VERSION ""

NS_ :

BS_:

BU_: RLPSU DPSU APSU PSB SHVU_RR vHS_B2 FCS EMCU SLB RCM CGW_CCU vDummy_HS_B ATS RLHV PFSU SGU ALBCU DSAU SWRC SHVU_FR RCS RRPSU BLTN_CAM SCM DLBCU OHCL RWPC RRHV WPC HOD ASAU

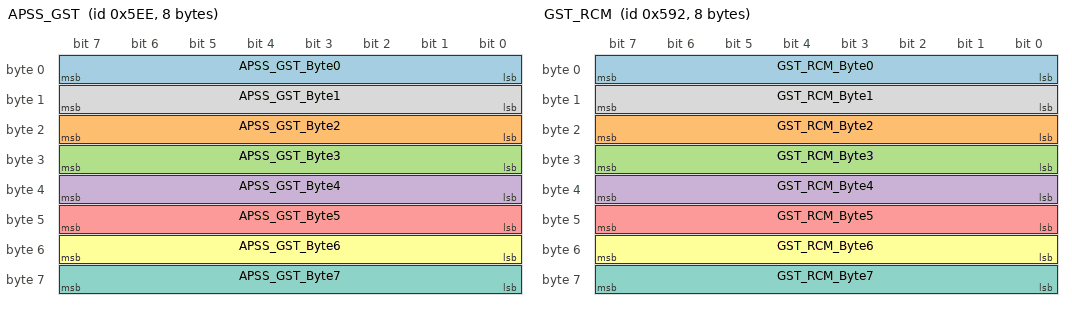
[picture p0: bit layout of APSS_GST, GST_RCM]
BO_ 1518 APSS_GST: 8 APSU
 SG_ APSS_GST_Byte0 : 0|8@1+ (1,0) [0|0] ""  CGW_CCU
 SG_ APSS_GST_Byte2 : 16|8@1+ (1,0) [0|0] ""  CGW_CCU
 SG_ APSS_GST_Byte3 : 24|8@1+ (1,0) [0|0] ""  CGW_CCU
 SG_ APSS_GST_Byte4 : 32|8@1+ (1,0) [0|0] ""  CGW_CCU
 SG_ APSS_GST_Byte5 : 40|8@1+ (1,0) [0|0] ""  CGW_CCU
 SG_ APSS_GST_Byte6 : 48|8@1+ (1,0) [0|0] ""  CGW_CCU
 SG_ APSS_GST_Byte7 : 56|8@1+ (1,0) [0|0] ""  CGW_CCU
 SG_ APSS_GST_Byte1 : 8|8@1+ (1,0) [0|0] ""  CGW_CCU

BO_ 1016 HU_GNSS_14_1000ms: 8 CGW_CCU
 SG_ GNSS_MM_type : 0|4@1+ (1,0) [0|0] ""  BLTN_CAM

BO_ 1426 GST_RCM: 8 CGW_CCU
 SG_ GST_RCM_Byte0 : 0|8@1+ (1,0) [0|0] ""  RCM
 SG_ GST_RCM_Byte2 : 16|8@1+ (1,0) [0|0] ""  RCM
 SG_ GST_RCM_Byte3 : 24|8@1+ (1,0) [0|0] ""  RCM
 SG_ GST_RCM_Byte4 : 32|8@1+ (1,0) [0|0] ""  RCM
 SG_ GST_RCM_Byte5 : 40|8@1+ (1,0) [0|0] ""  RCM
 SG_ GST_RCM_Byte6 : 48|8@1+ (1,0) [0|0] ""  RCM
 SG_ GST_RCM_Byte7 : 56|8@1+ (1,0) [0|0] ""  RCM
 SG_ GST_RCM_Byte1 : 8|8@1+ (1,0) [0|0] ""  RCM

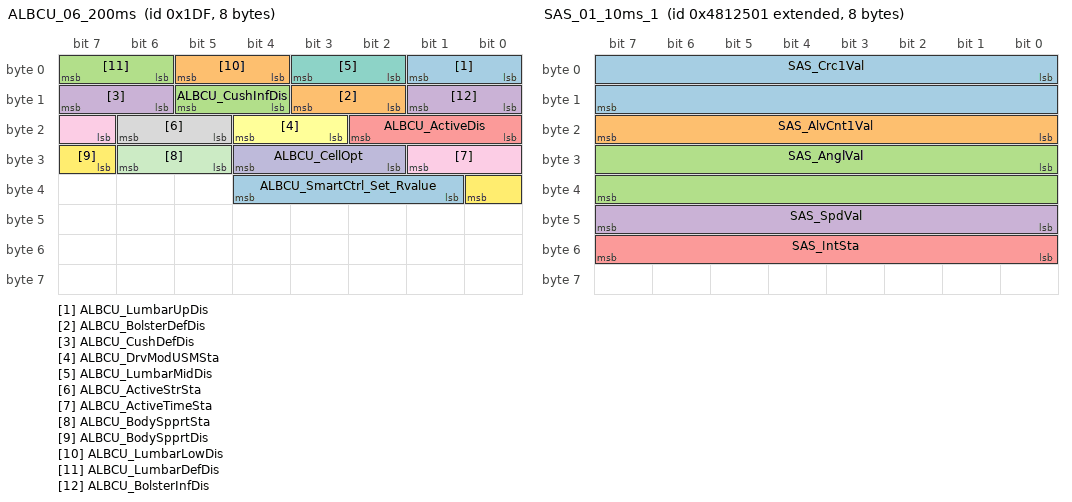
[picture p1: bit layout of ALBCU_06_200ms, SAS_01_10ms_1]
BO_ 479 ALBCU_06_200ms: 8 ALBCU
 SG_ ALBCU_LumbarUpDis : 0|2@1+ (1,0) [0|0] ""  Vector__XXX
 SG_ ALBCU_BolsterDefDis : 10|2@1+ (1,0) [0|0] ""  Vector__XXX
 SG_ ALBCU_CushInfDis : 12|2@1+ (1,0) [0|0] ""  Vector__XXX
 SG_ ALBCU_CushDefDis : 14|2@1+ (1,0) [0|0] ""  Vector__XXX
 SG_ ALBCU_ActiveDis : 16|3@1+ (1,0) [0|0] ""  CGW_CCU
 SG_ ALBCU_DrvModUSMSta : 19|2@1+ (1,0) [0|0] ""  CGW_CCU
 SG_ ALBCU_LumbarMidDis : 2|2@1+ (1,0) [0|0] ""  Vector__XXX
 SG_ ALBCU_ActiveStrSta : 21|2@1+ (1,0) [0|0] ""  CGW_CCU
 SG_ ALBCU_ActiveTimeSta : 23|3@1+ (1,0) [0|0] ""  CGW_CCU
 SG_ ALBCU_CellOpt : 26|3@1+ (1,0) [0|0] ""  CGW_CCU
 SG_ ALBCU_BodySpprtSta : 29|2@1+ (1,0) [0|0] ""  CGW_CCU
 SG_ ALBCU_BodySpprtDis : 31|2@1+ (1,0) [0|0] ""  Vector__XXX
 SG_ ALBCU_SmartCtrl_Set_Rvalue : 33|4@1+ (1,0) [0|0] ""  Vector__XXX
 SG_ ALBCU_LumbarLowDis : 4|2@1+ (1,0) [0|0] ""  Vector__XXX
 SG_ ALBCU_LumbarDefDis : 6|2@1+ (1,0) [0|0] ""  Vector__XXX
 SG_ ALBCU_BolsterInfDis : 8|2@1+ (1,0) [0|0] ""  Vector__XXX

BO_ 1019 HU_MOOD_E_01: 8 CGW_CCU
 SG_ HU_MoodTherapyDrSeat : 0|2@1+ (1,0) [0|0] ""  DSAU
 SG_ HU_VitalityFragrance : 10|2@1+ (1,0) [0|0] ""  Vector__XXX
 SG_ HU_VitalityCurtain : 12|2@1+ (1,0) [0|0] ""  Vector__XXX
 SG_ HU_DelightMoodLamp : 14|2@1+ (1,0) [0|0] ""  Vector__XXX
 SG_ HU_DelightFragrance : 16|2@1+ (1,0) [0|0] ""  Vector__XXX
 SG_ HU_DelightCurtain : 18|2@1+ (1,0) [0|0] ""  Vector__XXX
 SG_ HU_MoodTherapyPsSeat : 2|2@1+ (1,0) [0|0] ""  ASAU
 SG_ HU_CareMoodLamp : 20|2@1+ (1,0) [0|0] ""  Vector__XXX
 SG_ HU_CareFragrance : 22|2@1+ (1,0) [0|0] ""  Vector__XXX
 SG_ HU_CareMassage : 24|2@1+ (1,0) [0|0] ""  DSAU,ASAU
 SG_ HU_CareCurtain : 26|2@1+ (1,0) [0|0] ""  Vector__XXX
 SG_ HU_ComfortMoodLamp : 28|2@1+ (1,0) [0|0] ""  Vector__XXX
 SG_ HU_ComfortFragrance : 30|2@1+ (1,0) [0|0] ""  Vector__XXX
 SG_ HU_ComfortMassage : 32|2@1+ (1,0) [0|0] ""  DSAU,ASAU
 SG_ HU_ComfortCurtain : 34|2@1+ (1,0) [0|0] ""  Vector__XXX
 SG_ HU_MoodTherapyMode : 36|3@1+ (1,0) [0|0] ""  DSAU,ASAU
 SG_ HU_MoodTherapyRlSeat : 4|2@1+ (1,0) [0|0] ""  Vector__XXX
 SG_ HU_MoodTherapyRrSeat : 6|2@1+ (1,0) [0|0] ""  Vector__XXX
 SG_ HU_VitalityMoodLamp : 8|2@1+ (1,0) [0|0] ""  Vector__XXX

BO_ 2223056129 SAS_01_10ms_1: 8 CGW_CCU
 SG_ SAS_Crc1Val : 0|16@1+ (1,0) [0|0] ""  PSB
 SG_ SAS_AlvCnt1Val : 16|8@1+ (1,0) [0|0] ""  PSB
 SG_ SAS_AnglVal : 24|16@1- (0.1,0) [0|0] "Deg"  PSB,BLTN_CAM
 SG_ SAS_SpdVal : 40|8@1+ (4,0) [0|0] "Deg/s"  Vector__XXX
 SG_ SAS_IntSta : 48|8@1+ (1,0) [0|0] ""  PSB

BO_ 2235651330 APSB_01_10ms_2: 8 CGW_CCU

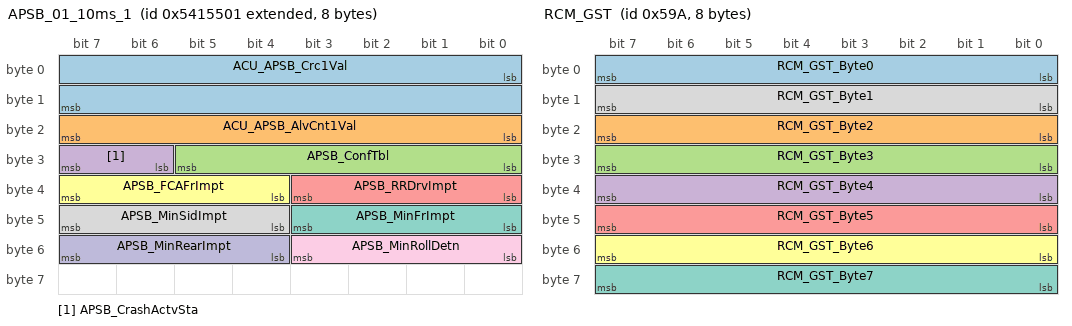
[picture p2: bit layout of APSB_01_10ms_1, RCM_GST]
BO_ 2235651329 APSB_01_10ms_1: 8 CGW_CCU
 SG_ ACU_APSB_Crc1Val : 0|16@1+ (1,0) [0|0] ""  PSB
 SG_ ACU_APSB_AlvCnt1Val : 16|8@1+ (1,0) [0|0] ""  PSB
 SG_ APSB_ConfTbl : 24|6@1+ (1,0) [0|0] ""  PSB
 SG_ APSB_CrashActvSta : 30|2@1+ (1,0) [0|0] ""  PSB
 SG_ APSB_RRDrvImpt : 32|4@1+ (1,0) [0|0] ""  PSB
 SG_ APSB_FCAFrImpt : 36|4@1+ (1,0) [0|0] ""  PSB
 SG_ APSB_MinFrImpt : 40|4@1+ (1,0) [0|0] ""  PSB
 SG_ APSB_MinSidImpt : 44|4@1+ (1,0) [0|0] ""  PSB
 SG_ APSB_MinRollDetn : 48|4@1+ (1,0) [0|0] ""  PSB
 SG_ APSB_MinRearImpt : 52|4@1+ (1,0) [0|0] ""  PSB

BO_ 2223056130 SAS_01_10ms_2: 8 CGW_CCU

BO_ 1434 RCM_GST: 8 RCM
 SG_ RCM_GST_Byte0 : 0|8@1+ (1,0) [0|0] ""  CGW_CCU
 SG_ RCM_GST_Byte2 : 16|8@1+ (1,0) [0|0] ""  CGW_CCU
 SG_ RCM_GST_Byte3 : 24|8@1+ (1,0) [0|0] ""  CGW_CCU
 SG_ RCM_GST_Byte4 : 32|8@1+ (1,0) [0|0] ""  CGW_CCU
 SG_ RCM_GST_Byte5 : 40|8@1+ (1,0) [0|0] ""  CGW_CCU
 SG_ RCM_GST_Byte6 : 48|8@1+ (1,0) [0|0] ""  CGW_CCU
 SG_ RCM_GST_Byte7 : 56|8@1+ (1,0) [0|0] ""  CGW_CCU
 SG_ RCM_GST_Byte1 : 8|8@1+ (1,0) [0|0] ""  CGW_CCU

BO_ 1015 HU_GNSS_13_1000ms: 8 CGW_CCU
 SG_ HU_MM_Altitude : 0|32@1- (0.01,0) [0|0] "m"  BLTN_CAM
 SG_ HU_MM_Heading : 32|32@1+ (1,0) [0|0] "¢ª"  BLTN_CAM

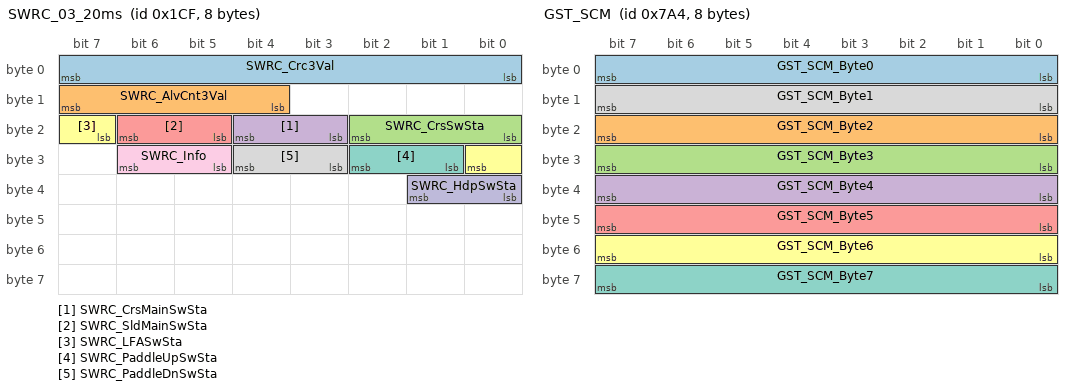
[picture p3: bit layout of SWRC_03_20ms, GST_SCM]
BO_ 463 SWRC_03_20ms: 8 SWRC
 SG_ SWRC_Crc3Val : 0|8@1+ (1,0) [0|0] ""  CGW_CCU
 SG_ SWRC_AlvCnt3Val : 12|4@1+ (1,0) [0|0] ""  CGW_CCU
 SG_ SWRC_CrsSwSta : 16|3@1+ (1,0) [0|0] ""  CGW_CCU
 SG_ SWRC_CrsMainSwSta : 19|2@1+ (1,0) [0|0] ""  CGW_CCU
 SG_ SWRC_SldMainSwSta : 21|2@1+ (1,0) [0|0] ""  CGW_CCU
 SG_ SWRC_LFASwSta : 23|2@1+ (1,0) [0|0] ""  CGW_CCU
 SG_ SWRC_PaddleUpSwSta : 25|2@1+ (1,0) [0|0] ""  CGW_CCU
 SG_ SWRC_PaddleDnSwSta : 27|2@1+ (1,0) [0|0] ""  CGW_CCU
 SG_ SWRC_Info : 29|2@1+ (1,0) [0|0] ""  CGW_CCU
 SG_ SWRC_HdpSwSta : 32|2@1+ (1,0) [0|0] ""  CGW_CCU

BO_ 1956 GST_SCM: 8 CGW_CCU
 SG_ GST_SCM_Byte0 : 0|8@1+ (1,0) [0|0] ""  SCM
 SG_ GST_SCM_Byte2 : 16|8@1+ (1,0) [0|0] ""  SCM
 SG_ GST_SCM_Byte3 : 24|8@1+ (1,0) [0|0] ""  SCM
 SG_ GST_SCM_Byte4 : 32|8@1+ (1,0) [0|0] ""  SCM
 SG_ GST_SCM_Byte5 : 40|8@1+ (1,0) [0|0] ""  SCM
 SG_ GST_SCM_Byte6 : 48|8@1+ (1,0) [0|0] ""  SCM
 SG_ GST_SCM_Byte7 : 56|8@1+ (1,0) [0|0] ""  SCM
 SG_ GST_SCM_Byte1 : 8|8@1+ (1,0) [0|0] ""  SCM

BO_ 1003 RLPSM_01_200ms: 8 RRPSU
 SG_ PSM_BzrOnRLReq : 0|2@1+ (1,0) [0|0] ""  ATS,DPSU,DPSU
 SG_ RLPSM_RearModeState : 10|3@1+ (1,0) [0|0] ""  ATS,OHCL,CGW_CCU,CGW_CCU
 SG_ RLPSM_RrLfSldStrtSta : 13|2@1+ (1,0) [0|0] ""  Vector__XXX
 SG_ RLPSM_OptTyp : 16|2@1+ (1,0) [0|0] ""  Vector__XXX
 SG_ RLPSM_RLStEsyAcsUSMSta : 18|2@1+ (1,0) [0|0] ""  ATS,CGW_CCU,CGW_CCU
 SG_ RLPSM_FnshSta : 2|2@1+ (1,0) [0|0] ""  Vector__XXX
 SG_ RLPSM_AllSeatPosPlyBck_Sta : 20|3@1+ (1,0) [0|0] ""  CGW_CCU
 SG_ RLPSM_RLSlidePosition : 24|8@1+ (1,0) [0|0] ""  RRPSU
 SG_ RLPSM_SeatPos_Sta : 32|3@1+ (1,0) [0|0] ""  RLPSU,RRPSU
 SG_ RLPSM_SeatPosSldLmt_Sta : 35|2@1+ (1,0) [0|0] ""  Vector__XXX
 SG_ RLPSM_Enable_Sta : 37|3@1+ (1,0) [0|0] ""  Vector__XXX
 SG_ RLPSM_MvSta : 4|2@1+ (1,0) [0|0] ""  Vector__XXX
 SG_ RLPSM_Mem1_Sta : 40|2@1+ (1,0) [0|0] ""  Vector__XXX
 SG_ RLPSM_Mem2_Sta : 42|2@1+ (1,0) [0|0] ""  Vector__XXX
 SG_ RLPSM_Mem3_Sta : 44|2@1+ (1,0) [0|0] ""  Vector__XXX
 SG_ RLPSM_LimSetSta : 48|2@1+ (1,0) [0|0] ""  Vector__XXX
 SG_ PSM_RrLftSldPosVal : 6|2@1+ (1,0) [0|0] ""  Vector__XXX
 SG_ PSM_SldStrtSta : 8|2@1+ (1,0) [0|0] ""  Vector__XXX

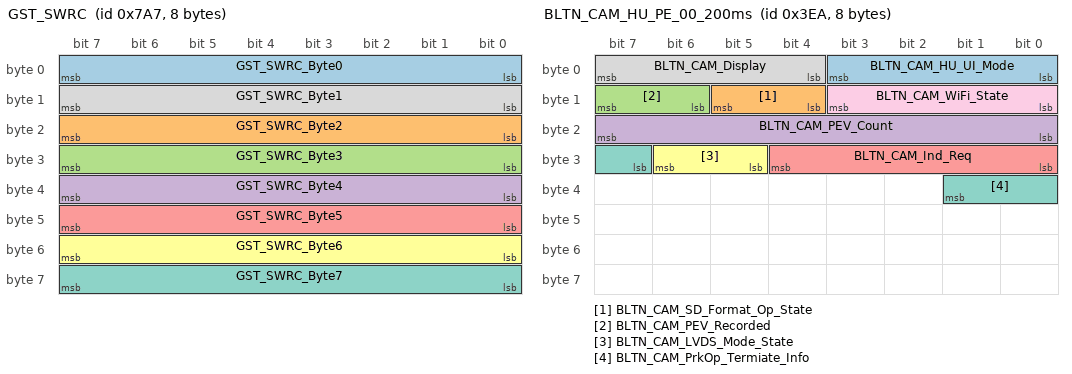
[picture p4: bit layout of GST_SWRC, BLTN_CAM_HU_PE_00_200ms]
BO_ 1959 GST_SWRC: 8 CGW_CCU
 SG_ GST_SWRC_Byte0 : 0|8@1+ (1,0) [0|0] ""  SWRC
 SG_ GST_SWRC_Byte2 : 16|8@1+ (1,0) [0|0] ""  SWRC
 SG_ GST_SWRC_Byte3 : 24|8@1+ (1,0) [0|0] ""  SWRC
 SG_ GST_SWRC_Byte4 : 32|8@1+ (1,0) [0|0] ""  SWRC
 SG_ GST_SWRC_Byte5 : 40|8@1+ (1,0) [0|0] ""  SWRC
 SG_ GST_SWRC_Byte6 : 48|8@1+ (1,0) [0|0] ""  SWRC
 SG_ GST_SWRC_Byte7 : 56|8@1+ (1,0) [0|0] ""  SWRC
 SG_ GST_SWRC_Byte1 : 8|8@1+ (1,0) [0|0] ""  SWRC

BO_ 1002 BLTN_CAM_HU_PE_00_200ms: 8 BLTN_CAM
 SG_ BLTN_CAM_HU_UI_Mode : 0|4@1+ (1,0) [0|0] ""  CGW_CCU
 SG_ BLTN_CAM_SD_Format_Op_State : 12|2@1+ (1,0) [0|0] ""  CGW_CCU
 SG_ BLTN_CAM_PEV_Recorded : 14|2@1+ (1,0) [0|0] ""  CGW_CCU
 SG_ BLTN_CAM_PEV_Count : 16|8@1+ (1,0) [0|0] ""  CGW_CCU
 SG_ BLTN_CAM_Ind_Req : 24|5@1+ (1,0) [0|0] ""  CGW_CCU
 SG_ BLTN_CAM_LVDS_Mode_State : 29|2@1+ (1,0) [0|0] ""  CGW_CCU
 SG_ BLTN_CAM_PrkOp_Termiate_Info : 31|3@1+ (1,0) [0|0] ""  CGW_CCU
 SG_ BLTN_CAM_Display : 4|4@1+ (1,0) [0|0] ""  CGW_CCU
 SG_ BLTN_CAM_WiFi_State : 8|4@1+ (1,0) [0|0] ""  CGW_CCU

BO_ 1005 RLPSU_01_200ms: 8 RRPSU
 SG_ RLPSU_FldDis : 0|2@1+ (1,0) [0|0] ""  CGW_CCU
 SG_ RLPSU_TiltDownDis : 10|2@1+ (1,0) [0|0] ""  CGW_CCU
 SG_ RLPSU_RclFwdDis : 12|2@1+ (1,0) [0|0] ""  CGW_CCU
 SG_ RLPSU_RclBwdDis : 14|2@1+ (1,0) [0|0] ""  CGW_CCU
 SG_ RLPSU_RlxModeDis : 16|2@1+ (1,0) [0|0] ""  Vector__XXX
 SG_ RLPSU_Folding_SW : 18|2@1+ (1,0) [0|0] ""  Vector__XXX
 SG_ RLPSU_UnFldDis : 2|2@1+ (1,0) [0|0] ""  Vector__XXX
 SG_ RLPSU_Unfolding_SW : 20|2@1+ (1,0) [0|0] ""  Vector__XXX
 SG_ RLPSU_WalkIn_SW : 22|2@1+ (1,0) [0|0] ""  Vector__XXX
 SG_ RLPSU_UnwalkIn_SW : 24|2@1+ (1,0) [0|0] ""  Vector__XXX
 SG_ RLPSU_Folding_Postion : 26|4@1+ (1,0) [0|0] ""  CGW_CCU
 SG_ RLPSU_Folding_State_PopUp : 30|3@1+ (1,0) [0|0] ""  CGW_CCU
 SG_ RLPSU_Relax_State_Popup : 33|3@1+ (1,0) [0|0] ""  CGW_CCU
 SG_ RLPSU_SlideFwdDis : 36|2@1+ (1,0) [0|0] ""  CGW_CCU
 SG_ RLPSU_SlideBwdDis : 38|2@1+ (1,0) [0|0] ""  CGW_CCU
 SG_ RLPSU_WalkInDis : 4|2@1+ (1,0) [0|0] ""  Vector__XXX
 SG_ RLPSU_WalkInState : 40|2@1+ (1,0) [0|0] ""  Vector__XXX
 SG_ RLPSU_UnWalkInDis : 6|2@1+ (1,0) [0|0] ""  Vector__XXX
 SG_ RLPSU_TiltUpDis : 8|2@1+ (1,0) [0|0] ""  CGW_CCU

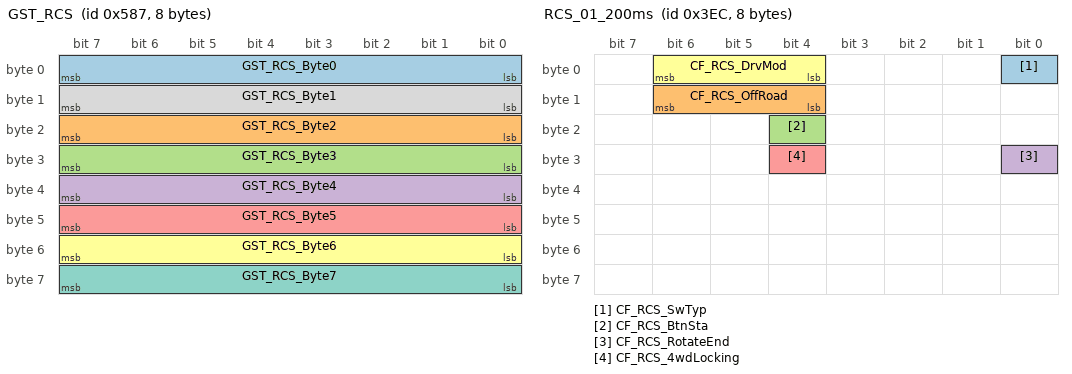
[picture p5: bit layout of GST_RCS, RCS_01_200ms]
BO_ 1415 GST_RCS: 8 CGW_CCU
 SG_ GST_RCS_Byte0 : 0|8@1+ (1,0) [0|0] ""  RCS
 SG_ GST_RCS_Byte2 : 16|8@1+ (1,0) [0|0] ""  RCS
 SG_ GST_RCS_Byte3 : 24|8@1+ (1,0) [0|0] ""  RCS
 SG_ GST_RCS_Byte4 : 32|8@1+ (1,0) [0|0] ""  RCS
 SG_ GST_RCS_Byte5 : 40|8@1+ (1,0) [0|0] ""  RCS
 SG_ GST_RCS_Byte6 : 48|8@1+ (1,0) [0|0] ""  RCS
 SG_ GST_RCS_Byte7 : 56|8@1+ (1,0) [0|0] ""  RCS
 SG_ GST_RCS_Byte1 : 8|8@1+ (1,0) [0|0] ""  RCS

BO_ 1004 RCS_01_200ms: 8 RCS
 SG_ CF_RCS_SwTyp : 0|1@1+ (1,0) [0|0] "Watt"  CGW_CCU
 SG_ CF_RCS_OffRoad : 12|3@1+ (1,0) [0|0] "Watt"  CGW_CCU
 SG_ CF_RCS_BtnSta : 20|1@1+ (1,0) [0|0] "Watt"  CGW_CCU
 SG_ CF_RCS_RotateEnd : 24|1@1+ (1,0) [0|0] "Watt"  CGW_CCU
 SG_ CF_RCS_4wdLocking : 28|1@1+ (1,0) [0|0] "Watt"  CGW_CCU
 SG_ CF_RCS_DrvMod : 4|3@1+ (1,0) [0|0] "Watt"  CGW_CCU

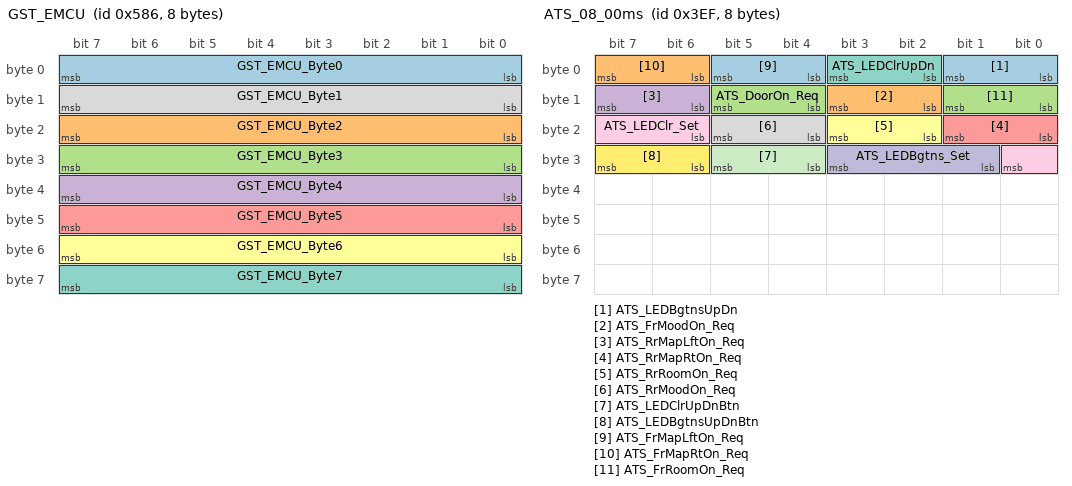
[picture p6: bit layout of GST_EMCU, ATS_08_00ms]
BO_ 1414 GST_EMCU: 8 CGW_CCU
 SG_ GST_EMCU_Byte0 : 0|8@1+ (1,0) [0|0] ""  EMCU
 SG_ GST_EMCU_Byte2 : 16|8@1+ (1,0) [0|0] ""  EMCU
 SG_ GST_EMCU_Byte3 : 24|8@1+ (1,0) [0|0] ""  EMCU
 SG_ GST_EMCU_Byte4 : 32|8@1+ (1,0) [0|0] ""  EMCU
 SG_ GST_EMCU_Byte5 : 40|8@1+ (1,0) [0|0] ""  EMCU
 SG_ GST_EMCU_Byte6 : 48|8@1+ (1,0) [0|0] ""  EMCU
 SG_ GST_EMCU_Byte7 : 56|8@1+ (1,0) [0|0] ""  EMCU
 SG_ GST_EMCU_Byte1 : 8|8@1+ (1,0) [0|0] ""  EMCU

BO_ 1007 ATS_08_00ms: 8 ATS
 SG_ ATS_LEDBgtnsUpDn : 0|2@1+ (1,0) [0|0] ""  OHCL
 SG_ ATS_FrMoodOn_Req : 10|2@1+ (1,0) [0|0] ""  OHCL
 SG_ ATS_DoorOn_Req : 12|2@1+ (1,0) [0|0] ""  OHCL
 SG_ ATS_RrMapLftOn_Req : 14|2@1+ (1,0) [0|0] ""  OHCL
 SG_ ATS_RrMapRtOn_Req : 16|2@1+ (1,0) [0|0] ""  OHCL
 SG_ ATS_RrRoomOn_Req : 18|2@1+ (1,0) [0|0] ""  OHCL
 SG_ ATS_LEDClrUpDn : 2|2@1+ (1,0) [0|0] ""  OHCL
 SG_ ATS_RrMoodOn_Req : 20|2@1+ (1,0) [0|0] ""  OHCL
 SG_ ATS_LEDClr_Set : 22|3@1+ (1,0) [0|0] ""  OHCL
 SG_ ATS_LEDBgtns_Set : 25|3@1+ (1,0) [0|0] ""  OHCL
 SG_ ATS_LEDClrUpDnBtn : 28|2@1+ (1,0) [0|0] ""  Vector__XXX
 SG_ ATS_LEDBgtnsUpDnBtn : 30|2@1+ (1,0) [0|0] ""  Vector__XXX
 SG_ ATS_FrMapLftOn_Req : 4|2@1+ (1,0) [0|0] ""  OHCL
 SG_ ATS_FrMapRtOn_Req : 6|2@1+ (1,0) [0|0] ""  OHCL
 SG_ ATS_FrRoomOn_Req : 8|2@1+ (1,0) [0|0] ""  OHCL

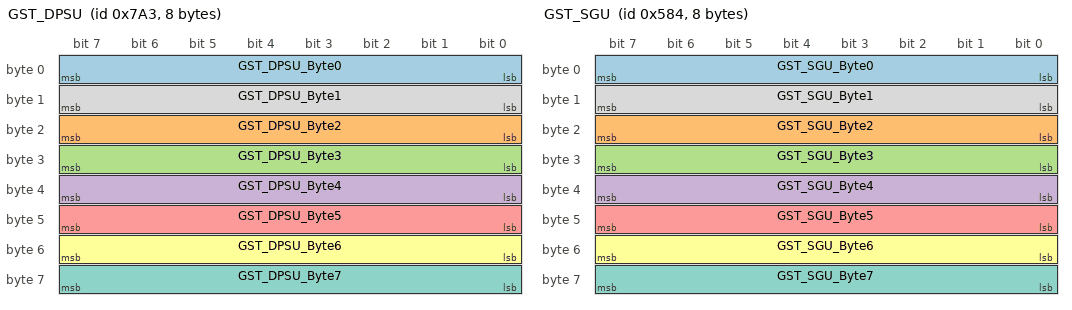
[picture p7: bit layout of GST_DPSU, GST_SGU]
BO_ 1955 GST_DPSU: 8 CGW_CCU
 SG_ GST_DPSU_Byte0 : 0|8@1+ (1,0) [0|0] ""  DPSU
 SG_ GST_DPSU_Byte2 : 16|8@1+ (1,0) [0|0] ""  DPSU
 SG_ GST_DPSU_Byte3 : 24|8@1+ (1,0) [0|0] ""  DPSU
 SG_ GST_DPSU_Byte4 : 32|8@1+ (1,0) [0|0] ""  DPSU
 SG_ GST_DPSU_Byte5 : 40|8@1+ (1,0) [0|0] ""  DPSU
 SG_ GST_DPSU_Byte6 : 48|8@1+ (1,0) [0|0] ""  DPSU
 SG_ GST_DPSU_Byte7 : 56|8@1+ (1,0) [0|0] ""  DPSU
 SG_ GST_DPSU_Byte1 : 8|8@1+ (1,0) [0|0] ""  DPSU

BO_ 1006 RRPSU_01_200ms: 8 RRPSU
 SG_ RRPSU_FldDis : 0|2@1+ (1,0) [0|0] ""  CGW_CCU
 SG_ RRPSU_TiltDnDis : 10|2@1+ (1,0) [0|0] ""  CGW_CCU
 SG_ RRPSU_RecFwdDis : 12|2@1+ (1,0) [0|0] ""  CGW_CCU
 SG_ RRPSU_RecBwdDis : 14|2@1+ (1,0) [0|0] ""  CGW_CCU
 SG_ RRPSU_RlxModeDis : 16|2@1+ (1,0) [0|0] ""  Vector__XXX
 SG_ RRPSU_Folding_SW : 18|2@1+ (1,0) [0|0] ""  Vector__XXX
 SG_ RRPSU_UnFldDis : 2|2@1+ (1,0) [0|0] ""  Vector__XXX
 SG_ RRPSU_Unfolding_SW : 20|2@1+ (1,0) [0|0] ""  Vector__XXX
 SG_ RRPSU_WalkIn_SW : 22|2@1+ (1,0) [0|0] ""  Vector__XXX
 SG_ RRPSU_UnwalkIn_SW : 24|2@1+ (1,0) [0|0] ""  Vector__XXX
 SG_ RRPSU_Folding_Postion : 26|4@1+ (1,0) [0|0] ""  CGW_CCU
 SG_ RRPSU_Folding_State_Popup : 30|3@1+ (1,0) [0|0] ""  CGW_CCU
 SG_ RRPSU_Relax_State_Popup : 33|3@1+ (1,0) [0|0] ""  CGW_CCU
 SG_ RRPSU_SlideFwdDis : 36|2@1+ (1,0) [0|0] ""  CGW_CCU
 SG_ RRPSU_SlideBwdDis : 38|2@1+ (1,0) [0|0] ""  CGW_CCU
 SG_ RRPSU_WalkinDis : 4|2@1+ (1,0) [0|0] ""  Vector__XXX
 SG_ RRPSU_WalkInState : 40|2@1+ (1,0) [0|0] ""  Vector__XXX
 SG_ RRPSU_UnwalkinDis : 6|2@1+ (1,0) [0|0] ""  Vector__XXX
 SG_ RRPSU_TiltUpDis : 8|2@1+ (1,0) [0|0] ""  CGW_CCU

BO_ 1412 GST_SGU: 8 CGW_CCU
 SG_ GST_SGU_Byte0 : 0|8@1+ (1,0) [0|0] ""  SGU
 SG_ GST_SGU_Byte2 : 16|8@1+ (1,0) [0|0] ""  SGU
 SG_ GST_SGU_Byte3 : 24|8@1+ (1,0) [0|0] ""  SGU
 SG_ GST_SGU_Byte4 : 32|8@1+ (1,0) [0|0] ""  SGU
 SG_ GST_SGU_Byte5 : 40|8@1+ (1,0) [0|0] ""  SGU
 SG_ GST_SGU_Byte6 : 48|8@1+ (1,0) [0|0] ""  SGU
 SG_ GST_SGU_Byte7 : 56|8@1+ (1,0) [0|0] ""  SGU
 SG_ GST_SGU_Byte1 : 8|8@1+ (1,0) [0|0] ""  SGU

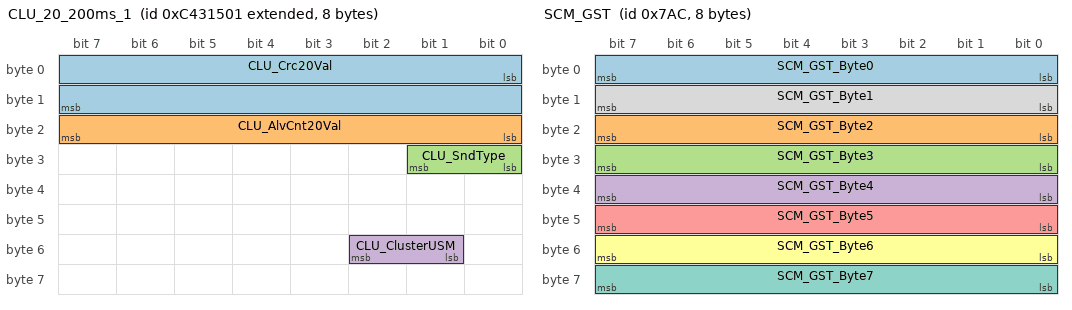
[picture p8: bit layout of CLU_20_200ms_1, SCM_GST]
BO_ 2353206529 CLU_20_200ms_1: 8 CGW_CCU
 SG_ CLU_Crc20Val : 0|16@1+ (1,0) [0|0] ""  Vector__XXX
 SG_ CLU_AlvCnt20Val : 16|8@1+ (1,0) [0|0] ""  Vector__XXX
 SG_ CLU_SndType : 24|2@1- (1,0) [0|0] ""  Vector__XXX
 SG_ CLU_ClusterUSM : 49|2@1+ (1,0) [0|0] ""  WPC

BO_ 1964 SCM_GST: 8 SCM
 SG_ SCM_GST_Byte0 : 0|8@1+ (1,0) [0|0] ""  CGW_CCU
 SG_ SCM_GST_Byte2 : 16|8@1+ (1,0) [0|0] ""  CGW_CCU
 SG_ SCM_GST_Byte3 : 24|8@1+ (1,0) [0|0] ""  CGW_CCU
 SG_ SCM_GST_Byte4 : 32|8@1+ (1,0) [0|0] ""  CGW_CCU
 SG_ SCM_GST_Byte5 : 40|8@1+ (1,0) [0|0] ""  CGW_CCU
 SG_ SCM_GST_Byte6 : 48|8@1+ (1,0) [0|0] ""  CGW_CCU
 SG_ SCM_GST_Byte7 : 56|8@1+ (1,0) [0|0] ""  CGW_CCU
 SG_ SCM_GST_Byte1 : 8|8@1+ (1,0) [0|0] ""  CGW_CCU

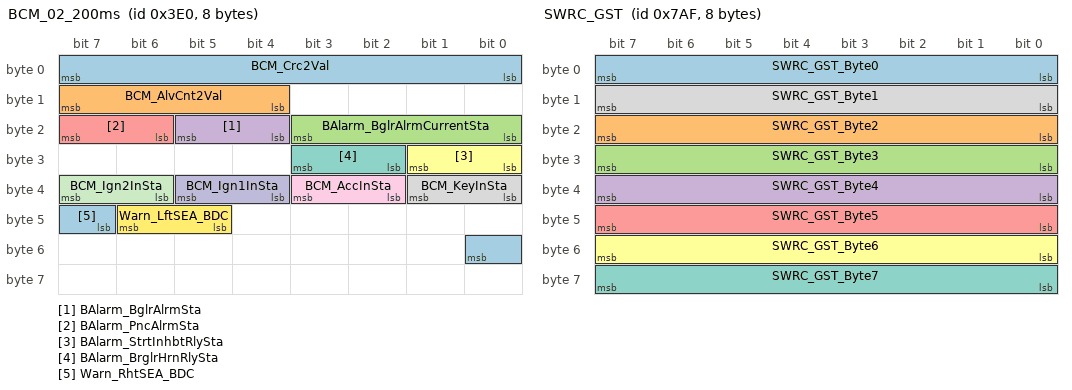
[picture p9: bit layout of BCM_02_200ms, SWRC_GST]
BO_ 992 BCM_02_200ms: 8 CGW_CCU
 SG_ BCM_Crc2Val : 0|8@1+ (1,0) [0|0] ""  Vector__XXX
 SG_ BCM_AlvCnt2Val : 12|4@1+ (1,0) [0|0] ""  Vector__XXX
 SG_ BAlarm_BglrAlrmCurrentSta : 16|4@1+ (1,0) [0|0] ""  BLTN_CAM
 SG_ BAlarm_BglrAlrmSta : 20|2@1+ (1,0) [0|0] ""  Vector__XXX
 SG_ BAlarm_PncAlrmSta : 22|2@1+ (1,0) [0|0] ""  Vector__XXX
 SG_ BAlarm_StrtInhbtRlySta : 24|2@1+ (1,0) [0|0] ""  Vector__XXX
 SG_ BAlarm_BrglrHrnRlySta : 26|2@1+ (1,0) [0|0] ""  Vector__XXX
 SG_ BCM_KeyInSta : 32|2@1+ (1,0) [0|0] ""  SWRC,APSU,SHVU_FR,SHVU_RR,DPSU,DLBCU,SGU,ALBCU
 SG_ BCM_AccInSta : 34|2@1+ (1,0) [0|0] ""  SWRC,APSU,SHVU_FR,SHVU_RR,DPSU,DLBCU,RRPSU,RLPSU,ATS,DSAU,ASAU,SGU,ALBCU
 SG_ BCM_Ign1InSta : 36|2@1+ (1,0) [0|0] ""  SCM,SWRC,APSU,RLHV,RRHV,SHVU_FR,SHVU_RR,DPSU,DLBCU,PFSU,RRPSU,RLPSU,HOD,ATS,DSAU,ASAU,SGU,ALBCU
 SG_ BCM_Ign2InSta : 38|2@1+ (1,0) [0|0] ""  SCM,SWRC,APSU,RLHV,RRHV,SHVU_FR,SHVU_RR,DPSU,DLBCU,PFSU,RRPSU,RLPSU,ATS,DSAU,ASAU,SGU,ALBCU
 SG_ Warn_LftSEA_BDC : 45|2@1+ (1,0) [0|0] ""  Vector__XXX
 SG_ Warn_RhtSEA_BDC : 47|2@1+ (1,0) [0|0] ""  Vector__XXX

BO_ 1967 SWRC_GST: 8 SWRC
 SG_ SWRC_GST_Byte0 : 0|8@1+ (1,0) [0|0] ""  CGW_CCU
 SG_ SWRC_GST_Byte2 : 16|8@1+ (1,0) [0|0] ""  CGW_CCU
 SG_ SWRC_GST_Byte3 : 24|8@1+ (1,0) [0|0] ""  CGW_CCU
 SG_ SWRC_GST_Byte4 : 32|8@1+ (1,0) [0|0] ""  CGW_CCU
 SG_ SWRC_GST_Byte5 : 40|8@1+ (1,0) [0|0] ""  CGW_CCU
 SG_ SWRC_GST_Byte6 : 48|8@1+ (1,0) [0|0] ""  CGW_CCU
 SG_ SWRC_GST_Byte7 : 56|8@1+ (1,0) [0|0] ""  CGW_CCU
 SG_ SWRC_GST_Byte1 : 8|8@1+ (1,0) [0|0] ""  CGW_CCU

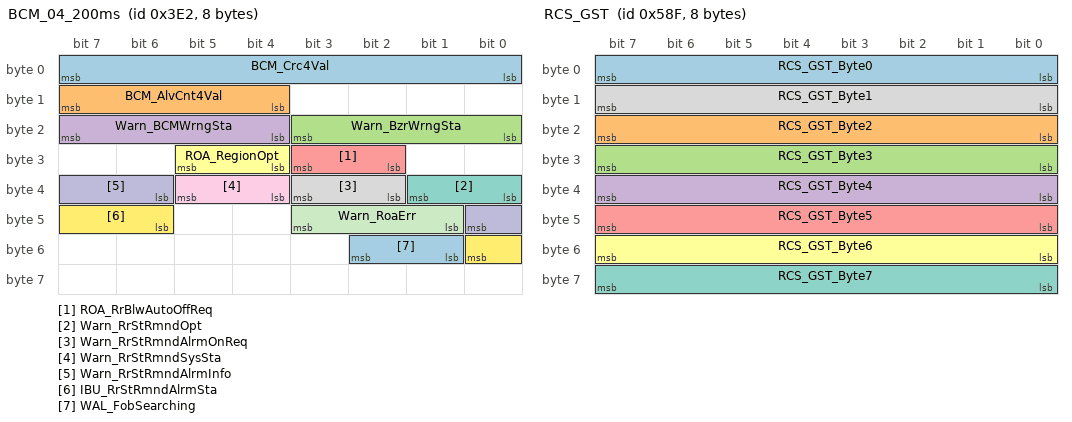
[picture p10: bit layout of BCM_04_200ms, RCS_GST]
BO_ 994 BCM_04_200ms: 8 CGW_CCU
 SG_ BCM_Crc4Val : 0|8@1+ (1,0) [0|0] ""  Vector__XXX
 SG_ BCM_AlvCnt4Val : 12|4@1+ (1,0) [0|0] ""  Vector__XXX
 SG_ Warn_BzrWrngSta : 16|4@1+ (1,0) [0|0] ""  Vector__XXX
 SG_ Warn_BCMWrngSta : 20|4@1+ (1,0) [0|0] ""  Vector__XXX
 SG_ ROA_RrBlwAutoOffReq : 26|2@1+ (1,0) [0|0] ""  Vector__XXX
 SG_ ROA_RegionOpt : 28|2@1+ (1,0) [0|0] ""  Vector__XXX
 SG_ Warn_RrStRmndOpt : 32|2@1+ (1,0) [0|0] ""  Vector__XXX
 SG_ Warn_RrStRmndAlrmOnReq : 34|2@1+ (1,0) [0|0] ""  Vector__XXX
 SG_ Warn_RrStRmndSysSta : 36|2@1+ (1,0) [0|0] ""  Vector__XXX
 SG_ Warn_RrStRmndAlrmInfo : 38|3@1+ (1,0) [0|0] ""  SWRC
 SG_ Warn_RoaErr : 41|3@1+ (1,0) [0|0] ""  Vector__XXX
 SG_ IBU_RrStRmndAlrmSta : 46|3@1+ (1,0) [0|0] ""  Vector__XXX
 SG_ WAL_FobSearching : 49|2@1+ (1,0) [0|0] ""  Vector__XXX

BO_ 2353206530 CLU_20_200ms_2: 8 CGW_CCU

BO_ 1423 RCS_GST: 8 RCS
 SG_ RCS_GST_Byte0 : 0|8@1+ (1,0) [0|0] ""  CGW_CCU
 SG_ RCS_GST_Byte2 : 16|8@1+ (1,0) [0|0] ""  CGW_CCU
 SG_ RCS_GST_Byte3 : 24|8@1+ (1,0) [0|0] ""  CGW_CCU
 SG_ RCS_GST_Byte4 : 32|8@1+ (1,0) [0|0] ""  CGW_CCU
 SG_ RCS_GST_Byte5 : 40|8@1+ (1,0) [0|0] ""  CGW_CCU
 SG_ RCS_GST_Byte6 : 48|8@1+ (1,0) [0|0] ""  CGW_CCU
 SG_ RCS_GST_Byte7 : 56|8@1+ (1,0) [0|0] ""  CGW_CCU
 SG_ RCS_GST_Byte1 : 8|8@1+ (1,0) [0|0] ""  CGW_CCU

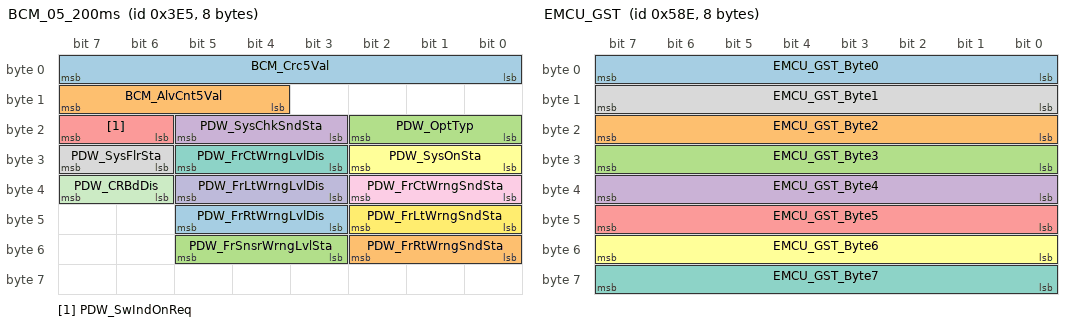
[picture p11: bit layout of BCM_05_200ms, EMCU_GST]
BO_ 997 BCM_05_200ms: 8 CGW_CCU
 SG_ BCM_Crc5Val : 0|8@1+ (1,0) [0|0] ""  Vector__XXX
 SG_ BCM_AlvCnt5Val : 12|4@1+ (1,0) [0|0] ""  Vector__XXX
 SG_ PDW_OptTyp : 16|3@1+ (1,0) [0|0] ""  Vector__XXX
 SG_ PDW_SysChkSndSta : 19|3@1+ (1,0) [0|0] ""  Vector__XXX
 SG_ PDW_SwIndOnReq : 22|2@1+ (1,0) [0|0] ""  FCS
 SG_ PDW_SysOnSta : 24|3@1+ (1,0) [0|0] ""  Vector__XXX
 SG_ PDW_FrCtWrngLvlDis : 27|3@1+ (1,0) [0|0] ""  Vector__XXX
 SG_ PDW_SysFlrSta : 30|2@1+ (1,0) [0|0] ""  Vector__XXX
 SG_ PDW_FrCtWrngSndSta : 32|3@1+ (1,0) [0|0] ""  Vector__XXX
 SG_ PDW_FrLtWrngLvlDis : 35|3@1+ (1,0) [0|0] ""  Vector__XXX
 SG_ PDW_CRBdDis : 38|2@1+ (1,0) [0|0] ""  Vector__XXX
 SG_ PDW_FrLtWrngSndSta : 40|3@1+ (1,0) [0|0] ""  Vector__XXX
 SG_ PDW_FrRtWrngLvlDis : 43|3@1+ (1,0) [0|0] ""  Vector__XXX
 SG_ PDW_FrRtWrngSndSta : 48|3@1+ (1,0) [0|0] ""  Vector__XXX
 SG_ PDW_FrSnsrWrngLvlSta : 51|3@1+ (1,0) [0|0] ""  Vector__XXX

BO_ 1422 EMCU_GST: 8 EMCU
 SG_ EMCU_GST_Byte0 : 0|8@1+ (1,0) [0|0] ""  CGW_CCU
 SG_ EMCU_GST_Byte2 : 16|8@1+ (1,0) [0|0] ""  CGW_CCU
 SG_ EMCU_GST_Byte3 : 24|8@1+ (1,0) [0|0] ""  CGW_CCU
 SG_ EMCU_GST_Byte4 : 32|8@1+ (1,0) [0|0] ""  CGW_CCU
 SG_ EMCU_GST_Byte5 : 40|8@1+ (1,0) [0|0] ""  CGW_CCU
 SG_ EMCU_GST_Byte6 : 48|8@1+ (1,0) [0|0] ""  CGW_CCU
 SG_ EMCU_GST_Byte7 : 56|8@1+ (1,0) [0|0] ""  CGW_CCU
 SG_ EMCU_GST_Byte1 : 8|8@1+ (1,0) [0|0] ""  CGW_CCU

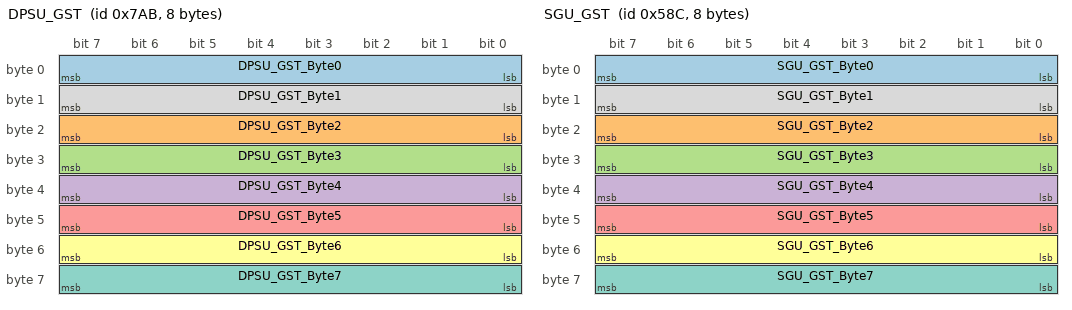
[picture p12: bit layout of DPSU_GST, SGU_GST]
BO_ 1963 DPSU_GST: 8 DPSU
 SG_ DPSU_GST_Byte0 : 0|8@1+ (1,0) [0|0] ""  CGW_CCU
 SG_ DPSU_GST_Byte2 : 16|8@1+ (1,0) [0|0] ""  CGW_CCU
 SG_ DPSU_GST_Byte3 : 24|8@1+ (1,0) [0|0] ""  CGW_CCU
 SG_ DPSU_GST_Byte4 : 32|8@1+ (1,0) [0|0] ""  CGW_CCU
 SG_ DPSU_GST_Byte5 : 40|8@1+ (1,0) [0|0] ""  CGW_CCU
 SG_ DPSU_GST_Byte6 : 48|8@1+ (1,0) [0|0] ""  CGW_CCU
 SG_ DPSU_GST_Byte7 : 56|8@1+ (1,0) [0|0] ""  CGW_CCU
 SG_ DPSU_GST_Byte1 : 8|8@1+ (1,0) [0|0] ""  CGW_CCU

BO_ 1420 SGU_GST: 8 SGU
 SG_ SGU_GST_Byte0 : 0|8@1+ (1,0) [0|0] ""  CGW_CCU
 SG_ SGU_GST_Byte2 : 16|8@1+ (1,0) [0|0] ""  CGW_CCU
 SG_ SGU_GST_Byte3 : 24|8@1+ (1,0) [0|0] ""  CGW_CCU
 SG_ SGU_GST_Byte4 : 32|8@1+ (1,0) [0|0] ""  CGW_CCU
 SG_ SGU_GST_Byte5 : 40|8@1+ (1,0) [0|0] ""  CGW_CCU
 SG_ SGU_GST_Byte6 : 48|8@1+ (1,0) [0|0] ""  CGW_CCU
 SG_ SGU_GST_Byte7 : 56|8@1+ (1,0) [0|0] ""  CGW_CCU
 SG_ SGU_GST_Byte1 : 8|8@1+ (1,0) [0|0] ""  CGW_CCU

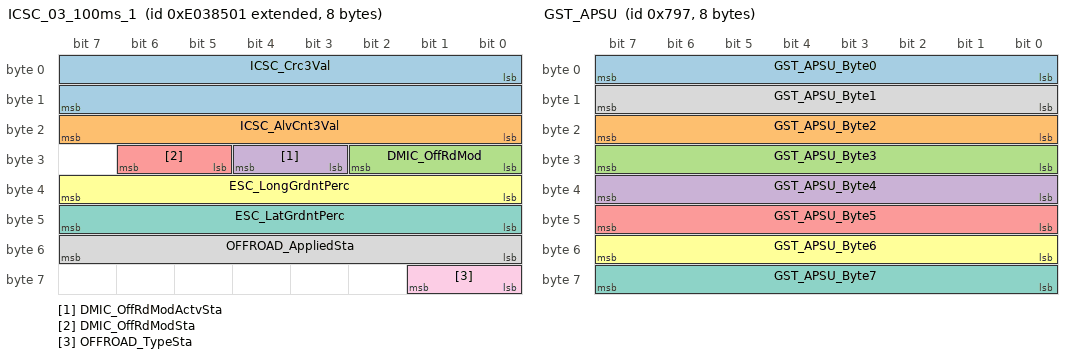
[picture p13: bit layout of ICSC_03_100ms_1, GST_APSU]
BO_ 2382595329 ICSC_03_100ms_1: 8 CGW_CCU
 SG_ ICSC_Crc3Val : 0|16@1+ (1,0) [0|0] ""  Vector__XXX
 SG_ ICSC_AlvCnt3Val : 16|8@1+ (1,0) [0|0] ""  Vector__XXX
 SG_ DMIC_OffRdMod : 24|3@1+ (1,0) [0|0] ""  Vector__XXX
 SG_ DMIC_OffRdModActvSta : 27|2@1+ (1,0) [0|0] ""  RCS
 SG_ DMIC_OffRdModSta : 29|2@1+ (1,0) [0|0] ""  Vector__XXX
 SG_ ESC_LongGrdntPerc : 32|8@1- (1,0) [0|0] "%"  EMCU
 SG_ ESC_LatGrdntPerc : 40|8@1- (1,0) [0|0] "%"  EMCU
 SG_ OFFROAD_AppliedSta : 48|8@1+ (1,0) [0|0] ""  Vector__XXX
 SG_ OFFROAD_TypeSta : 56|2@1+ (1,0) [0|0] ""  Vector__XXX

BO_ 2332213252 VCU_06_200ms_4: 8 CGW_CCU

BO_ 1943 GST_APSU: 8 CGW_CCU
 SG_ GST_APSU_Byte0 : 0|8@1+ (1,0) [0|0] ""  APSU
 SG_ GST_APSU_Byte2 : 16|8@1+ (1,0) [0|0] ""  APSU
 SG_ GST_APSU_Byte3 : 24|8@1+ (1,0) [0|0] ""  APSU
 SG_ GST_APSU_Byte4 : 32|8@1+ (1,0) [0|0] ""  APSU
 SG_ GST_APSU_Byte5 : 40|8@1+ (1,0) [0|0] ""  APSU
 SG_ GST_APSU_Byte6 : 48|8@1+ (1,0) [0|0] ""  APSU
 SG_ GST_APSU_Byte7 : 56|8@1+ (1,0) [0|0] ""  APSU
 SG_ GST_APSU_Byte1 : 8|8@1+ (1,0) [0|0] ""  APSU

BO_ 2328014852 DATC_17_200ms_4: 8 CGW_CCU

BO_TX_BU_ 1003 : RRPSU,RLPSU;
BO_TX_BU_ 1005 : RRPSU,RLPSU;
CM_ BO_ 479 "[PE] Periodic and On Event";
CM_ SG_ 479 ALBCU_LumbarUpDis "ALBCU_LumbarUppperDisplay";
CM_ SG_ 479 ALBCU_BolsterDefDis "ALBCU_BolsterDeflationDisplay";
CM_ SG_ 479 ALBCU_CushInfDis "ALBCU_CushionInflationDisplay";
CM_ SG_ 479 ALBCU_CushDefDis "ALBCU_CushionDeflationDisplay";
CM_ SG_ 479 ALBCU_ActiveDis "ALBCU_ActiveModeDisplay";
CM_ SG_ 479 ALBCU_DrvModUSMSta "ALBCU_DriveModeStatus";
CM_ SG_ 479 ALBCU_LumbarMidDis "ALBCU_LumbarMidDisplay";
CM_ SG_ 479 ALBCU_ActiveStrSta "ALBCU_ActiveStrengthStatus";
CM_ SG_ 479 ALBCU_ActiveTimeSta "ALBCU_ActiveTimeStatus";
CM_ SG_ 479 ALBCU_CellOpt "ALBCU_CellOption Status";
CM_ SG_ 479 ALBCU_BodySpprtSta "Seat Body Support Function USM R Value";
CM_ SG_ 479 ALBCU_BodySpprtDis "Seat body Support Function Display Request";
CM_ SG_ 479 ALBCU_SmartCtrl_Set_Rvalue "Smart Posture Adjust Function USM R Value";
CM_ SG_ 479 ALBCU_LumbarLowDis "ALBCU_LumbarLowerDisplay";
CM_ SG_ 479 ALBCU_LumbarDefDis "ALBCU_LumbarDeflationDisplay";
CM_ SG_ 479 ALBCU_BolsterInfDis "ALBCU_BolsterInflationDisplay";
CM_ BO_ 2235651329 "[P] Periodic";
CM_ SG_ 2235651329 ACU_APSB_Crc1Val "ACU_APSB_CyclicRedundancyCheck1Value";
CM_ SG_ 2235651329 ACU_APSB_AlvCnt1Val "ACU_APSB_AliveCounter1Value";
CM_ SG_ 2235651329 APSB_ConfTbl "APSB_ConfigurationTable";
CM_ SG_ 2235651329 APSB_CrashActvSta "APSB_CrashActiveStatus";
CM_ SG_ 2235651329 APSB_RRDrvImpt "APSB RoughRoadDrvingImpact";
CM_ SG_ 2235651329 APSB_FCAFrImpt "APSB FCAFrontImpact";
CM_ SG_ 2235651329 APSB_MinFrImpt "APSB MinorFrontImpact";
CM_ SG_ 2235651329 APSB_MinSidImpt "APSB MinorSideImpact";
CM_ SG_ 2235651329 APSB_MinRollDetn "APSB MinorRollDetection";
CM_ SG_ 2235651329 APSB_MinRearImpt "APSB MinorRearImpact";
CM_ BO_ 2235651330 "[P] Periodic";
CM_ BO_ 1518 "[TP] Transport Protocol";
CM_ BO_ 1007 "[EC] On Event and On Change";
CM_ SG_ 1007 ATS_LEDBgtnsUpDn "Interior Light Brightness Up/Down Request";
CM_ SG_ 1007 ATS_FrMoodOn_Req "Front mood lamp On/Off request";
CM_ SG_ 1007 ATS_DoorOn_Req "Front Door switch On/Off request";
CM_ SG_ 1007 ATS_RrMapLftOn_Req "Rear left map lamp On/Off request";
CM_ SG_ 1007 ATS_RrMapRtOn_Req "Rear right map lamp On/Off request";
CM_ SG_ 1007 ATS_RrRoomOn_Req "Rear room lamp On/Off request";
CM_ SG_ 1007 ATS_LEDClrUpDn "Interior Light Color Up/Down Request";
CM_ SG_ 1007 ATS_RrMoodOn_Req "Rear mood lamp On/Off request";
CM_ SG_ 1007 ATS_LEDClr_Set "Interior Lamp LED Color Request";
CM_ SG_ 1007 ATS_LEDBgtns_Set "Interior Lamp LED Brightness Request";
CM_ SG_ 1007 ATS_LEDClrUpDnBtn "Interior Light Color Up/Down Request";
CM_ SG_ 1007 ATS_LEDBgtnsUpDnBtn "Interior Light Brightness Up/Down Request";
CM_ SG_ 1007 ATS_FrMapLftOn_Req "Front left map lamp On/Off request";
CM_ SG_ 1007 ATS_FrMapRtOn_Req "Front right map lamp On/Off request";
CM_ SG_ 1007 ATS_FrRoomOn_Req "Front room lamp On/Off request";
CM_ BO_ 992 "[PE] Periodic and On Event";
CM_ SG_ 992 BCM_Crc2Val "BCM_CyclicRedundancyCheck2Value";
CM_ SG_ 992 BCM_AlvCnt2Val "BCM_AliveCounter2Value";
CM_ SG_ 992 BAlarm_BglrAlrmCurrentSta "BAlarm_BuglarAlarmCurrentStatus ##2G##BCM - BCMmsg17 - C_BAlarmState";
CM_ SG_ 992 BAlarm_BglrAlrmSta "BAlarm_BuglarAlarmStatus ##2G##BCM - BCMmsg17 - C_BAState";
CM_ SG_ 992 BAlarm_PncAlrmSta "BAlarm_PanicAlarmStatus ##2G##BCM - BCMmsg17 - C_PanicState";
CM_ SG_ 992 BAlarm_StrtInhbtRlySta "BAlarm_StartInhibitRelayStatus ##2G##BCM - BCMmsg19 - C_StartINHRly";
CM_ SG_ 992 BAlarm_BrglrHrnRlySta "BAlarm_BurglarHornRelayStatus ##2G##BCM - BCMmsg19 - C_BurglarHornRly";
CM_ SG_ 992 BCM_KeyInSta "BCM_KeyInStatus ##2G##BCM - BCMmsg17 - C_KeyInSW";
CM_ SG_ 992 BCM_AccInSta "BCM_AccInputStatus ##2G##BCM - BCMmsg17 - C_Acc";
CM_ SG_ 992 BCM_Ign1InSta "BCM_Ignition1InputStatus ##2G##BCM - BCMmsg17 - C_Ign1";
CM_ SG_ 992 BCM_Ign2InSta "BCM_Ignition1InputStatus ##2G##BCM - BCMmsg17 - C_Ign2";
CM_ SG_ 992 Warn_RhtSEA_BDC "Command for SEA RH Warning Text on cluster";
CM_ BO_ 994 "[PE] Periodic and On Event";
CM_ SG_ 994 BCM_Crc4Val "BCM_CyclicRedundancyCheck4Value";
CM_ SG_ 994 BCM_AlvCnt4Val "BCM_AliveCounter4Value";
CM_ SG_ 994 Warn_BzrWrngSta "Warn_BuzzerWarningStatus ##2G##BCM - BCMmsg18 - C_WngBuz";
CM_ SG_ 994 Warn_BCMWrngSta "Warn_BCMWarningStatus ##2G##BCM - BCMmsg19 - C_BCMWarning";
CM_ SG_ 994 ROA_RegionOpt "A Euro NCAP Option signal (BDC only)";
CM_ SG_ 994 Warn_RrStRmndOpt "Warn_RearSeatReminderOption ##2G##BCM - BCMmsg22 - C_RrSeatRemindOpt";
CM_ SG_ 994 Warn_RrStRmndAlrmOnReq "Warn_RearSeatReminderAlarmOnRequest ##2G##BCM - BCMmsg22 - C_RrSeatRemindAlarm";
CM_ SG_ 994 Warn_RrStRmndSysSta "Warn_RearSeatReminderSystemStatus ##2G##BCM - BCMmsg22 - C_RrSeatRemindState";
CM_ SG_ 994 Warn_RrStRmndAlrmInfo "Warn_RearSeatReminderAlarmInformaion ##2G##BCM - BCMmsg22 - C_RrSeatRemindInfo";
CM_ SG_ 994 Warn_RoaErr "Warn_RoaError##2G##BCM - BCMmsg22 - C_RoaError";
CM_ SG_ 994 WAL_FobSearching "IBU Walk Away Lock Fob Searching State for Radar ROA";
CM_ BO_ 997 "[PE] Periodic and On Event";
CM_ SG_ 997 BCM_Crc5Val "BCM_CyclicRedundancyCheck5Value";
CM_ SG_ 997 BCM_AlvCnt5Val "BCM_AliveCounter5Value";
CM_ SG_ 997 PDW_OptTyp "PDW_OptionType ##2G##BCM - BCMmsg18 - C_PASOption";
CM_ SG_ 997 PDW_SysChkSndSta "PDW_SystemCheckSoundStatus ##2G##BCM - BCMmsg18 - C_PASCheckSound";
CM_ SG_ 997 PDW_SwIndOnReq "PDW_SwitchIndicatorOnRequest ##2G##BCM - BCMmsg18 - C_PASSwInd";
CM_ SG_ 997 PDW_SysOnSta "PDW_SystemOnStatus ##2G##BCM - BCMmsg18 - C_PASSystemOn";
CM_ SG_ 997 PDW_FrCtWrngLvlDis "PDW_FrontCenterWarningLevelDisplay ##2G##BCM - BCMmsg18 - C_PASDisplayFCTR";
CM_ SG_ 997 PDW_FrCtWrngSndSta "PDW_FrontCenterWarningSoundStatus ##2G##BCM - BCMmsg23 - C_PasSpkrFCNTAlarm";
CM_ SG_ 997 PDW_FrLtWrngLvlDis "PDW_FrontLeftWarningLevelDisplay ##2G##BCM - BCMmsg18 - C_PASDisplayFLH";
CM_ SG_ 997 PDW_FrLtWrngSndSta "PDW_FrontLeftWarningSoundStatus ##2G##BCM - BCMmsg23 - C_PasSpkrFLHAlarm";
CM_ SG_ 997 PDW_FrRtWrngLvlDis "PDW_FrontRightWarningLevelDisplay ##2G##BCM - BCMmsg18 - C_PASDisplayFRH";
CM_ SG_ 997 PDW_FrRtWrngSndSta "PDW_FrontRightWarningSoundStatus ##2G##BCM - BCMmsg23 - C_PasSpkrFRHAlarm";
CM_ SG_ 997 PDW_FrSnsrWrngLvlSta "PDW_FrontSensorWarningLevelStatus ##2G##BCM - BCMmsg18 - C_PASFsound";
CM_ BO_ 1002 "[PE] Periodic and On Event";
CM_ SG_ 1002 BLTN_CAM_HU_UI_Mode "Display control of Built-in Cam UI mode. This Signal for Ethernet Type Built-in Cam.";
CM_ SG_ 1002 BLTN_CAM_SD_Format_Op_State "BLTN_CAM SD card format operation status.";
CM_ SG_ 1002 BLTN_CAM_PEV_Recorded "This Signal is sent just after the park event recorded.";
CM_ SG_ 1002 BLTN_CAM_PEV_Count "This Signal is count of park event record.";
CM_ SG_ 1002 BLTN_CAM_Ind_Req "This Signal is for HU Display Built-in Cam Indicator.";
CM_ SG_ 1002 BLTN_CAM_LVDS_Mode_State "This Signal is for LVDS output status";
CM_ SG_ 1002 BLTN_CAM_PrkOp_Termiate_Info "0x0:Default/0x01: Park operation terminated earlier than user set because of Bat. SoC/0x2 : Park operation terminated earlier than user set because of SD Card Problem /0x3 : Park operation terminated earlier than user set because of Built-in Cam internal Error /0x04~0x6:Reserved/0x07 : Park operation terminate on time which user se";
CM_ SG_ 1002 BLTN_CAM_Display "Display control of Built-in Cam UI mode. This Signal for CAN Type Built-in Cam.(with Standard 5th Wide AVNT)";
CM_ SG_ 1002 BLTN_CAM_WiFi_State "BLTN_CAM WiFi Stattus";
CM_ BO_ 2353206529 "[P] Periodic";
CM_ SG_ 2353206529 CLU_Crc20Val "CLU_CyclicRedundancyCheck20Value";
CM_ SG_ 2353206529 CLU_AlvCnt20Val "CLU_AliveCounter20Value";
CM_ SG_ 2353206529 CLU_SndType "CLU_SoundType";
CM_ BO_ 2353206530 "[P] Periodic";
CM_ BO_ 2328014852 "[P] Periodic";
CM_ BO_ 1963 "[TP] Transport Protocol";
CM_ BO_ 1422 "[TP] Transport Protocol";
CM_ BO_ 1943 "[TP] Transport Protocol";
CM_ BO_ 1955 "[TP] Transport Protocol";
CM_ BO_ 1414 "[TP] Transport Protocol";
CM_ BO_ 1426 "[TP] Transport Protocol";
CM_ BO_ 1415 "[TP] Transport Protocol";
CM_ SG_ 1415 GST_RCS_Byte0 "Diag Request for RCS";
CM_ SG_ 1415 GST_RCS_Byte2 "Diag Request for RCS";
CM_ SG_ 1415 GST_RCS_Byte3 "Diag Request for RCS";
CM_ SG_ 1415 GST_RCS_Byte4 "Diag Request for RCS";
CM_ SG_ 1415 GST_RCS_Byte5 "Diag Request for RCS";
CM_ SG_ 1415 GST_RCS_Byte6 "Diag Request for RCS";
CM_ SG_ 1415 GST_RCS_Byte7 "Diag Request for RCS";
CM_ SG_ 1415 GST_RCS_Byte1 "Diag Request for RCS";
CM_ BO_ 1956 "[TP] Transport Protocol";
CM_ BO_ 1412 "[TP] Transport Protocol";
CM_ BO_ 1959 "[TP] Transport Protocol";
CM_ BO_ 1015 "[P] Periodic";
CM_ SG_ 1015 HU_MM_Altitude "Mapmatching Altitude";
CM_ SG_ 1015 HU_MM_Heading "Map matching heading";
CM_ BO_ 1016 "[P] Periodic";
CM_ SG_ 1016 GNSS_MM_type "Map matching type info.";
CM_ BO_ 1019 "[EC] On Event and On Change";
CM_ SG_ 1019 HU_MoodTherapyDrSeat "Moodtherapy Driver Seat On/Off";
CM_ SG_ 1019 HU_VitalityFragrance "Vitality Fragrance On/Off";
CM_ SG_ 1019 HU_VitalityCurtain "Vitality Curtain On/Off";
CM_ SG_ 1019 HU_DelightMoodLamp "Delight MoodLamp On/Off";
CM_ SG_ 1019 HU_DelightFragrance "Delight Fragrance On/Off";
CM_ SG_ 1019 HU_DelightCurtain "Delight Curtain On/Off";
CM_ SG_ 1019 HU_MoodTherapyPsSeat "Moodtherapy Passenger Seat On/Off";
CM_ SG_ 1019 HU_CareMoodLamp "Care MoodLamp On/Off";
CM_ SG_ 1019 HU_CareFragrance "Care Fragrance On/Off";
CM_ SG_ 1019 HU_CareMassage "Care Massage On/Off";
CM_ SG_ 1019 HU_CareCurtain "Care Curtain On/Off";
CM_ SG_ 1019 HU_ComfortMoodLamp "Comfort MoodLamp On/Off";
CM_ SG_ 1019 HU_ComfortFragrance "Comfort Fragrance On/Off";
CM_ SG_ 1019 HU_ComfortMassage "Comfort Massage On/Off";
CM_ SG_ 1019 HU_ComfortCurtain "Comfort Curtain On/Off";
CM_ SG_ 1019 HU_MoodTherapyMode "Moodtherapy Mode Change Signal";
CM_ SG_ 1019 HU_MoodTherapyRlSeat "Moodtherapy RearLeft Seat On/Off";
CM_ SG_ 1019 HU_MoodTherapyRrSeat "Moodtherapy Rear Right Seat On/Off";
CM_ SG_ 1019 HU_VitalityMoodLamp "Vitality MoodLamp On/Off";
CM_ BO_ 2382595329 "[P] Periodic";
CM_ SG_ 2382595329 ICSC_Crc3Val "ICSC_CyclicRedundancyCheck3Value";
CM_ SG_ 2382595329 ICSC_AlvCnt3Val "ICSC_AliveCounter3Value";
CM_ SG_ 2382595329 DMIC_OffRdMod "DMIC_OffRoadMode";
CM_ SG_ 2382595329 DMIC_OffRdModActvSta "DMIC_OffRoadModeActivationStatus";
CM_ SG_ 2382595329 DMIC_OffRdModSta "DMIC_OffRoadModeStatus";
CM_ SG_ 2382595329 ESC_LongGrdntPerc "ESC_LongitudinalGradientPercent";
CM_ SG_ 2382595329 ESC_LatGrdntPerc "ESC_LateralGradientPercent";
CM_ SG_ 2382595329 OFFROAD_AppliedSta "OFFROAD_AppliedStatus";
CM_ SG_ 2382595329 OFFROAD_TypeSta "OFFROAD_TypeStatus";
CM_ BO_ 1434 "[TP] Transport Protocol";
CM_ BO_ 1004 "[PE] Periodic and On Event";
CM_ SG_ 1004 CF_RCS_SwTyp "RCS type";
CM_ SG_ 1004 CF_RCS_OffRoad "OffRoad mode";
CM_ SG_ 1004 CF_RCS_BtnSta "RCS Button Status";
CM_ SG_ 1004 CF_RCS_RotateEnd "signal to inform end of rotate";
CM_ SG_ 1004 CF_RCS_4wdLocking "4wd locking on/off signal";
CM_ SG_ 1004 CF_RCS_DrvMod "Drive mode select";
CM_ BO_ 1423 "[TP] Transport Protocol";
CM_ SG_ 1423 RCS_GST_Byte0 "Diag Response from RCS";
CM_ SG_ 1423 RCS_GST_Byte2 "Diag Response from RCS";
CM_ SG_ 1423 RCS_GST_Byte3 "Diag Response from RCS";
CM_ SG_ 1423 RCS_GST_Byte4 "Diag Response from RCS";
CM_ SG_ 1423 RCS_GST_Byte5 "Diag Response from RCS";
CM_ SG_ 1423 RCS_GST_Byte6 "Diag Response from RCS";
CM_ SG_ 1423 RCS_GST_Byte7 "Diag Response from RCS";
CM_ SG_ 1423 RCS_GST_Byte1 "Diag Response from RCS";
CM_ BO_ 1003 "[PE] Periodic and On Event";
CM_ SG_ 1003 PSM_BzrOnRLReq "PSM_BuzzerOnRLRequest";
CM_ SG_ 1003 RLPSM_RrLfSldStrtSta "PSM_RearRightSlidingStartStatus";
CM_ SG_ 1003 RLPSM_OptTyp "RLPSM_OptionType (Rear Left PSM)";
CM_ SG_ 1003 RLPSM_RLStEsyAcsUSMSta "RLPSM_USM_MovingValue";
CM_ SG_ 1003 RLPSM_FnshSta "RLPSM_FinishStatus";
CM_ SG_ 1003 RLPSM_AllSeatPosPlyBck_Sta "RLPSM_AllSeatPositionPlayBack_State";
CM_ SG_ 1003 RLPSM_SeatPos_Sta "RLPSM_SeatPosition_State";
CM_ SG_ 1003 RLPSM_SeatPosSldLmt_Sta "RLPSM_SeatPositionSlideLimitState";
CM_ SG_ 1003 RLPSM_Enable_Sta "RLPSM_Enable_State";
CM_ SG_ 1003 RLPSM_MvSta "RLPSM_MoveStatus";
CM_ SG_ 1003 RLPSM_Mem1_Sta "RLPSM_Memory1_State";
CM_ SG_ 1003 RLPSM_Mem2_Sta "RLPSM_Memory2_State";
CM_ SG_ 1003 RLPSM_Mem3_Sta "RLPSM_Memory3_State";
CM_ SG_ 1003 RLPSM_LimSetSta "RLPSM limit setting state";
CM_ SG_ 1003 PSM_RrLftSldPosVal "PSM_RearLeftSlidePositionValue";
CM_ SG_ 1003 PSM_SldStrtSta "PSM_SlidingStartStatus";
CM_ BO_ 1005 "[PE] Periodic and On Event";
CM_ SG_ 1005 RLPSU_FldDis "2nd Left side seat moving state  : Folding";
CM_ SG_ 1005 RLPSU_TiltDownDis "2nd Left side seat moving state  : Tilt down";
CM_ SG_ 1005 RLPSU_RclFwdDis "2nd Left side seat moving state  : Recline Forward";
CM_ SG_ 1005 RLPSU_RclBwdDis "2nd Left side seat moving state  : Recline Backward";
CM_ SG_ 1005 RLPSU_RlxModeDis "2nd Left side seat moving state  : Relax mode";
CM_ SG_ 1005 RLPSU_Folding_SW "Interlocking signal between DPSM and RLPSU";
CM_ SG_ 1005 RLPSU_UnFldDis "2nd Left side seat moving state  : UnFolding";
CM_ SG_ 1005 RLPSU_Unfolding_SW "Interlocking signal between DPSM and RLPSU";
CM_ SG_ 1005 RLPSU_WalkIn_SW "Interlocking signal between DPSM and RLPSU";
CM_ SG_ 1005 RLPSU_UnwalkIn_SW "Interlocking signal between DPSM and RLPSU";
CM_ SG_ 1005 RLPSU_Folding_Postion "RLPSU Position Information";
CM_ SG_ 1005 RLPSU_Folding_State_PopUp "Rear LH seat Folding State information";
CM_ SG_ 1005 RLPSU_Relax_State_Popup "Rear LH seat Relax State information";
CM_ SG_ 1005 RLPSU_SlideFwdDis "2nd Left side seat moving state  : Slide Forward";
CM_ SG_ 1005 RLPSU_SlideBwdDis "2nd Left side seat moving state  : Slide Backward";
CM_ SG_ 1005 RLPSU_WalkInDis "2nd Left side seat moving state : Walk In";
CM_ SG_ 1005 RLPSU_WalkInState "2nd Left side seat Walk-in Ready state";
CM_ SG_ 1005 RLPSU_UnWalkInDis "2nd Left side seat moving state : Un Walk In";
CM_ SG_ 1005 RLPSU_TiltUpDis "2nd Left side seat moving state  : Tilt up";
CM_ BO_ 1006 "[PE] Periodic and On Event";
CM_ SG_ 1006 RRPSU_FldDis "2nd Right side seat moving state  : Folding";
CM_ SG_ 1006 RRPSU_TiltDnDis "2nd Right side seat moving state  : Tilt down";
CM_ SG_ 1006 RRPSU_RecFwdDis "2nd Right side seat moving state  : Recline Forward";
CM_ SG_ 1006 RRPSU_RecBwdDis "2nd Right side seat moving state  : Recline Backward";
CM_ SG_ 1006 RRPSU_RlxModeDis "2nd Right side seat moving state  : Relax mode";
CM_ SG_ 1006 RRPSU_Folding_SW "Interlocking signal between DPSM and RRPSU";
CM_ SG_ 1006 RRPSU_UnFldDis "2nd Right side seat moving state  : UnFolding";
CM_ SG_ 1006 RRPSU_Unfolding_SW "Interlocking signal between DPSM and RRPSU";
CM_ SG_ 1006 RRPSU_WalkIn_SW "Interlocking signal between DPSM and RRPSU";
CM_ SG_ 1006 RRPSU_UnwalkIn_SW "Interlocking signal between DPSM and RRPSU";
CM_ SG_ 1006 RRPSU_Folding_Postion "RRPSU Position Information";
CM_ SG_ 1006 RRPSU_Folding_State_Popup "Rear RH seat Folding State information";
CM_ SG_ 1006 RRPSU_Relax_State_Popup "Rear RH seat Relax State information";
CM_ SG_ 1006 RRPSU_SlideFwdDis "2nd Right side seat moving state  : Slide Forward";
CM_ SG_ 1006 RRPSU_SlideBwdDis "2nd Right side seat moving state  : Slide Backward";
CM_ SG_ 1006 RRPSU_WalkinDis "2nd Right side seat moving state : Walk In";
CM_ SG_ 1006 RRPSU_WalkInState "2nd Right side seat Walk-in Ready state";
CM_ SG_ 1006 RRPSU_UnwalkinDis "2nd Right side seat moving state : Un Walk In";
CM_ SG_ 1006 RRPSU_TiltUpDis "2nd Right side seat moving state  : Tilt up";
CM_ BO_ 2223056129 "[P] Periodic";
CM_ SG_ 2223056129 SAS_Crc1Val "SAS_CyclicRedundancyCheck1Value";
CM_ SG_ 2223056129 SAS_AlvCnt1Val "SAS_AliveCounter1Value";
CM_ SG_ 2223056129 SAS_AnglVal "SAS_AngleValue";
CM_ SG_ 2223056129 SAS_SpdVal "SAS_SpeedValue";
CM_ SG_ 2223056129 SAS_IntSta "SAS_InternalStatus";
CM_ BO_ 2223056130 "[P] Periodic";
CM_ BO_ 1964 "[TP] Transport Protocol";
CM_ BO_ 1420 "[TP] Transport Protocol";
CM_ BO_ 463 "[P] Periodic";
CM_ SG_ 463 SWRC_Crc3Val "SWRC_CyclicRedundancyCheck3Value";
CM_ SG_ 463 SWRC_AlvCnt3Val "SWRC_AliveCounter3Value";
CM_ SG_ 463 SWRC_CrsSwSta "SWRC_CruiseSwitchStatus";
CM_ SG_ 463 SWRC_CrsMainSwSta "SWRC_CruiseMainSwitchStatus";
CM_ SG_ 463 SWRC_SldMainSwSta "SWRC_SpeedLimiterMainSwitchStatus";
CM_ SG_ 463 SWRC_LFASwSta "SWRC_LFASwitchStatus";
CM_ SG_ 463 SWRC_PaddleUpSwSta "SWRC_PaddleUpSwitchStatus";
CM_ SG_ 463 SWRC_PaddleDnSwSta "SWRC_PaddleDownSwitchStatus";
CM_ SG_ 463 SWRC_Info "SWRC_Information_Type";
CM_ SG_ 463 SWRC_HdpSwSta "SWRC_HDPSwitchStatus";
CM_ BO_ 1967 "[TP] Transport Protocol";
CM_ BO_ 2332213252 "[P] Periodic";
BA_DEF_ BO_ "DiagState" ENUM "No","Yes" ;
BA_DEF_ BO_ "DiagResponse" ENUM "No","Yes" ;
BA_DEF_ BO_ "DiagRequest" ENUM "No","Yes" ;
BA_DEF_ BO_ "TpMessage" ENUM "No","Yes" ;
BA_DEF_ BO_ "UsrMsgIDSforwardDeviation" INT 0 100 ;
BA_DEF_ BO_ "UsrMsgIDSbackwardDeviation" INT 50 1000 ;
BA_DEF_ BO_ "GenMsgCycleTime" INT 0 2000 ;
BA_DEF_ BO_ "GenMsgStartDelayTime" INT 0 2000 ;
BA_DEF_ BO_ "GenMsgSendType" ENUM "Cyclic","NoMsgSendType" ;
BA_DEF_ BO_ "GenMsgCycleTimeFast" INT 0 500 ;
BA_DEF_ BO_ "GenMsgDelayTime" INT 0 20 ;
BA_DEF_ BO_ "GenMsgILSupport" ENUM "No","Yes" ;
BA_DEF_ BO_ "GenMsgNrOfRepetition" INT 0 3 ;
BA_DEF_ BO_ "NmMessage" ENUM "No","Yes" ;
BA_DEF_ BO_ "NWM-Botschaft" ENUM "No","Yes" ;
BA_DEF_ BO_ "TpTxIndex" INT 0 255 ;
BA_DEF_ BO_ "VFrameFormat" ENUM "StandardCAN","ExtendedCAN","reserved","reserved","reserved","reserved","reserved","reserved","reserved","reserved","reserved","reserved","reserved","reserved","StandardCAN_FD","ExtendedCAN_FD" ;
BA_DEF_ SG_ "UserSigValidity" ENUM "B+","ACC","IG","IG1","IG2","IG3","IG1 or IG2","IG1 or IG3","Undef" ;
BA_DEF_ SG_ "TimeoutValue" STRING ;
BA_DEF_ SG_ "UsrSigPurpose" ENUM "Undef","FN","DIAG","DIAG(Req)","DIAG(Res)","DIAG(Phy)","DEV","CCP(Req)","CCP(Res)","NM","TP" ;
BA_DEF_ SG_ "GenSigStartValue" INT 0 1215752192 ;
BA_DEF_ SG_ "NetworkRequest" ENUM "Yes","No" ;
BA_DEF_ SG_ "NetworkRequestHoldingTime" INT 0 65535 ;
BA_DEF_ SG_ "Description" STRING ;
BA_DEF_ SG_ "Version" STRING ;
BA_DEF_ SG_ "GenSigEnvVarType" ENUM "Int","Float","Undef" ;
BA_DEF_ SG_ "GenSigSendType" ENUM "Cyclic","OnWrite","OnWriteWithRepetition","OnChange","OnChangeWithRepetition","IfActive","IfActiveWithRepetition","NoSigSendType","OnChangeAndIfActive","OnChangeAndIfActiveWithRepetition" ;
BA_DEF_ SG_ "GwSigLatencyTime" INT 0 65536 ;
BA_DEF_ SG_ "GwSigMissingSourceType" ENUM "Undef","OldValue","DefaultValue","InitialValue" ;
BA_DEF_ SG_ "NWM-WakeupAllowed" ENUM "<n.a.>" ;
BA_DEF_ SG_ "RoutingFactor" INT 1 1215752192 ;
BA_DEF_REL_ BU_SG_REL_ "GenSigTimeoutTime" INT 0 7000 ;
BA_DEF_DEF_ "DiagState" "No" ;
BA_DEF_DEF_ "DiagResponse" "No" ;
BA_DEF_DEF_ "DiagRequest" "No" ;
BA_DEF_DEF_ "TpMessage" "No" ;
BA_DEF_DEF_ "UsrMsgIDSforwardDeviation" 10 ;
BA_DEF_DEF_ "UsrMsgIDSbackwardDeviation" 100 ;
BA_DEF_DEF_ "GenMsgCycleTime" 200 ;
BA_DEF_DEF_ "GenMsgStartDelayTime" 0 ;
BA_DEF_DEF_ "GenMsgSendType" "NoMsgSendType" ;
BA_DEF_DEF_ "GenMsgCycleTimeFast" 40 ;
BA_DEF_DEF_ "GenMsgDelayTime" 20 ;
BA_DEF_DEF_ "GenMsgILSupport" "Yes" ;
BA_DEF_DEF_ "GenMsgNrOfRepetition" 3 ;
BA_DEF_DEF_ "NmMessage" "No" ;
BA_DEF_DEF_ "NWM-Botschaft" "No" ;
BA_DEF_DEF_ "TpTxIndex" 0 ;
BA_DEF_DEF_ "VFrameFormat" "StandardCAN" ;
BA_DEF_DEF_ "UserSigValidity" "IG" ;
BA_DEF_DEF_ "TimeoutValue" "" ;
BA_DEF_DEF_ "UsrSigPurpose" "FN" ;
BA_DEF_DEF_ "GenSigStartValue" 0 ;
BA_DEF_DEF_ "NetworkRequest" "No" ;
BA_DEF_DEF_ "NetworkRequestHoldingTime" 0 ;
BA_DEF_DEF_ "Description" "" ;
BA_DEF_DEF_ "Version" "" ;
BA_DEF_DEF_ "GenSigEnvVarType" "Undef" ;
BA_DEF_DEF_ "GenSigSendType" "NoSigSendType" ;
BA_DEF_DEF_ "GwSigLatencyTime" 40 ;
BA_DEF_DEF_ "GwSigMissingSourceType" "Undef" ;
BA_DEF_DEF_ "NWM-WakeupAllowed" "<n.a.>" ;
BA_DEF_DEF_ "RoutingFactor" 1 ;
BA_DEF_DEF_REL_ "GenSigTimeoutTime" 500 ;
BA_ "GenMsgSendType" BO_ 479 0;
BA_ "Description" SG_ 479 ALBCU_LumbarUpDis "This signal is used to display the seat movement to AVN";
BA_ "GenSigSendType" SG_ 479 ALBCU_LumbarUpDis 4;
BA_ "UserSigValidity" SG_ 479 ALBCU_LumbarUpDis 1;
BA_ "NetworkRequest" SG_ 479 ALBCU_LumbarUpDis 0;
BA_ "NetworkRequestHoldingTime" SG_ 479 ALBCU_LumbarUpDis 5000;
BA_ "RoutingFactor" SG_ 479 ALBCU_LumbarUpDis 0;
BA_ "Version" SG_ 479 ALBCU_LumbarUpDis "20.10.02";
BA_ "Description" SG_ 479 ALBCU_BolsterDefDis "This signal is used to display the seat movement to AVN";
BA_ "GenSigSendType" SG_ 479 ALBCU_BolsterDefDis 4;
BA_ "UserSigValidity" SG_ 479 ALBCU_BolsterDefDis 1;
BA_ "NetworkRequest" SG_ 479 ALBCU_BolsterDefDis 0;
BA_ "NetworkRequestHoldingTime" SG_ 479 ALBCU_BolsterDefDis 5000;
BA_ "RoutingFactor" SG_ 479 ALBCU_BolsterDefDis 0;
BA_ "Version" SG_ 479 ALBCU_BolsterDefDis "20.10.02";
BA_ "Description" SG_ 479 ALBCU_CushInfDis "This signal is used to display the seat movement to AVN";
BA_ "GenSigSendType" SG_ 479 ALBCU_CushInfDis 4;
BA_ "UserSigValidity" SG_ 479 ALBCU_CushInfDis 1;
BA_ "NetworkRequest" SG_ 479 ALBCU_CushInfDis 0;
BA_ "NetworkRequestHoldingTime" SG_ 479 ALBCU_CushInfDis 5000;
BA_ "RoutingFactor" SG_ 479 ALBCU_CushInfDis 0;
BA_ "Version" SG_ 479 ALBCU_CushInfDis "20.10.02";
BA_ "Description" SG_ 479 ALBCU_CushDefDis "This signal is used to display the seat movement to AVN";
BA_ "GenSigSendType" SG_ 479 ALBCU_CushDefDis 4;
BA_ "UserSigValidity" SG_ 479 ALBCU_CushDefDis 1;
BA_ "NetworkRequest" SG_ 479 ALBCU_CushDefDis 0;
BA_ "NetworkRequestHoldingTime" SG_ 479 ALBCU_CushDefDis 5000;
BA_ "RoutingFactor" SG_ 479 ALBCU_CushDefDis 0;
BA_ "Version" SG_ 479 ALBCU_CushDefDis "20.10.02";
BA_ "Description" SG_ 479 ALBCU_ActiveDis "Display Air support mode to AVN";
BA_ "GenSigSendType" SG_ 479 ALBCU_ActiveDis 4;
BA_ "UserSigValidity" SG_ 479 ALBCU_ActiveDis 1;
BA_REL_ "GenSigTimeoutTime" BU_SG_REL_ CGW_CCU SG_ 479 ALBCU_ActiveDis 1500;
BA_ "NetworkRequest" SG_ 479 ALBCU_ActiveDis 0;
BA_ "NetworkRequestHoldingTime" SG_ 479 ALBCU_ActiveDis 5000;
BA_ "RoutingFactor" SG_ 479 ALBCU_ActiveDis 0;
BA_ "Version" SG_ 479 ALBCU_ActiveDis "20.10.02";
BA_ "Description" SG_ 479 ALBCU_DrvModUSMSta "Drivemode interlock signal feedback to AVN";
BA_ "GenSigSendType" SG_ 479 ALBCU_DrvModUSMSta 4;
BA_ "UserSigValidity" SG_ 479 ALBCU_DrvModUSMSta 1;
BA_REL_ "GenSigTimeoutTime" BU_SG_REL_ CGW_CCU SG_ 479 ALBCU_DrvModUSMSta 1500;
BA_ "NetworkRequest" SG_ 479 ALBCU_DrvModUSMSta 0;
BA_ "NetworkRequestHoldingTime" SG_ 479 ALBCU_DrvModUSMSta 5000;
BA_ "RoutingFactor" SG_ 479 ALBCU_DrvModUSMSta 0;
BA_ "Version" SG_ 479 ALBCU_DrvModUSMSta "20.10.02";
BA_ "Description" SG_ 479 ALBCU_LumbarMidDis "This signal is used to display the seat movement to AVN";
BA_ "GenSigSendType" SG_ 479 ALBCU_LumbarMidDis 4;
BA_ "UserSigValidity" SG_ 479 ALBCU_LumbarMidDis 1;
BA_ "NetworkRequest" SG_ 479 ALBCU_LumbarMidDis 0;
BA_ "NetworkRequestHoldingTime" SG_ 479 ALBCU_LumbarMidDis 5000;
BA_ "RoutingFactor" SG_ 479 ALBCU_LumbarMidDis 0;
BA_ "Version" SG_ 479 ALBCU_LumbarMidDis "20.10.02";
BA_ "Description" SG_ 479 ALBCU_ActiveStrSta "Air support mode strength Signal feedback to AVN";
BA_ "GenSigSendType" SG_ 479 ALBCU_ActiveStrSta 4;
BA_ "UserSigValidity" SG_ 479 ALBCU_ActiveStrSta 1;
BA_REL_ "GenSigTimeoutTime" BU_SG_REL_ CGW_CCU SG_ 479 ALBCU_ActiveStrSta 1500;
BA_ "NetworkRequest" SG_ 479 ALBCU_ActiveStrSta 0;
BA_ "NetworkRequestHoldingTime" SG_ 479 ALBCU_ActiveStrSta 5000;
BA_ "RoutingFactor" SG_ 479 ALBCU_ActiveStrSta 0;
BA_ "Version" SG_ 479 ALBCU_ActiveStrSta "20.10.02";
BA_ "Description" SG_ 479 ALBCU_ActiveTimeSta "Air support refresh time Signal feedback to AVN";
BA_ "GenSigSendType" SG_ 479 ALBCU_ActiveTimeSta 4;
BA_ "UserSigValidity" SG_ 479 ALBCU_ActiveTimeSta 1;
BA_REL_ "GenSigTimeoutTime" BU_SG_REL_ CGW_CCU SG_ 479 ALBCU_ActiveTimeSta 1500;
BA_ "NetworkRequest" SG_ 479 ALBCU_ActiveTimeSta 0;
BA_ "NetworkRequestHoldingTime" SG_ 479 ALBCU_ActiveTimeSta 5000;
BA_ "RoutingFactor" SG_ 479 ALBCU_ActiveTimeSta 0;
BA_ "Version" SG_ 479 ALBCU_ActiveTimeSta "20.10.02";
BA_ "Description" SG_ 479 ALBCU_CellOpt "Seat air pressure system spec data signal 

(3Cell:Lumber support / 5Cell:Lumber bolster / 7Cell:Lumber bolster coushion)";
BA_ "GenSigSendType" SG_ 479 ALBCU_CellOpt 4;
BA_ "UserSigValidity" SG_ 479 ALBCU_CellOpt 0;
BA_REL_ "GenSigTimeoutTime" BU_SG_REL_ CGW_CCU SG_ 479 ALBCU_CellOpt 1500;
BA_ "NetworkRequest" SG_ 479 ALBCU_CellOpt 0;
BA_ "NetworkRequestHoldingTime" SG_ 479 ALBCU_CellOpt 5000;
BA_ "RoutingFactor" SG_ 479 ALBCU_CellOpt 0;
BA_ "Version" SG_ 479 ALBCU_CellOpt "20.10.02";
BA_ "Description" SG_ 479 ALBCU_BodySpprtSta "Seat Body Support Function USM R Value";
BA_ "GenSigSendType" SG_ 479 ALBCU_BodySpprtSta 4;
BA_ "UserSigValidity" SG_ 479 ALBCU_BodySpprtSta 1;
BA_REL_ "GenSigTimeoutTime" BU_SG_REL_ CGW_CCU SG_ 479 ALBCU_BodySpprtSta 1500;
BA_ "RoutingFactor" SG_ 479 ALBCU_BodySpprtSta 0;
BA_ "Version" SG_ 479 ALBCU_BodySpprtSta "20.10.02";
BA_ "Description" SG_ 479 ALBCU_BodySpprtDis "Seat Body Support Function Display Request";
BA_ "GenSigSendType" SG_ 479 ALBCU_BodySpprtDis 4;
BA_ "UserSigValidity" SG_ 479 ALBCU_BodySpprtDis 1;
BA_ "RoutingFactor" SG_ 479 ALBCU_BodySpprtDis 0;
BA_ "Version" SG_ 479 ALBCU_BodySpprtDis "20.10.02";
BA_ "GenSigSendType" SG_ 479 ALBCU_SmartCtrl_Set_Rvalue 4;
BA_ "UserSigValidity" SG_ 479 ALBCU_SmartCtrl_Set_Rvalue 1;
BA_ "RoutingFactor" SG_ 479 ALBCU_SmartCtrl_Set_Rvalue 0;
BA_ "Version" SG_ 479 ALBCU_SmartCtrl_Set_Rvalue "21.12.05";
BA_ "Description" SG_ 479 ALBCU_LumbarLowDis "This signal is used to display the seat movement to AVN";
BA_ "GenSigSendType" SG_ 479 ALBCU_LumbarLowDis 4;
BA_ "UserSigValidity" SG_ 479 ALBCU_LumbarLowDis 1;
BA_ "NetworkRequest" SG_ 479 ALBCU_LumbarLowDis 0;
BA_ "NetworkRequestHoldingTime" SG_ 479 ALBCU_LumbarLowDis 5000;
BA_ "RoutingFactor" SG_ 479 ALBCU_LumbarLowDis 0;
BA_ "Version" SG_ 479 ALBCU_LumbarLowDis "20.10.02";
BA_ "Description" SG_ 479 ALBCU_LumbarDefDis "This signal is used to display the seat movement to AVN";
BA_ "GenSigSendType" SG_ 479 ALBCU_LumbarDefDis 4;
BA_ "UserSigValidity" SG_ 479 ALBCU_LumbarDefDis 1;
BA_ "NetworkRequest" SG_ 479 ALBCU_LumbarDefDis 0;
BA_ "NetworkRequestHoldingTime" SG_ 479 ALBCU_LumbarDefDis 5000;
BA_ "RoutingFactor" SG_ 479 ALBCU_LumbarDefDis 0;
BA_ "Version" SG_ 479 ALBCU_LumbarDefDis "20.10.02";
BA_ "Description" SG_ 479 ALBCU_BolsterInfDis "This signal is used to display the seat movement to AVN";
BA_ "GenSigSendType" SG_ 479 ALBCU_BolsterInfDis 4;
BA_ "UserSigValidity" SG_ 479 ALBCU_BolsterInfDis 1;
BA_ "NetworkRequest" SG_ 479 ALBCU_BolsterInfDis 0;
BA_ "NetworkRequestHoldingTime" SG_ 479 ALBCU_BolsterInfDis 5000;
BA_ "RoutingFactor" SG_ 479 ALBCU_BolsterInfDis 0;
BA_ "Version" SG_ 479 ALBCU_BolsterInfDis "20.10.02";
BA_ "GenMsgSendType" BO_ 2235651329 0;
BA_ "GenMsgCycleTime" BO_ 2235651329 10;
BA_ "GenMsgCycleTimeFast" BO_ 2235651329 0;
BA_ "GenMsgNrOfRepetition" BO_ 2235651329 0;
BA_ "GenMsgDelayTime" BO_ 2235651329 0;
BA_ "VFrameFormat" BO_ 2235651329 1;
BA_ "Description" SG_ 2235651329 ACU_APSB_Crc1Val "The data area for CRC calculation is based on the data length (DLC) of the message DB.

The CRC shall be calculated over the entire data block (excluding the CRC bytes) including the user data, alive counter and Data ID

 

- CRC Polynomial (0x1021) , Initial Value : 0xFFFF, XOR value : 0x0000, Data ID : Message ID + 0xF800 

- The initial value is for CRC calculation and the message should be sent with the calculated result value. 

- The mathematical expression to 16 bit CRC polynomial is given here. G(x) = x16 + x12 + x5 + 1";
BA_ "GenSigStartValue" SG_ 2235651329 ACU_APSB_Crc1Val 65535;
BA_ "UserSigValidity" SG_ 2235651329 ACU_APSB_Crc1Val 3;
BA_ "Version" SG_ 2235651329 ACU_APSB_Crc1Val "18.11.08";
BA_ "Description" SG_ 2235651329 ACU_APSB_AlvCnt1Val "For the first transmission request for a data element the counter shall be initialized with 0 and shall be incremented by 1 for every subsequent send request. 

When the counter reaches the maximum value(0xFF), then it shall restart with 0 for the next send request";
BA_ "UserSigValidity" SG_ 2235651329 ACU_APSB_AlvCnt1Val 3;
BA_ "Version" SG_ 2235651329 ACU_APSB_AlvCnt1Val "18.11.08";
BA_ "Description" SG_ 2235651329 APSB_ConfTbl "This signal indicates supported signals that are correspond to detection type.

000000B : Not supported, 

xxxxx1B : Rough Road Impact 

xxxx1xB : FCA Impact

xxx1xxB : Minor Front Impact

xx1xxxB : Minor Side Impact

x1xxxxB : Minor Roll Detection

1xxxxxB : Minor Rear Impact";
BA_ "UserSigValidity" SG_ 2235651329 APSB_ConfTbl 3;
BA_ "Version" SG_ 2235651329 APSB_ConfTbl "18.02.03";
BA_ "Description" SG_ 2235651329 APSB_CrashActvSta "This signal indicates status of APSB activation by ACU.";
BA_ "UserSigValidity" SG_ 2235651329 APSB_CrashActvSta 3;
BA_ "Version" SG_ 2235651329 APSB_CrashActvSta "18.02.03";
BA_ "Description" SG_ 2235651329 APSB_RRDrvImpt "This signal indicates commends of APSB activation in case of rough road impact.";
BA_ "UserSigValidity" SG_ 2235651329 APSB_RRDrvImpt 3;
BA_ "Version" SG_ 2235651329 APSB_RRDrvImpt "18.02.03";
BA_ "Description" SG_ 2235651329 APSB_FCAFrImpt "This signal indicates commends of APSB activation in case of FCA impact.";
BA_ "UserSigValidity" SG_ 2235651329 APSB_FCAFrImpt 3;
BA_ "Version" SG_ 2235651329 APSB_FCAFrImpt "18.02.03";
BA_ "Description" SG_ 2235651329 APSB_MinFrImpt "This signal indicates commends of APSB activation in case of minor frontal  impact.";
BA_ "UserSigValidity" SG_ 2235651329 APSB_MinFrImpt 3;
BA_ "Version" SG_ 2235651329 APSB_MinFrImpt "18.02.03";
BA_ "Description" SG_ 2235651329 APSB_MinSidImpt "This signal indicates commends of APSB activation in case of minor side  impact.";
BA_ "UserSigValidity" SG_ 2235651329 APSB_MinSidImpt 3;
BA_ "Version" SG_ 2235651329 APSB_MinSidImpt "18.02.03";
BA_ "Description" SG_ 2235651329 APSB_MinRollDetn "This signal indicates commends of APSB activation in case of minor rollover detection.";
BA_ "UserSigValidity" SG_ 2235651329 APSB_MinRollDetn 3;
BA_ "Version" SG_ 2235651329 APSB_MinRollDetn "18.02.03";
BA_ "Description" SG_ 2235651329 APSB_MinRearImpt "This signal indicates commends of APSB activation in case of minor rear impact.";
BA_ "UserSigValidity" SG_ 2235651329 APSB_MinRearImpt 3;
BA_ "Version" SG_ 2235651329 APSB_MinRearImpt "18.02.03";
BA_ "GenMsgSendType" BO_ 2235651330 0;
BA_ "GenMsgCycleTime" BO_ 2235651330 10;
BA_ "GenMsgCycleTimeFast" BO_ 2235651330 0;
BA_ "GenMsgNrOfRepetition" BO_ 2235651330 0;
BA_ "GenMsgDelayTime" BO_ 2235651330 0;
BA_ "VFrameFormat" BO_ 2235651330 1;
BA_ "GenMsgCycleTime" BO_ 1518 0;
BA_ "GenMsgCycleTimeFast" BO_ 1518 0;
BA_ "GenMsgNrOfRepetition" BO_ 1518 0;
BA_ "DiagResponse" BO_ 1518 1;
BA_ "GenMsgILSupport" BO_ 1518 0;
BA_ "TpMessage" BO_ 1518 1;
BA_ "TpTxIndex" BO_ 1518 108;
BA_ "Description" SG_ 1518 APSS_GST_Byte0 "TP Index : 108";
BA_ "UsrSigPurpose" SG_ 1518 APSS_GST_Byte0 4;
BA_ "UserSigValidity" SG_ 1518 APSS_GST_Byte0 0;
BA_REL_ "GenSigTimeoutTime" BU_SG_REL_ CGW_CCU SG_ 1518 APSS_GST_Byte0 0;
BA_ "NetworkRequest" SG_ 1518 APSS_GST_Byte0 0;
BA_ "NetworkRequestHoldingTime" SG_ 1518 APSS_GST_Byte0 5000;
BA_ "Version" SG_ 1518 APSS_GST_Byte0 "21.02.04";
BA_ "Description" SG_ 1518 APSS_GST_Byte2 "TP Index : 108";
BA_ "UsrSigPurpose" SG_ 1518 APSS_GST_Byte2 4;
BA_ "UserSigValidity" SG_ 1518 APSS_GST_Byte2 0;
BA_REL_ "GenSigTimeoutTime" BU_SG_REL_ CGW_CCU SG_ 1518 APSS_GST_Byte2 0;
BA_ "NetworkRequest" SG_ 1518 APSS_GST_Byte2 0;
BA_ "NetworkRequestHoldingTime" SG_ 1518 APSS_GST_Byte2 5000;
BA_ "Version" SG_ 1518 APSS_GST_Byte2 "21.02.04";
BA_ "Description" SG_ 1518 APSS_GST_Byte3 "TP Index : 108";
BA_ "UsrSigPurpose" SG_ 1518 APSS_GST_Byte3 4;
BA_ "UserSigValidity" SG_ 1518 APSS_GST_Byte3 0;
BA_REL_ "GenSigTimeoutTime" BU_SG_REL_ CGW_CCU SG_ 1518 APSS_GST_Byte3 0;
BA_ "NetworkRequest" SG_ 1518 APSS_GST_Byte3 0;
BA_ "NetworkRequestHoldingTime" SG_ 1518 APSS_GST_Byte3 5000;
BA_ "Version" SG_ 1518 APSS_GST_Byte3 "21.02.04";
BA_ "Description" SG_ 1518 APSS_GST_Byte4 "TP Index : 108";
BA_ "UsrSigPurpose" SG_ 1518 APSS_GST_Byte4 4;
BA_ "UserSigValidity" SG_ 1518 APSS_GST_Byte4 0;
BA_REL_ "GenSigTimeoutTime" BU_SG_REL_ CGW_CCU SG_ 1518 APSS_GST_Byte4 0;
BA_ "NetworkRequest" SG_ 1518 APSS_GST_Byte4 0;
BA_ "NetworkRequestHoldingTime" SG_ 1518 APSS_GST_Byte4 5000;
BA_ "Version" SG_ 1518 APSS_GST_Byte4 "21.02.04";
BA_ "Description" SG_ 1518 APSS_GST_Byte5 "TP Index : 108";
BA_ "UsrSigPurpose" SG_ 1518 APSS_GST_Byte5 4;
BA_ "UserSigValidity" SG_ 1518 APSS_GST_Byte5 0;
BA_REL_ "GenSigTimeoutTime" BU_SG_REL_ CGW_CCU SG_ 1518 APSS_GST_Byte5 0;
BA_ "NetworkRequest" SG_ 1518 APSS_GST_Byte5 0;
BA_ "NetworkRequestHoldingTime" SG_ 1518 APSS_GST_Byte5 5000;
BA_ "Version" SG_ 1518 APSS_GST_Byte5 "21.02.04";
BA_ "Description" SG_ 1518 APSS_GST_Byte6 "TP Index : 108";
BA_ "UsrSigPurpose" SG_ 1518 APSS_GST_Byte6 4;
BA_ "UserSigValidity" SG_ 1518 APSS_GST_Byte6 0;
BA_REL_ "GenSigTimeoutTime" BU_SG_REL_ CGW_CCU SG_ 1518 APSS_GST_Byte6 0;
BA_ "NetworkRequest" SG_ 1518 APSS_GST_Byte6 0;
BA_ "NetworkRequestHoldingTime" SG_ 1518 APSS_GST_Byte6 5000;
BA_ "Version" SG_ 1518 APSS_GST_Byte6 "21.02.04";
BA_ "Description" SG_ 1518 APSS_GST_Byte7 "TP Index : 108";
BA_ "UsrSigPurpose" SG_ 1518 APSS_GST_Byte7 4;
BA_ "UserSigValidity" SG_ 1518 APSS_GST_Byte7 0;
BA_REL_ "GenSigTimeoutTime" BU_SG_REL_ CGW_CCU SG_ 1518 APSS_GST_Byte7 0;
BA_ "NetworkRequest" SG_ 1518 APSS_GST_Byte7 0;
BA_ "NetworkRequestHoldingTime" SG_ 1518 APSS_GST_Byte7 5000;
BA_ "Version" SG_ 1518 APSS_GST_Byte7 "21.02.04";
BA_ "Description" SG_ 1518 APSS_GST_Byte1 "TP Index : 108";
BA_ "UsrSigPurpose" SG_ 1518 APSS_GST_Byte1 4;
BA_ "UserSigValidity" SG_ 1518 APSS_GST_Byte1 0;
BA_REL_ "GenSigTimeoutTime" BU_SG_REL_ CGW_CCU SG_ 1518 APSS_GST_Byte1 0;
BA_ "NetworkRequest" SG_ 1518 APSS_GST_Byte1 0;
BA_ "NetworkRequestHoldingTime" SG_ 1518 APSS_GST_Byte1 5000;
BA_ "Version" SG_ 1518 APSS_GST_Byte1 "21.02.04";
BA_ "GenMsgCycleTime" BO_ 1007 0;
BA_ "Description" SG_ 1007 ATS_LEDBgtnsUpDn "This signal is  interior lamp brightness up/down control signal";
BA_ "GenSigSendType" SG_ 1007 ATS_LEDBgtnsUpDn 4;
BA_ "UserSigValidity" SG_ 1007 ATS_LEDBgtnsUpDn 3;
BA_REL_ "GenSigTimeoutTime" BU_SG_REL_ OHCL SG_ 1007 ATS_LEDBgtnsUpDn 0;
BA_ "Version" SG_ 1007 ATS_LEDBgtnsUpDn "20.04.05";
BA_ "Description" SG_ 1007 ATS_FrMoodOn_Req "Front mood lamp On/Off request";
BA_ "GenSigSendType" SG_ 1007 ATS_FrMoodOn_Req 4;
BA_ "UserSigValidity" SG_ 1007 ATS_FrMoodOn_Req 3;
BA_REL_ "GenSigTimeoutTime" BU_SG_REL_ OHCL SG_ 1007 ATS_FrMoodOn_Req 0;
BA_ "NetworkRequest" SG_ 1007 ATS_FrMoodOn_Req 0;
BA_ "NetworkRequestHoldingTime" SG_ 1007 ATS_FrMoodOn_Req 5000;
BA_ "Version" SG_ 1007 ATS_FrMoodOn_Req "20.06.09";
BA_ "Description" SG_ 1007 ATS_DoorOn_Req "Front Door switch On/Off request";
BA_ "GenSigSendType" SG_ 1007 ATS_DoorOn_Req 4;
BA_ "UserSigValidity" SG_ 1007 ATS_DoorOn_Req 3;
BA_REL_ "GenSigTimeoutTime" BU_SG_REL_ OHCL SG_ 1007 ATS_DoorOn_Req 0;
BA_ "NetworkRequest" SG_ 1007 ATS_DoorOn_Req 0;
BA_ "NetworkRequestHoldingTime" SG_ 1007 ATS_DoorOn_Req 5000;
BA_ "Version" SG_ 1007 ATS_DoorOn_Req "20.06.09";
BA_ "Description" SG_ 1007 ATS_RrMapLftOn_Req "Rear left map lamp On/Off request";
BA_ "GenSigSendType" SG_ 1007 ATS_RrMapLftOn_Req 4;
BA_ "UserSigValidity" SG_ 1007 ATS_RrMapLftOn_Req 3;
BA_REL_ "GenSigTimeoutTime" BU_SG_REL_ OHCL SG_ 1007 ATS_RrMapLftOn_Req 0;
BA_ "NetworkRequest" SG_ 1007 ATS_RrMapLftOn_Req 0;
BA_ "NetworkRequestHoldingTime" SG_ 1007 ATS_RrMapLftOn_Req 5000;
BA_ "Version" SG_ 1007 ATS_RrMapLftOn_Req "20.06.09";
BA_ "Description" SG_ 1007 ATS_RrMapRtOn_Req "Rear right map lamp On/Off request";
BA_ "GenSigSendType" SG_ 1007 ATS_RrMapRtOn_Req 4;
BA_ "UserSigValidity" SG_ 1007 ATS_RrMapRtOn_Req 3;
BA_REL_ "GenSigTimeoutTime" BU_SG_REL_ OHCL SG_ 1007 ATS_RrMapRtOn_Req 0;
BA_ "NetworkRequest" SG_ 1007 ATS_RrMapRtOn_Req 0;
BA_ "NetworkRequestHoldingTime" SG_ 1007 ATS_RrMapRtOn_Req 5000;
BA_ "Version" SG_ 1007 ATS_RrMapRtOn_Req "20.06.09";
BA_ "Description" SG_ 1007 ATS_RrRoomOn_Req "Rear room lamp On/Off request";
BA_ "GenSigSendType" SG_ 1007 ATS_RrRoomOn_Req 4;
BA_ "UserSigValidity" SG_ 1007 ATS_RrRoomOn_Req 3;
BA_REL_ "GenSigTimeoutTime" BU_SG_REL_ OHCL SG_ 1007 ATS_RrRoomOn_Req 0;
BA_ "NetworkRequest" SG_ 1007 ATS_RrRoomOn_Req 0;
BA_ "NetworkRequestHoldingTime" SG_ 1007 ATS_RrRoomOn_Req 5000;
BA_ "Version" SG_ 1007 ATS_RrRoomOn_Req "20.06.09";
BA_ "Description" SG_ 1007 ATS_LEDClrUpDn "This signal is  interior lamp color up/down control signal";
BA_ "GenSigSendType" SG_ 1007 ATS_LEDClrUpDn 4;
BA_ "UserSigValidity" SG_ 1007 ATS_LEDClrUpDn 3;
BA_REL_ "GenSigTimeoutTime" BU_SG_REL_ OHCL SG_ 1007 ATS_LEDClrUpDn 0;
BA_ "Version" SG_ 1007 ATS_LEDClrUpDn "20.04.05";
BA_ "Description" SG_ 1007 ATS_RrMoodOn_Req "Rear mood lamp On/Off request";
BA_ "GenSigSendType" SG_ 1007 ATS_RrMoodOn_Req 4;
BA_ "UserSigValidity" SG_ 1007 ATS_RrMoodOn_Req 3;
BA_REL_ "GenSigTimeoutTime" BU_SG_REL_ OHCL SG_ 1007 ATS_RrMoodOn_Req 0;
BA_ "NetworkRequest" SG_ 1007 ATS_RrMoodOn_Req 0;
BA_ "NetworkRequestHoldingTime" SG_ 1007 ATS_RrMoodOn_Req 5000;
BA_ "Version" SG_ 1007 ATS_RrMoodOn_Req "20.06.09";
BA_ "Description" SG_ 1007 ATS_LEDClr_Set "Interior Lamp LED Color Request";
BA_ "GenSigSendType" SG_ 1007 ATS_LEDClr_Set 4;
BA_ "UserSigValidity" SG_ 1007 ATS_LEDClr_Set 3;
BA_REL_ "GenSigTimeoutTime" BU_SG_REL_ OHCL SG_ 1007 ATS_LEDClr_Set 0;
BA_ "NetworkRequest" SG_ 1007 ATS_LEDClr_Set 0;
BA_ "NetworkRequestHoldingTime" SG_ 1007 ATS_LEDClr_Set 5000;
BA_ "Version" SG_ 1007 ATS_LEDClr_Set "20.06.09";
BA_ "Description" SG_ 1007 ATS_LEDBgtns_Set "Interior Lamp LED Brightness Request";
BA_ "GenSigSendType" SG_ 1007 ATS_LEDBgtns_Set 4;
BA_ "UserSigValidity" SG_ 1007 ATS_LEDBgtns_Set 3;
BA_REL_ "GenSigTimeoutTime" BU_SG_REL_ OHCL SG_ 1007 ATS_LEDBgtns_Set 0;
BA_ "NetworkRequest" SG_ 1007 ATS_LEDBgtns_Set 0;
BA_ "NetworkRequestHoldingTime" SG_ 1007 ATS_LEDBgtns_Set 5000;
BA_ "Version" SG_ 1007 ATS_LEDBgtns_Set "20.06.09";
BA_ "Description" SG_ 1007 ATS_LEDClrUpDnBtn "This signal is  interior lamp color up/down button control signal";
BA_ "GenSigSendType" SG_ 1007 ATS_LEDClrUpDnBtn 4;
BA_ "UserSigValidity" SG_ 1007 ATS_LEDClrUpDnBtn 3;
BA_ "Version" SG_ 1007 ATS_LEDClrUpDnBtn "20.06.07";
BA_ "Description" SG_ 1007 ATS_LEDBgtnsUpDnBtn "This signal is  interior lamp brightness up/down button control signal";
BA_ "GenSigSendType" SG_ 1007 ATS_LEDBgtnsUpDnBtn 4;
BA_ "UserSigValidity" SG_ 1007 ATS_LEDBgtnsUpDnBtn 3;
BA_ "Version" SG_ 1007 ATS_LEDBgtnsUpDnBtn "20.06.07";
BA_ "Description" SG_ 1007 ATS_FrMapLftOn_Req "Front left map lamp On/Off request";
BA_ "GenSigSendType" SG_ 1007 ATS_FrMapLftOn_Req 4;
BA_ "UserSigValidity" SG_ 1007 ATS_FrMapLftOn_Req 3;
BA_REL_ "GenSigTimeoutTime" BU_SG_REL_ OHCL SG_ 1007 ATS_FrMapLftOn_Req 0;
BA_ "NetworkRequest" SG_ 1007 ATS_FrMapLftOn_Req 0;
BA_ "NetworkRequestHoldingTime" SG_ 1007 ATS_FrMapLftOn_Req 5000;
BA_ "Version" SG_ 1007 ATS_FrMapLftOn_Req "20.06.09";
BA_ "Description" SG_ 1007 ATS_FrMapRtOn_Req "Front right map lamp On/Off request";
BA_ "GenSigSendType" SG_ 1007 ATS_FrMapRtOn_Req 4;
BA_ "UserSigValidity" SG_ 1007 ATS_FrMapRtOn_Req 3;
BA_REL_ "GenSigTimeoutTime" BU_SG_REL_ OHCL SG_ 1007 ATS_FrMapRtOn_Req 0;
BA_ "NetworkRequest" SG_ 1007 ATS_FrMapRtOn_Req 0;
BA_ "NetworkRequestHoldingTime" SG_ 1007 ATS_FrMapRtOn_Req 5000;
BA_ "Version" SG_ 1007 ATS_FrMapRtOn_Req "20.06.09";
BA_ "Description" SG_ 1007 ATS_FrRoomOn_Req "Front room lamp On/Off request";
BA_ "GenSigSendType" SG_ 1007 ATS_FrRoomOn_Req 4;
BA_ "UserSigValidity" SG_ 1007 ATS_FrRoomOn_Req 3;
BA_REL_ "GenSigTimeoutTime" BU_SG_REL_ OHCL SG_ 1007 ATS_FrRoomOn_Req 0;
BA_ "NetworkRequest" SG_ 1007 ATS_FrRoomOn_Req 0;
BA_ "NetworkRequestHoldingTime" SG_ 1007 ATS_FrRoomOn_Req 5000;
BA_ "Version" SG_ 1007 ATS_FrRoomOn_Req "20.06.09";
BA_ "GenMsgSendType" BO_ 992 0;
BA_ "Description" SG_ 992 BCM_Crc2Val "The data area for CRC calculation is based on the data length (DLC) of the message DB.

The CRC shall be calculated over the entire data block (excluding the CRC bytes) including the user data, alive counter and Data ID 

 

- CRC Polynomial (0x1D) , Initial Value : 0x00, XOR value : 0xFF, Data ID Mode : Both, Data ID : Message ID + 0xF800 

- The initial value is for CRC calculation and the message should be sent with the calculated result value. 

The mathematical expression to 8 bit CRC polynomial is given here. G(x) = x8 + x4 + x3 + x2 + 1";
BA_ "GenSigSendType" SG_ 992 BCM_Crc2Val 4;
BA_ "GenSigStartValue" SG_ 992 BCM_Crc2Val 255;
BA_ "UserSigValidity" SG_ 992 BCM_Crc2Val 0;
BA_ "Version" SG_ 992 BCM_Crc2Val "18.11.08";
BA_ "Description" SG_ 992 BCM_AlvCnt2Val "For the first transmission request for a data element the counter shall be initialized with 0 and shall be incremented by 1

for every subsequent send request. When the counter reaches the maximum value(0xE), then it shall restart with 0 for the next send request";
BA_ "GenSigSendType" SG_ 992 BCM_AlvCnt2Val 4;
BA_ "UserSigValidity" SG_ 992 BCM_AlvCnt2Val 0;
BA_ "Version" SG_ 992 BCM_AlvCnt2Val "18.11.08";
BA_ "GenSigSendType" SG_ 992 BAlarm_BglrAlrmCurrentSta 4;
BA_ "UserSigValidity" SG_ 992 BAlarm_BglrAlrmCurrentSta 0;
BA_REL_ "GenSigTimeoutTime" BU_SG_REL_ BLTN_CAM SG_ 992 BAlarm_BglrAlrmCurrentSta 1500;
BA_ "NetworkRequest" SG_ 992 BAlarm_BglrAlrmCurrentSta 0;
BA_ "NetworkRequestHoldingTime" SG_ 992 BAlarm_BglrAlrmCurrentSta 5000;
BA_ "Version" SG_ 992 BAlarm_BglrAlrmCurrentSta "17.12.00";
BA_ "GenSigSendType" SG_ 992 BAlarm_BglrAlrmSta 4;
BA_ "UserSigValidity" SG_ 992 BAlarm_BglrAlrmSta 0;
BA_ "NetworkRequest" SG_ 992 BAlarm_BglrAlrmSta 0;
BA_ "NetworkRequestHoldingTime" SG_ 992 BAlarm_BglrAlrmSta 5000;
BA_ "Version" SG_ 992 BAlarm_BglrAlrmSta "17.12.00";
BA_ "Description" SG_ 992 BAlarm_PncAlrmSta "-For TeleCranking Panic Function

-This signal send to IBOX";
BA_ "GenSigSendType" SG_ 992 BAlarm_PncAlrmSta 4;
BA_ "UserSigValidity" SG_ 992 BAlarm_PncAlrmSta 0;
BA_ "NetworkRequest" SG_ 992 BAlarm_PncAlrmSta 0;
BA_ "NetworkRequestHoldingTime" SG_ 992 BAlarm_PncAlrmSta 5000;
BA_ "Version" SG_ 992 BAlarm_PncAlrmSta "17.12.00";
BA_ "GenSigSendType" SG_ 992 BAlarm_StrtInhbtRlySta 4;
BA_ "UserSigValidity" SG_ 992 BAlarm_StrtInhbtRlySta 0;
BA_ "NetworkRequest" SG_ 992 BAlarm_StrtInhbtRlySta 0;
BA_ "NetworkRequestHoldingTime" SG_ 992 BAlarm_StrtInhbtRlySta 5000;
BA_ "Version" SG_ 992 BAlarm_StrtInhbtRlySta "17.12.00";
BA_ "GenSigSendType" SG_ 992 BAlarm_BrglrHrnRlySta 4;
BA_ "UserSigValidity" SG_ 992 BAlarm_BrglrHrnRlySta 0;
BA_ "NetworkRequest" SG_ 992 BAlarm_BrglrHrnRlySta 0;
BA_ "NetworkRequestHoldingTime" SG_ 992 BAlarm_BrglrHrnRlySta 5000;
BA_ "Version" SG_ 992 BAlarm_BrglrHrnRlySta "17.12.00";
BA_ "Description" SG_ 992 BCM_KeyInSta "Mechanical Key In SW State (If SMK option is On, C_KeyInSw always have  Off

 value)";
BA_ "GenSigSendType" SG_ 992 BCM_KeyInSta 4;
BA_ "UserSigValidity" SG_ 992 BCM_KeyInSta 0;
BA_REL_ "GenSigTimeoutTime" BU_SG_REL_ SWRC SG_ 992 BCM_KeyInSta 1500;
BA_REL_ "GenSigTimeoutTime" BU_SG_REL_ APSU SG_ 992 BCM_KeyInSta 1500;
BA_REL_ "GenSigTimeoutTime" BU_SG_REL_ SHVU_FR SG_ 992 BCM_KeyInSta 1500;
BA_REL_ "GenSigTimeoutTime" BU_SG_REL_ SHVU_RR SG_ 992 BCM_KeyInSta 1500;
BA_REL_ "GenSigTimeoutTime" BU_SG_REL_ DPSU SG_ 992 BCM_KeyInSta 1500;
BA_REL_ "GenSigTimeoutTime" BU_SG_REL_ DLBCU SG_ 992 BCM_KeyInSta 1500;
BA_REL_ "GenSigTimeoutTime" BU_SG_REL_ SGU SG_ 992 BCM_KeyInSta 1500;
BA_REL_ "GenSigTimeoutTime" BU_SG_REL_ ALBCU SG_ 992 BCM_KeyInSta 1500;
BA_ "NetworkRequest" SG_ 992 BCM_KeyInSta 0;
BA_ "NetworkRequestHoldingTime" SG_ 992 BCM_KeyInSta 5000;
BA_ "Version" SG_ 992 BCM_KeyInSta "17.12.00";
BA_ "GenSigSendType" SG_ 992 BCM_AccInSta 4;
BA_ "UserSigValidity" SG_ 992 BCM_AccInSta 0;
BA_REL_ "GenSigTimeoutTime" BU_SG_REL_ SWRC SG_ 992 BCM_AccInSta 1500;
BA_REL_ "GenSigTimeoutTime" BU_SG_REL_ APSU SG_ 992 BCM_AccInSta 1500;
BA_REL_ "GenSigTimeoutTime" BU_SG_REL_ SHVU_FR SG_ 992 BCM_AccInSta 1500;
BA_REL_ "GenSigTimeoutTime" BU_SG_REL_ SHVU_RR SG_ 992 BCM_AccInSta 1500;
BA_REL_ "GenSigTimeoutTime" BU_SG_REL_ DPSU SG_ 992 BCM_AccInSta 1500;
BA_REL_ "GenSigTimeoutTime" BU_SG_REL_ DLBCU SG_ 992 BCM_AccInSta 1500;
BA_REL_ "GenSigTimeoutTime" BU_SG_REL_ RRPSU SG_ 992 BCM_AccInSta 1500;
BA_REL_ "GenSigTimeoutTime" BU_SG_REL_ RLPSU SG_ 992 BCM_AccInSta 1500;
BA_REL_ "GenSigTimeoutTime" BU_SG_REL_ ATS SG_ 992 BCM_AccInSta 1500;
BA_REL_ "GenSigTimeoutTime" BU_SG_REL_ DSAU SG_ 992 BCM_AccInSta 1500;
BA_REL_ "GenSigTimeoutTime" BU_SG_REL_ ASAU SG_ 992 BCM_AccInSta 1500;
BA_REL_ "GenSigTimeoutTime" BU_SG_REL_ SGU SG_ 992 BCM_AccInSta 1500;
BA_REL_ "GenSigTimeoutTime" BU_SG_REL_ ALBCU SG_ 992 BCM_AccInSta 1500;
BA_ "NetworkRequest" SG_ 992 BCM_AccInSta 0;
BA_ "NetworkRequestHoldingTime" SG_ 992 BCM_AccInSta 5000;
BA_ "Version" SG_ 992 BCM_AccInSta "17.12.00";
BA_ "GenSigSendType" SG_ 992 BCM_Ign1InSta 4;
BA_ "UserSigValidity" SG_ 992 BCM_Ign1InSta 0;
BA_REL_ "GenSigTimeoutTime" BU_SG_REL_ SCM SG_ 992 BCM_Ign1InSta 1500;
BA_REL_ "GenSigTimeoutTime" BU_SG_REL_ SWRC SG_ 992 BCM_Ign1InSta 1500;
BA_REL_ "GenSigTimeoutTime" BU_SG_REL_ APSU SG_ 992 BCM_Ign1InSta 1500;
BA_REL_ "GenSigTimeoutTime" BU_SG_REL_ RLHV SG_ 992 BCM_Ign1InSta 1500;
BA_REL_ "GenSigTimeoutTime" BU_SG_REL_ RRHV SG_ 992 BCM_Ign1InSta 1500;
BA_REL_ "GenSigTimeoutTime" BU_SG_REL_ SHVU_FR SG_ 992 BCM_Ign1InSta 1500;
BA_REL_ "GenSigTimeoutTime" BU_SG_REL_ SHVU_RR SG_ 992 BCM_Ign1InSta 1500;
BA_REL_ "GenSigTimeoutTime" BU_SG_REL_ DPSU SG_ 992 BCM_Ign1InSta 1500;
BA_REL_ "GenSigTimeoutTime" BU_SG_REL_ DLBCU SG_ 992 BCM_Ign1InSta 1500;
BA_REL_ "GenSigTimeoutTime" BU_SG_REL_ PFSU SG_ 992 BCM_Ign1InSta 1500;
BA_REL_ "GenSigTimeoutTime" BU_SG_REL_ RRPSU SG_ 992 BCM_Ign1InSta 1500;
BA_REL_ "GenSigTimeoutTime" BU_SG_REL_ RLPSU SG_ 992 BCM_Ign1InSta 1500;
BA_REL_ "GenSigTimeoutTime" BU_SG_REL_ HOD SG_ 992 BCM_Ign1InSta 1500;
BA_REL_ "GenSigTimeoutTime" BU_SG_REL_ ATS SG_ 992 BCM_Ign1InSta 1500;
BA_REL_ "GenSigTimeoutTime" BU_SG_REL_ DSAU SG_ 992 BCM_Ign1InSta 1500;
BA_REL_ "GenSigTimeoutTime" BU_SG_REL_ ASAU SG_ 992 BCM_Ign1InSta 1500;
BA_REL_ "GenSigTimeoutTime" BU_SG_REL_ SGU SG_ 992 BCM_Ign1InSta 1500;
BA_REL_ "GenSigTimeoutTime" BU_SG_REL_ ALBCU SG_ 992 BCM_Ign1InSta 1500;
BA_ "NetworkRequest" SG_ 992 BCM_Ign1InSta 0;
BA_ "NetworkRequestHoldingTime" SG_ 992 BCM_Ign1InSta 5000;
BA_ "Version" SG_ 992 BCM_Ign1InSta "17.12.00";
BA_ "GenSigSendType" SG_ 992 BCM_Ign2InSta 4;
BA_ "UserSigValidity" SG_ 992 BCM_Ign2InSta 0;
BA_REL_ "GenSigTimeoutTime" BU_SG_REL_ SCM SG_ 992 BCM_Ign2InSta 1500;
BA_REL_ "GenSigTimeoutTime" BU_SG_REL_ SWRC SG_ 992 BCM_Ign2InSta 1500;
BA_REL_ "GenSigTimeoutTime" BU_SG_REL_ APSU SG_ 992 BCM_Ign2InSta 1500;
BA_REL_ "GenSigTimeoutTime" BU_SG_REL_ RLHV SG_ 992 BCM_Ign2InSta 1500;
BA_REL_ "GenSigTimeoutTime" BU_SG_REL_ RRHV SG_ 992 BCM_Ign2InSta 1500;
BA_REL_ "GenSigTimeoutTime" BU_SG_REL_ SHVU_FR SG_ 992 BCM_Ign2InSta 1500;
BA_REL_ "GenSigTimeoutTime" BU_SG_REL_ SHVU_RR SG_ 992 BCM_Ign2InSta 1500;
BA_REL_ "GenSigTimeoutTime" BU_SG_REL_ DPSU SG_ 992 BCM_Ign2InSta 1500;
BA_REL_ "GenSigTimeoutTime" BU_SG_REL_ DLBCU SG_ 992 BCM_Ign2InSta 1500;
BA_REL_ "GenSigTimeoutTime" BU_SG_REL_ PFSU SG_ 992 BCM_Ign2InSta 1500;
BA_REL_ "GenSigTimeoutTime" BU_SG_REL_ RRPSU SG_ 992 BCM_Ign2InSta 1500;
BA_REL_ "GenSigTimeoutTime" BU_SG_REL_ RLPSU SG_ 992 BCM_Ign2InSta 1500;
BA_REL_ "GenSigTimeoutTime" BU_SG_REL_ ATS SG_ 992 BCM_Ign2InSta 1500;
BA_REL_ "GenSigTimeoutTime" BU_SG_REL_ DSAU SG_ 992 BCM_Ign2InSta 1500;
BA_REL_ "GenSigTimeoutTime" BU_SG_REL_ ASAU SG_ 992 BCM_Ign2InSta 1500;
BA_REL_ "GenSigTimeoutTime" BU_SG_REL_ SGU SG_ 992 BCM_Ign2InSta 1500;
BA_REL_ "GenSigTimeoutTime" BU_SG_REL_ ALBCU SG_ 992 BCM_Ign2InSta 1500;
BA_ "NetworkRequest" SG_ 992 BCM_Ign2InSta 0;
BA_ "NetworkRequestHoldingTime" SG_ 992 BCM_Ign2InSta 5000;
BA_ "Version" SG_ 992 BCM_Ign2InSta "17.12.00";
BA_ "Description" SG_ 992 Warn_LftSEA_BDC "Command for SEA LH Warning Text on cluster";
BA_ "GenSigSendType" SG_ 992 Warn_LftSEA_BDC 4;
BA_ "UserSigValidity" SG_ 992 Warn_LftSEA_BDC 0;
BA_ "NetworkRequest" SG_ 992 Warn_LftSEA_BDC 0;
BA_ "NetworkRequestHoldingTime" SG_ 992 Warn_LftSEA_BDC 5000;
BA_ "Version" SG_ 992 Warn_LftSEA_BDC "20.08.02";
BA_ "GenSigSendType" SG_ 992 Warn_RhtSEA_BDC 4;
BA_ "UserSigValidity" SG_ 992 Warn_RhtSEA_BDC 0;
BA_ "NetworkRequest" SG_ 992 Warn_RhtSEA_BDC 0;
BA_ "NetworkRequestHoldingTime" SG_ 992 Warn_RhtSEA_BDC 5000;
BA_ "Version" SG_ 992 Warn_RhtSEA_BDC "20.08.02";
BA_ "GenMsgSendType" BO_ 994 0;
BA_ "Description" SG_ 994 BCM_Crc4Val "The data area for CRC calculation is based on the data length (DLC) of the message DB.

The CRC shall be calculated over the entire data block (excluding the CRC bytes) including the user data, alive counter and Data ID 

 

- CRC Polynomial (0x1D) , Initial Value : 0x00, XOR value : 0xFF, Data ID Mode : Both, Data ID : Message ID + 0xF800 

- The initial value is for CRC calculation and the message should be sent with the calculated result value. 

The mathematical expression to 8 bit CRC polynomial is given here. G(x) = x8 + x4 + x3 + x2 + 1";
BA_ "GenSigSendType" SG_ 994 BCM_Crc4Val 4;
BA_ "GenSigStartValue" SG_ 994 BCM_Crc4Val 255;
BA_ "UserSigValidity" SG_ 994 BCM_Crc4Val 0;
BA_ "Version" SG_ 994 BCM_Crc4Val "18.11.08";
BA_ "Description" SG_ 994 BCM_AlvCnt4Val "For the first transmission request for a data element the counter shall be initialized with 0 and shall be incremented by 1

for every subsequent send request. When the counter reaches the maximum value(0xE), then it shall restart with 0 for the next send request";
BA_ "GenSigSendType" SG_ 994 BCM_AlvCnt4Val 4;
BA_ "UserSigValidity" SG_ 994 BCM_AlvCnt4Val 0;
BA_ "Version" SG_ 994 BCM_AlvCnt4Val "18.11.08";
BA_ "Description" SG_ 994 Warn_BzrWrngSta "-(Old)C_WngBuzzer";
BA_ "GenSigSendType" SG_ 994 Warn_BzrWrngSta 4;
BA_ "UserSigValidity" SG_ 994 Warn_BzrWrngSta 0;
BA_ "NetworkRequest" SG_ 994 Warn_BzrWrngSta 0;
BA_ "NetworkRequestHoldingTime" SG_ 994 Warn_BzrWrngSta 5000;
BA_ "Version" SG_ 994 Warn_BzrWrngSta "17.12.00";
BA_ "Description" SG_ 994 Warn_BCMWrngSta "Warning command og BCM";
BA_ "GenSigSendType" SG_ 994 Warn_BCMWrngSta 4;
BA_ "UserSigValidity" SG_ 994 Warn_BCMWrngSta 0;
BA_ "NetworkRequest" SG_ 994 Warn_BCMWrngSta 0;
BA_ "NetworkRequestHoldingTime" SG_ 994 Warn_BCMWrngSta 5000;
BA_ "Version" SG_ 994 Warn_BCMWrngSta "17.12.00";
BA_ "Description" SG_ 994 ROA_RrBlwAutoOffReq "This signal is used for a request to Rear Blow Off (Auto Cut)";
BA_ "GenSigSendType" SG_ 994 ROA_RrBlwAutoOffReq 4;
BA_ "UserSigValidity" SG_ 994 ROA_RrBlwAutoOffReq 0;
BA_ "NetworkRequest" SG_ 994 ROA_RrBlwAutoOffReq 0;
BA_ "NetworkRequestHoldingTime" SG_ 994 ROA_RrBlwAutoOffReq 5000;
BA_ "Version" SG_ 994 ROA_RrBlwAutoOffReq "21.04.00";
BA_ "Description" SG_ 994 ROA_RegionOpt "A Euro NCAP Option signal (BDC only)";
BA_ "GenSigSendType" SG_ 994 ROA_RegionOpt 4;
BA_ "UserSigValidity" SG_ 994 ROA_RegionOpt 0;
BA_ "NetworkRequest" SG_ 994 ROA_RegionOpt 0;
BA_ "NetworkRequestHoldingTime" SG_ 994 ROA_RegionOpt 5000;
BA_ "Version" SG_ 994 ROA_RegionOpt "21.11.07";
BA_ "Description" SG_ 994 Warn_RrStRmndOpt "Rear Seat Reminder System Appled Option

(BDC Only Use 0x0 and 0x2 in Signal Value Table)";
BA_ "GenSigSendType" SG_ 994 Warn_RrStRmndOpt 4;
BA_ "UserSigValidity" SG_ 994 Warn_RrStRmndOpt 0;
BA_ "NetworkRequest" SG_ 994 Warn_RrStRmndOpt 0;
BA_ "NetworkRequestHoldingTime" SG_ 994 Warn_RrStRmndOpt 5000;
BA_ "Version" SG_ 994 Warn_RrStRmndOpt "21.04.00";
BA_ "Description" SG_ 994 Warn_RrStRmndAlrmOnReq "Rear Seat Reminder Alarm State";
BA_ "GenSigSendType" SG_ 994 Warn_RrStRmndAlrmOnReq 4;
BA_ "UserSigValidity" SG_ 994 Warn_RrStRmndAlrmOnReq 0;
BA_ "NetworkRequest" SG_ 994 Warn_RrStRmndAlrmOnReq 0;
BA_ "NetworkRequestHoldingTime" SG_ 994 Warn_RrStRmndAlrmOnReq 5000;
BA_ "Version" SG_ 994 Warn_RrStRmndAlrmOnReq "17.12.00";
BA_ "Description" SG_ 994 Warn_RrStRmndSysSta "Rear Seat Reminder Alarm System Enable(On)/Disable(Off) state";
BA_ "GenSigSendType" SG_ 994 Warn_RrStRmndSysSta 4;
BA_ "UserSigValidity" SG_ 994 Warn_RrStRmndSysSta 0;
BA_ "NetworkRequest" SG_ 994 Warn_RrStRmndSysSta 0;
BA_ "NetworkRequestHoldingTime" SG_ 994 Warn_RrStRmndSysSta 5000;
BA_ "Version" SG_ 994 Warn_RrStRmndSysSta "17.12.00";
BA_ "Description" SG_ 994 Warn_RrStRmndAlrmInfo "Rear Seat Reminder Warning request signal";
BA_ "GenSigSendType" SG_ 994 Warn_RrStRmndAlrmInfo 4;
BA_ "UserSigValidity" SG_ 994 Warn_RrStRmndAlrmInfo 0;
BA_REL_ "GenSigTimeoutTime" BU_SG_REL_ SWRC SG_ 994 Warn_RrStRmndAlrmInfo 1500;
BA_ "NetworkRequest" SG_ 994 Warn_RrStRmndAlrmInfo 0;
BA_ "NetworkRequestHoldingTime" SG_ 994 Warn_RrStRmndAlrmInfo 5000;
BA_ "Version" SG_ 994 Warn_RrStRmndAlrmInfo "18.11.02";
BA_ "Description" SG_ 994 Warn_RoaErr "ROA SENSOR Error(Malfunction)  signal";
BA_ "GenSigSendType" SG_ 994 Warn_RoaErr 4;
BA_ "UserSigValidity" SG_ 994 Warn_RoaErr 0;
BA_ "NetworkRequest" SG_ 994 Warn_RoaErr 0;
BA_ "NetworkRequestHoldingTime" SG_ 994 Warn_RoaErr 5000;
BA_ "Version" SG_ 994 Warn_RoaErr "18.07.01";
BA_ "Description" SG_ 994 IBU_RrStRmndAlrmSta "The IBU send burglar alarm state to ROA for priority

 - Burglar alarm has a high priority

    ROA detects after burglar alarm";
BA_ "GenSigSendType" SG_ 994 IBU_RrStRmndAlrmSta 4;
BA_ "UserSigValidity" SG_ 994 IBU_RrStRmndAlrmSta 0;
BA_ "NetworkRequest" SG_ 994 IBU_RrStRmndAlrmSta 0;
BA_ "NetworkRequestHoldingTime" SG_ 994 IBU_RrStRmndAlrmSta 5000;
BA_ "Version" SG_ 994 IBU_RrStRmndAlrmSta "19.04.06";
BA_ "Description" SG_ 994 WAL_FobSearching "IBU Walk Away Lock Fob Searching State for Radar ROA

(LIN_IBU_WAL_FobSearching for UIP ROA)";
BA_ "GenSigSendType" SG_ 994 WAL_FobSearching 4;
BA_ "UserSigValidity" SG_ 994 WAL_FobSearching 0;
BA_ "NetworkRequest" SG_ 994 WAL_FobSearching 0;
BA_ "NetworkRequestHoldingTime" SG_ 994 WAL_FobSearching 5000;
BA_ "Version" SG_ 994 WAL_FobSearching "19.06.00";
BA_ "GenMsgSendType" BO_ 997 0;
BA_ "Description" SG_ 997 BCM_Crc5Val "The data area for CRC calculation is based on the data length (DLC) of the message DB.

The CRC shall be calculated over the entire data block (excluding the CRC bytes) including the user data, alive counter and Data ID 

 

- CRC Polynomial (0x1D) , Initial Value : 0x00, XOR value : 0xFF, Data ID Mode : Both, Data ID : Message ID + 0xF800 

- The initial value is for CRC calculation and the message should be sent with the calculated result value. 

The mathematical expression to 8 bit CRC polynomial is given here. G(x) = x8 + x4 + x3 + x2 + 1";
BA_ "GenSigSendType" SG_ 997 BCM_Crc5Val 4;
BA_ "GenSigStartValue" SG_ 997 BCM_Crc5Val 255;
BA_ "UserSigValidity" SG_ 997 BCM_Crc5Val 0;
BA_ "Version" SG_ 997 BCM_Crc5Val "18.11.08";
BA_ "Description" SG_ 997 BCM_AlvCnt5Val "For the first transmission request for a data element the counter shall be initialized with 0 and shall be incremented by 1

for every subsequent send request. When the counter reaches the maximum value(0xE), then it shall restart with 0 for the next send request";
BA_ "GenSigSendType" SG_ 997 BCM_AlvCnt5Val 4;
BA_ "UserSigValidity" SG_ 997 BCM_AlvCnt5Val 0;
BA_ "Version" SG_ 997 BCM_AlvCnt5Val "18.11.08";
BA_ "Description" SG_ 997 PDW_OptTyp "this signal means PDW Option (Non, PDW-R, PDW-FR)

0x3: Reserved for the same Value Table as the ADAS_PRK Signal";
BA_ "GenSigSendType" SG_ 997 PDW_OptTyp 4;
BA_ "UserSigValidity" SG_ 997 PDW_OptTyp 3;
BA_ "NetworkRequest" SG_ 997 PDW_OptTyp 0;
BA_ "NetworkRequestHoldingTime" SG_ 997 PDW_OptTyp 5000;
BA_ "Version" SG_ 997 PDW_OptTyp "20.11.02";
BA_ "Description" SG_ 997 PDW_SysChkSndSta "-PDW System state check sound";
BA_ "GenSigSendType" SG_ 997 PDW_SysChkSndSta 4;
BA_ "UserSigValidity" SG_ 997 PDW_SysChkSndSta 0;
BA_ "NetworkRequest" SG_ 997 PDW_SysChkSndSta 0;
BA_ "NetworkRequestHoldingTime" SG_ 997 PDW_SysChkSndSta 5000;
BA_ "Version" SG_ 997 PDW_SysChkSndSta "17.12.00";
BA_ "Description" SG_ 997 PDW_SwIndOnReq "-PDW Switch Indicator On/Off Request

This signal is used for PDW-R and PDW-F/R";
BA_ "GenSigSendType" SG_ 997 PDW_SwIndOnReq 4;
BA_ "UserSigValidity" SG_ 997 PDW_SwIndOnReq 0;
BA_REL_ "GenSigTimeoutTime" BU_SG_REL_ FCS SG_ 997 PDW_SwIndOnReq 1500;
BA_ "NetworkRequest" SG_ 997 PDW_SwIndOnReq 0;
BA_ "NetworkRequestHoldingTime" SG_ 997 PDW_SwIndOnReq 5000;
BA_ "Version" SG_ 997 PDW_SwIndOnReq "18.03.05";
BA_ "Description" SG_ 997 PDW_SysOnSta "-PDW System operating status";
BA_ "GenSigSendType" SG_ 997 PDW_SysOnSta 4;
BA_ "UserSigValidity" SG_ 997 PDW_SysOnSta 0;
BA_ "NetworkRequest" SG_ 997 PDW_SysOnSta 0;
BA_ "NetworkRequestHoldingTime" SG_ 997 PDW_SysOnSta 5000;
BA_ "Version" SG_ 997 PDW_SysOnSta "17.12.00";
BA_ "Description" SG_ 997 PDW_FrCtWrngLvlDis "-Front center display";
BA_ "GenSigSendType" SG_ 997 PDW_FrCtWrngLvlDis 4;
BA_ "UserSigValidity" SG_ 997 PDW_FrCtWrngLvlDis 0;
BA_ "NetworkRequest" SG_ 997 PDW_FrCtWrngLvlDis 0;
BA_ "NetworkRequestHoldingTime" SG_ 997 PDW_FrCtWrngLvlDis 5000;
BA_ "Version" SG_ 997 PDW_FrCtWrngLvlDis "21.03.09";
BA_ "Description" SG_ 997 PDW_SysFlrSta "Ultrasonic sensor status - Blockage/Failure pop-up request";
BA_ "GenSigSendType" SG_ 997 PDW_SysFlrSta 4;
BA_ "UserSigValidity" SG_ 997 PDW_SysFlrSta 3;
BA_ "Version" SG_ 997 PDW_SysFlrSta "20.11.02";
BA_ "Description" SG_ 997 PDW_FrCtWrngSndSta "-Pas Warning Sound for AMP Speaker output";
BA_ "GenSigSendType" SG_ 997 PDW_FrCtWrngSndSta 4;
BA_ "UserSigValidity" SG_ 997 PDW_FrCtWrngSndSta 0;
BA_ "NetworkRequest" SG_ 997 PDW_FrCtWrngSndSta 0;
BA_ "NetworkRequestHoldingTime" SG_ 997 PDW_FrCtWrngSndSta 5000;
BA_ "Version" SG_ 997 PDW_FrCtWrngSndSta "20.04.02";
BA_ "Description" SG_ 997 PDW_FrLtWrngLvlDis "-Front Left display";
BA_ "GenSigSendType" SG_ 997 PDW_FrLtWrngLvlDis 4;
BA_ "UserSigValidity" SG_ 997 PDW_FrLtWrngLvlDis 0;
BA_ "NetworkRequest" SG_ 997 PDW_FrLtWrngLvlDis 0;
BA_ "NetworkRequestHoldingTime" SG_ 997 PDW_FrLtWrngLvlDis 5000;
BA_ "Version" SG_ 997 PDW_FrLtWrngLvlDis "21.03.09";
BA_ "Description" SG_ 997 PDW_CRBdDis "- Car Body Display";
BA_ "GenSigSendType" SG_ 997 PDW_CRBdDis 4;
BA_ "UserSigValidity" SG_ 997 PDW_CRBdDis 0;
BA_ "NetworkRequest" SG_ 997 PDW_CRBdDis 0;
BA_ "NetworkRequestHoldingTime" SG_ 997 PDW_CRBdDis 5000;
BA_ "Version" SG_ 997 PDW_CRBdDis "21.03.09";
BA_ "Description" SG_ 997 PDW_FrLtWrngSndSta "-Pas Warning Sound for AMP Speaker output";
BA_ "GenSigSendType" SG_ 997 PDW_FrLtWrngSndSta 4;
BA_ "UserSigValidity" SG_ 997 PDW_FrLtWrngSndSta 0;
BA_ "NetworkRequest" SG_ 997 PDW_FrLtWrngSndSta 0;
BA_ "NetworkRequestHoldingTime" SG_ 997 PDW_FrLtWrngSndSta 5000;
BA_ "Version" SG_ 997 PDW_FrLtWrngSndSta "20.04.02";
BA_ "Description" SG_ 997 PDW_FrRtWrngLvlDis "-Front Right display";
BA_ "GenSigSendType" SG_ 997 PDW_FrRtWrngLvlDis 4;
BA_ "UserSigValidity" SG_ 997 PDW_FrRtWrngLvlDis 0;
BA_ "NetworkRequest" SG_ 997 PDW_FrRtWrngLvlDis 0;
BA_ "NetworkRequestHoldingTime" SG_ 997 PDW_FrRtWrngLvlDis 5000;
BA_ "Version" SG_ 997 PDW_FrRtWrngLvlDis "21.03.09";
BA_ "Description" SG_ 997 PDW_FrRtWrngSndSta "-Pas Warning Sound for AMP Speaker output";
BA_ "GenSigSendType" SG_ 997 PDW_FrRtWrngSndSta 4;
BA_ "UserSigValidity" SG_ 997 PDW_FrRtWrngSndSta 0;
BA_ "NetworkRequest" SG_ 997 PDW_FrRtWrngSndSta 0;
BA_ "NetworkRequestHoldingTime" SG_ 997 PDW_FrRtWrngSndSta 5000;
BA_ "Version" SG_ 997 PDW_FrRtWrngSndSta "17.12.00";
BA_ "Description" SG_ 997 PDW_FrSnsrWrngLvlSta "-Front Sensor warning";
BA_ "GenSigSendType" SG_ 997 PDW_FrSnsrWrngLvlSta 4;
BA_ "UserSigValidity" SG_ 997 PDW_FrSnsrWrngLvlSta 0;
BA_ "NetworkRequest" SG_ 997 PDW_FrSnsrWrngLvlSta 0;
BA_ "NetworkRequestHoldingTime" SG_ 997 PDW_FrSnsrWrngLvlSta 5000;
BA_ "Version" SG_ 997 PDW_FrSnsrWrngLvlSta "17.12.00";
BA_ "GenMsgSendType" BO_ 1002 0;
BA_ "Description" SG_ 1002 BLTN_CAM_HU_UI_Mode "Display control of Built-in Cam UI mode. This Signal for Ethernet Type Built-in Cam.";
BA_ "GenSigSendType" SG_ 1002 BLTN_CAM_HU_UI_Mode 4;
BA_ "UserSigValidity" SG_ 1002 BLTN_CAM_HU_UI_Mode 1;
BA_REL_ "GenSigTimeoutTime" BU_SG_REL_ CGW_CCU SG_ 1002 BLTN_CAM_HU_UI_Mode 1500;
BA_ "Version" SG_ 1002 BLTN_CAM_HU_UI_Mode "21.07.04";
BA_ "Description" SG_ 1002 BLTN_CAM_SD_Format_Op_State "BLTN_CAM SD card format operation status.";
BA_ "GenSigSendType" SG_ 1002 BLTN_CAM_SD_Format_Op_State 4;
BA_ "UserSigValidity" SG_ 1002 BLTN_CAM_SD_Format_Op_State 1;
BA_REL_ "GenSigTimeoutTime" BU_SG_REL_ CGW_CCU SG_ 1002 BLTN_CAM_SD_Format_Op_State 1500;
BA_ "Version" SG_ 1002 BLTN_CAM_SD_Format_Op_State "21.07.04";
BA_ "Description" SG_ 1002 BLTN_CAM_PEV_Recorded "This Signal is sent just after the park event recorded.";
BA_ "GenSigSendType" SG_ 1002 BLTN_CAM_PEV_Recorded 4;
BA_ "UserSigValidity" SG_ 1002 BLTN_CAM_PEV_Recorded 1;
BA_REL_ "GenSigTimeoutTime" BU_SG_REL_ CGW_CCU SG_ 1002 BLTN_CAM_PEV_Recorded 1500;
BA_ "NetworkRequest" SG_ 1002 BLTN_CAM_PEV_Recorded 0;
BA_ "NetworkRequestHoldingTime" SG_ 1002 BLTN_CAM_PEV_Recorded 1000;
BA_ "Version" SG_ 1002 BLTN_CAM_PEV_Recorded "21.12.00";
BA_ "Description" SG_ 1002 BLTN_CAM_PEV_Count "This Signal is count of park event record.";
BA_ "GenSigSendType" SG_ 1002 BLTN_CAM_PEV_Count 4;
BA_ "UserSigValidity" SG_ 1002 BLTN_CAM_PEV_Count 1;
BA_REL_ "GenSigTimeoutTime" BU_SG_REL_ CGW_CCU SG_ 1002 BLTN_CAM_PEV_Count 1500;
BA_ "NetworkRequest" SG_ 1002 BLTN_CAM_PEV_Count 0;
BA_ "NetworkRequestHoldingTime" SG_ 1002 BLTN_CAM_PEV_Count 1000;
BA_ "Version" SG_ 1002 BLTN_CAM_PEV_Count "21.12.00";
BA_ "Description" SG_ 1002 BLTN_CAM_Ind_Req "This Signal is for HU Display Built-in Cam Indicator.";
BA_ "GenSigSendType" SG_ 1002 BLTN_CAM_Ind_Req 4;
BA_ "UserSigValidity" SG_ 1002 BLTN_CAM_Ind_Req 1;
BA_REL_ "GenSigTimeoutTime" BU_SG_REL_ CGW_CCU SG_ 1002 BLTN_CAM_Ind_Req 1500;
BA_ "Version" SG_ 1002 BLTN_CAM_Ind_Req "21.07.04";
BA_ "Description" SG_ 1002 BLTN_CAM_LVDS_Mode_State "This Signal is for LVDS output status";
BA_ "GenSigSendType" SG_ 1002 BLTN_CAM_LVDS_Mode_State 4;
BA_ "UserSigValidity" SG_ 1002 BLTN_CAM_LVDS_Mode_State 1;
BA_REL_ "GenSigTimeoutTime" BU_SG_REL_ CGW_CCU SG_ 1002 BLTN_CAM_LVDS_Mode_State 1500;
BA_ "Version" SG_ 1002 BLTN_CAM_LVDS_Mode_State "21.07.04";
BA_ "Description" SG_ 1002 BLTN_CAM_PrkOp_Termiate_Info "The signal for CCS service related with Built-in Cam Park operation termination.";
BA_ "GenSigSendType" SG_ 1002 BLTN_CAM_PrkOp_Termiate_Info 4;
BA_ "UserSigValidity" SG_ 1002 BLTN_CAM_PrkOp_Termiate_Info 0;
BA_REL_ "GenSigTimeoutTime" BU_SG_REL_ CGW_CCU SG_ 1002 BLTN_CAM_PrkOp_Termiate_Info 1500;
BA_ "NetworkRequest" SG_ 1002 BLTN_CAM_PrkOp_Termiate_Info 0;
BA_ "NetworkRequestHoldingTime" SG_ 1002 BLTN_CAM_PrkOp_Termiate_Info 1000;
BA_ "Version" SG_ 1002 BLTN_CAM_PrkOp_Termiate_Info "21.12.00";
BA_ "Description" SG_ 1002 BLTN_CAM_Display "Display control of Built-in Cam UI mode. This Signal for CAN Type Built-in Cam.(with Standard 5th Wide AVNT)";
BA_ "GenSigSendType" SG_ 1002 BLTN_CAM_Display 4;
BA_ "UserSigValidity" SG_ 1002 BLTN_CAM_Display 1;
BA_REL_ "GenSigTimeoutTime" BU_SG_REL_ CGW_CCU SG_ 1002 BLTN_CAM_Display 1500;
BA_ "Version" SG_ 1002 BLTN_CAM_Display "21.07.04";
BA_ "Description" SG_ 1002 BLTN_CAM_WiFi_State "BLTN_CAM WiFi Stattus";
BA_ "GenSigSendType" SG_ 1002 BLTN_CAM_WiFi_State 4;
BA_ "UserSigValidity" SG_ 1002 BLTN_CAM_WiFi_State 1;
BA_REL_ "GenSigTimeoutTime" BU_SG_REL_ CGW_CCU SG_ 1002 BLTN_CAM_WiFi_State 1500;
BA_ "Version" SG_ 1002 BLTN_CAM_WiFi_State "21.07.04";
BA_ "GenMsgSendType" BO_ 2353206529 0;
BA_ "GenMsgCycleTimeFast" BO_ 2353206529 0;
BA_ "GenMsgNrOfRepetition" BO_ 2353206529 0;
BA_ "VFrameFormat" BO_ 2353206529 1;
BA_ "Description" SG_ 2353206529 CLU_Crc20Val "The data area for CRC calculation is based on the data length (DLC) of the message DB.

The CRC shall be calculated over the entire data block (excluding the CRC bytes) including the user data, alive counter and Data ID

 

- CRC Polynomial (0x1021) , Initial Value : 0xFFFF, XOR value : 0x0000, Data ID : Message ID + 0xF800 

- The initial value is for CRC calculation and the message should be sent with the calculated result value. 

- The mathematical expression to 16 bit CRC polynomial is given here. G(x) = x16 + x12 + x5 + 1";
BA_ "GenSigStartValue" SG_ 2353206529 CLU_Crc20Val 65535;
BA_ "UserSigValidity" SG_ 2353206529 CLU_Crc20Val 3;
BA_ "Version" SG_ 2353206529 CLU_Crc20Val "19.01.06";
BA_ "Description" SG_ 2353206529 CLU_AlvCnt20Val "For the first transmission request for a data element the counter shall be initialized with 0 and shall be incremented by 1 for every subsequent send request. 

When the counter reaches the maximum value(0xFF), then it shall restart with 0 for the next send request";
BA_ "UserSigValidity" SG_ 2353206529 CLU_AlvCnt20Val 3;
BA_ "Version" SG_ 2353206529 CLU_AlvCnt20Val "19.01.06";
BA_ "Description" SG_ 2353206529 CLU_SndType "This signal is for sound type of Cluster.

The Cluster applied buzzer is can generate only on channel sound

and the Cluster applied speaker can generate multi channel sound.";
BA_ "UserSigValidity" SG_ 2353206529 CLU_SndType 3;
BA_ "Version" SG_ 2353206529 CLU_SndType "19.01.08";
BA_ "Description" SG_ 2353206529 CLU_ClusterUSM "USM application of Cluster

If USM is applied in Cluster, Signal send 0x1";
BA_ "UserSigValidity" SG_ 2353206529 CLU_ClusterUSM 3;
BA_REL_ "GenSigTimeoutTime" BU_SG_REL_ WPC SG_ 2353206529 CLU_ClusterUSM 1500;
BA_ "Version" SG_ 2353206529 CLU_ClusterUSM "20.06.05";
BA_ "GenMsgSendType" BO_ 2353206530 0;
BA_ "GenMsgCycleTimeFast" BO_ 2353206530 0;
BA_ "GenMsgNrOfRepetition" BO_ 2353206530 0;
BA_ "VFrameFormat" BO_ 2353206530 1;
BA_ "GenMsgSendType" BO_ 2328014852 0;
BA_ "GenMsgCycleTimeFast" BO_ 2328014852 0;
BA_ "GenMsgNrOfRepetition" BO_ 2328014852 0;
BA_ "VFrameFormat" BO_ 2328014852 1;
BA_ "GenMsgCycleTime" BO_ 1963 0;
BA_ "GenMsgCycleTimeFast" BO_ 1963 0;
BA_ "GenMsgNrOfRepetition" BO_ 1963 0;
BA_ "DiagResponse" BO_ 1963 1;
BA_ "GenMsgILSupport" BO_ 1963 0;
BA_ "TpMessage" BO_ 1963 1;
BA_ "TpTxIndex" BO_ 1963 156;
BA_ "Description" SG_ 1963 DPSU_GST_Byte0 "TP Index : 156";
BA_ "UsrSigPurpose" SG_ 1963 DPSU_GST_Byte0 4;
BA_ "UserSigValidity" SG_ 1963 DPSU_GST_Byte0 0;
BA_REL_ "GenSigTimeoutTime" BU_SG_REL_ CGW_CCU SG_ 1963 DPSU_GST_Byte0 0;
BA_ "NetworkRequest" SG_ 1963 DPSU_GST_Byte0 0;
BA_ "NetworkRequestHoldingTime" SG_ 1963 DPSU_GST_Byte0 5000;
BA_ "Version" SG_ 1963 DPSU_GST_Byte0 "21.11.07";
BA_ "Description" SG_ 1963 DPSU_GST_Byte2 "TP Index : 156";
BA_ "UsrSigPurpose" SG_ 1963 DPSU_GST_Byte2 4;
BA_ "UserSigValidity" SG_ 1963 DPSU_GST_Byte2 0;
BA_REL_ "GenSigTimeoutTime" BU_SG_REL_ CGW_CCU SG_ 1963 DPSU_GST_Byte2 0;
BA_ "NetworkRequest" SG_ 1963 DPSU_GST_Byte2 0;
BA_ "NetworkRequestHoldingTime" SG_ 1963 DPSU_GST_Byte2 5000;
BA_ "Version" SG_ 1963 DPSU_GST_Byte2 "21.11.07";
BA_ "Description" SG_ 1963 DPSU_GST_Byte3 "TP Index : 156";
BA_ "UsrSigPurpose" SG_ 1963 DPSU_GST_Byte3 4;
BA_ "UserSigValidity" SG_ 1963 DPSU_GST_Byte3 0;
BA_REL_ "GenSigTimeoutTime" BU_SG_REL_ CGW_CCU SG_ 1963 DPSU_GST_Byte3 0;
BA_ "NetworkRequest" SG_ 1963 DPSU_GST_Byte3 0;
BA_ "NetworkRequestHoldingTime" SG_ 1963 DPSU_GST_Byte3 5000;
BA_ "Version" SG_ 1963 DPSU_GST_Byte3 "21.11.07";
BA_ "Description" SG_ 1963 DPSU_GST_Byte4 "TP Index : 156";
BA_ "UsrSigPurpose" SG_ 1963 DPSU_GST_Byte4 4;
BA_ "UserSigValidity" SG_ 1963 DPSU_GST_Byte4 0;
BA_REL_ "GenSigTimeoutTime" BU_SG_REL_ CGW_CCU SG_ 1963 DPSU_GST_Byte4 0;
BA_ "NetworkRequest" SG_ 1963 DPSU_GST_Byte4 0;
BA_ "NetworkRequestHoldingTime" SG_ 1963 DPSU_GST_Byte4 5000;
BA_ "Version" SG_ 1963 DPSU_GST_Byte4 "21.11.07";
BA_ "Description" SG_ 1963 DPSU_GST_Byte5 "TP Index : 156";
BA_ "UsrSigPurpose" SG_ 1963 DPSU_GST_Byte5 4;
BA_ "UserSigValidity" SG_ 1963 DPSU_GST_Byte5 0;
BA_REL_ "GenSigTimeoutTime" BU_SG_REL_ CGW_CCU SG_ 1963 DPSU_GST_Byte5 0;
BA_ "NetworkRequest" SG_ 1963 DPSU_GST_Byte5 0;
BA_ "NetworkRequestHoldingTime" SG_ 1963 DPSU_GST_Byte5 5000;
BA_ "Version" SG_ 1963 DPSU_GST_Byte5 "21.11.07";
BA_ "Description" SG_ 1963 DPSU_GST_Byte6 "TP Index : 156";
BA_ "UsrSigPurpose" SG_ 1963 DPSU_GST_Byte6 4;
BA_ "UserSigValidity" SG_ 1963 DPSU_GST_Byte6 0;
BA_REL_ "GenSigTimeoutTime" BU_SG_REL_ CGW_CCU SG_ 1963 DPSU_GST_Byte6 0;
BA_ "NetworkRequest" SG_ 1963 DPSU_GST_Byte6 0;
BA_ "NetworkRequestHoldingTime" SG_ 1963 DPSU_GST_Byte6 5000;
BA_ "Version" SG_ 1963 DPSU_GST_Byte6 "21.11.07";
BA_ "Description" SG_ 1963 DPSU_GST_Byte7 "TP Index : 156";
BA_ "UsrSigPurpose" SG_ 1963 DPSU_GST_Byte7 4;
BA_ "UserSigValidity" SG_ 1963 DPSU_GST_Byte7 0;
BA_REL_ "GenSigTimeoutTime" BU_SG_REL_ CGW_CCU SG_ 1963 DPSU_GST_Byte7 0;
BA_ "NetworkRequest" SG_ 1963 DPSU_GST_Byte7 0;
BA_ "NetworkRequestHoldingTime" SG_ 1963 DPSU_GST_Byte7 5000;
BA_ "Version" SG_ 1963 DPSU_GST_Byte7 "21.11.07";
BA_ "Description" SG_ 1963 DPSU_GST_Byte1 "TP Index : 156";
BA_ "UsrSigPurpose" SG_ 1963 DPSU_GST_Byte1 4;
BA_ "UserSigValidity" SG_ 1963 DPSU_GST_Byte1 0;
BA_REL_ "GenSigTimeoutTime" BU_SG_REL_ CGW_CCU SG_ 1963 DPSU_GST_Byte1 0;
BA_ "NetworkRequest" SG_ 1963 DPSU_GST_Byte1 0;
BA_ "NetworkRequestHoldingTime" SG_ 1963 DPSU_GST_Byte1 5000;
BA_ "Version" SG_ 1963 DPSU_GST_Byte1 "21.11.07";
BA_ "GenMsgCycleTime" BO_ 1422 0;
BA_ "GenMsgCycleTimeFast" BO_ 1422 0;
BA_ "GenMsgNrOfRepetition" BO_ 1422 0;
BA_ "DiagResponse" BO_ 1422 1;
BA_ "GenMsgILSupport" BO_ 1422 0;
BA_ "TpMessage" BO_ 1422 1;
BA_ "TpTxIndex" BO_ 1422 95;
BA_ "Description" SG_ 1422 EMCU_GST_Byte0 "TP Index : 95";
BA_ "UsrSigPurpose" SG_ 1422 EMCU_GST_Byte0 4;
BA_ "UserSigValidity" SG_ 1422 EMCU_GST_Byte0 3;
BA_REL_ "GenSigTimeoutTime" BU_SG_REL_ CGW_CCU SG_ 1422 EMCU_GST_Byte0 0;
BA_ "Version" SG_ 1422 EMCU_GST_Byte0 "21.05.04";
BA_ "Description" SG_ 1422 EMCU_GST_Byte2 "TP Index : 95";
BA_ "UsrSigPurpose" SG_ 1422 EMCU_GST_Byte2 4;
BA_ "UserSigValidity" SG_ 1422 EMCU_GST_Byte2 3;
BA_REL_ "GenSigTimeoutTime" BU_SG_REL_ CGW_CCU SG_ 1422 EMCU_GST_Byte2 0;
BA_ "Version" SG_ 1422 EMCU_GST_Byte2 "21.05.04";
BA_ "Description" SG_ 1422 EMCU_GST_Byte3 "TP Index : 95";
BA_ "UsrSigPurpose" SG_ 1422 EMCU_GST_Byte3 4;
BA_ "UserSigValidity" SG_ 1422 EMCU_GST_Byte3 3;
BA_REL_ "GenSigTimeoutTime" BU_SG_REL_ CGW_CCU SG_ 1422 EMCU_GST_Byte3 0;
BA_ "Version" SG_ 1422 EMCU_GST_Byte3 "21.05.04";
BA_ "Description" SG_ 1422 EMCU_GST_Byte4 "TP Index : 95";
BA_ "UsrSigPurpose" SG_ 1422 EMCU_GST_Byte4 4;
BA_ "UserSigValidity" SG_ 1422 EMCU_GST_Byte4 3;
BA_REL_ "GenSigTimeoutTime" BU_SG_REL_ CGW_CCU SG_ 1422 EMCU_GST_Byte4 0;
BA_ "Version" SG_ 1422 EMCU_GST_Byte4 "21.05.04";
BA_ "Description" SG_ 1422 EMCU_GST_Byte5 "TP Index : 95";
BA_ "UsrSigPurpose" SG_ 1422 EMCU_GST_Byte5 4;
BA_ "UserSigValidity" SG_ 1422 EMCU_GST_Byte5 3;
BA_REL_ "GenSigTimeoutTime" BU_SG_REL_ CGW_CCU SG_ 1422 EMCU_GST_Byte5 0;
BA_ "Version" SG_ 1422 EMCU_GST_Byte5 "21.05.04";
BA_ "Description" SG_ 1422 EMCU_GST_Byte6 "TP Index : 95";
BA_ "UsrSigPurpose" SG_ 1422 EMCU_GST_Byte6 4;
BA_ "UserSigValidity" SG_ 1422 EMCU_GST_Byte6 3;
BA_REL_ "GenSigTimeoutTime" BU_SG_REL_ CGW_CCU SG_ 1422 EMCU_GST_Byte6 0;
BA_ "Version" SG_ 1422 EMCU_GST_Byte6 "21.05.04";
BA_ "Description" SG_ 1422 EMCU_GST_Byte7 "TP Index : 95";
BA_ "UsrSigPurpose" SG_ 1422 EMCU_GST_Byte7 4;
BA_ "UserSigValidity" SG_ 1422 EMCU_GST_Byte7 3;
BA_REL_ "GenSigTimeoutTime" BU_SG_REL_ CGW_CCU SG_ 1422 EMCU_GST_Byte7 0;
BA_ "Version" SG_ 1422 EMCU_GST_Byte7 "21.05.04";
BA_ "Description" SG_ 1422 EMCU_GST_Byte1 "TP Index : 95";
BA_ "UsrSigPurpose" SG_ 1422 EMCU_GST_Byte1 4;
BA_ "UserSigValidity" SG_ 1422 EMCU_GST_Byte1 3;
BA_REL_ "GenSigTimeoutTime" BU_SG_REL_ CGW_CCU SG_ 1422 EMCU_GST_Byte1 0;
BA_ "Version" SG_ 1422 EMCU_GST_Byte1 "21.05.04";
BA_ "GenMsgCycleTime" BO_ 1943 0;
BA_ "GenMsgCycleTimeFast" BO_ 1943 0;
BA_ "GenMsgNrOfRepetition" BO_ 1943 0;
BA_ "DiagRequest" BO_ 1943 1;
BA_ "GenMsgILSupport" BO_ 1943 0;
BA_ "TpMessage" BO_ 1943 1;
BA_ "TpTxIndex" BO_ 1943 109;
BA_ "Description" SG_ 1943 GST_APSU_Byte0 "TP Index : 109";
BA_ "UsrSigPurpose" SG_ 1943 GST_APSU_Byte0 3;
BA_ "UserSigValidity" SG_ 1943 GST_APSU_Byte0 0;
BA_REL_ "GenSigTimeoutTime" BU_SG_REL_ APSU SG_ 1943 GST_APSU_Byte0 0;
BA_ "NetworkRequest" SG_ 1943 GST_APSU_Byte0 0;
BA_ "NetworkRequestHoldingTime" SG_ 1943 GST_APSU_Byte0 5000;
BA_ "Version" SG_ 1943 GST_APSU_Byte0 "21.02.04";
BA_ "Description" SG_ 1943 GST_APSU_Byte2 "TP Index : 109";
BA_ "UsrSigPurpose" SG_ 1943 GST_APSU_Byte2 3;
BA_ "UserSigValidity" SG_ 1943 GST_APSU_Byte2 0;
BA_REL_ "GenSigTimeoutTime" BU_SG_REL_ APSU SG_ 1943 GST_APSU_Byte2 0;
BA_ "NetworkRequest" SG_ 1943 GST_APSU_Byte2 0;
BA_ "NetworkRequestHoldingTime" SG_ 1943 GST_APSU_Byte2 5000;
BA_ "Version" SG_ 1943 GST_APSU_Byte2 "21.02.04";
BA_ "Description" SG_ 1943 GST_APSU_Byte3 "TP Index : 109";
BA_ "UsrSigPurpose" SG_ 1943 GST_APSU_Byte3 3;
BA_ "UserSigValidity" SG_ 1943 GST_APSU_Byte3 0;
BA_REL_ "GenSigTimeoutTime" BU_SG_REL_ APSU SG_ 1943 GST_APSU_Byte3 0;
BA_ "NetworkRequest" SG_ 1943 GST_APSU_Byte3 0;
BA_ "NetworkRequestHoldingTime" SG_ 1943 GST_APSU_Byte3 5000;
BA_ "Version" SG_ 1943 GST_APSU_Byte3 "21.02.04";
BA_ "Description" SG_ 1943 GST_APSU_Byte4 "TP Index : 109";
BA_ "UsrSigPurpose" SG_ 1943 GST_APSU_Byte4 3;
BA_ "UserSigValidity" SG_ 1943 GST_APSU_Byte4 0;
BA_REL_ "GenSigTimeoutTime" BU_SG_REL_ APSU SG_ 1943 GST_APSU_Byte4 0;
BA_ "NetworkRequest" SG_ 1943 GST_APSU_Byte4 0;
BA_ "NetworkRequestHoldingTime" SG_ 1943 GST_APSU_Byte4 5000;
BA_ "Version" SG_ 1943 GST_APSU_Byte4 "21.02.04";
BA_ "Description" SG_ 1943 GST_APSU_Byte5 "TP Index : 109";
BA_ "UsrSigPurpose" SG_ 1943 GST_APSU_Byte5 3;
BA_ "UserSigValidity" SG_ 1943 GST_APSU_Byte5 0;
BA_REL_ "GenSigTimeoutTime" BU_SG_REL_ APSU SG_ 1943 GST_APSU_Byte5 0;
BA_ "NetworkRequest" SG_ 1943 GST_APSU_Byte5 0;
BA_ "NetworkRequestHoldingTime" SG_ 1943 GST_APSU_Byte5 5000;
BA_ "Version" SG_ 1943 GST_APSU_Byte5 "21.02.04";
BA_ "Description" SG_ 1943 GST_APSU_Byte6 "TP Index : 109";
BA_ "UsrSigPurpose" SG_ 1943 GST_APSU_Byte6 3;
BA_ "UserSigValidity" SG_ 1943 GST_APSU_Byte6 0;
BA_REL_ "GenSigTimeoutTime" BU_SG_REL_ APSU SG_ 1943 GST_APSU_Byte6 0;
BA_ "NetworkRequest" SG_ 1943 GST_APSU_Byte6 0;
BA_ "NetworkRequestHoldingTime" SG_ 1943 GST_APSU_Byte6 5000;
BA_ "Version" SG_ 1943 GST_APSU_Byte6 "21.02.04";
BA_ "Description" SG_ 1943 GST_APSU_Byte7 "TP Index : 109";
BA_ "UsrSigPurpose" SG_ 1943 GST_APSU_Byte7 3;
BA_ "UserSigValidity" SG_ 1943 GST_APSU_Byte7 0;
BA_REL_ "GenSigTimeoutTime" BU_SG_REL_ APSU SG_ 1943 GST_APSU_Byte7 0;
BA_ "NetworkRequest" SG_ 1943 GST_APSU_Byte7 0;
BA_ "NetworkRequestHoldingTime" SG_ 1943 GST_APSU_Byte7 5000;
BA_ "Version" SG_ 1943 GST_APSU_Byte7 "21.02.04";
BA_ "Description" SG_ 1943 GST_APSU_Byte1 "TP Index : 109";
BA_ "UsrSigPurpose" SG_ 1943 GST_APSU_Byte1 3;
BA_ "UserSigValidity" SG_ 1943 GST_APSU_Byte1 0;
BA_REL_ "GenSigTimeoutTime" BU_SG_REL_ APSU SG_ 1943 GST_APSU_Byte1 0;
BA_ "NetworkRequest" SG_ 1943 GST_APSU_Byte1 0;
BA_ "NetworkRequestHoldingTime" SG_ 1943 GST_APSU_Byte1 5000;
BA_ "Version" SG_ 1943 GST_APSU_Byte1 "21.02.04";
BA_ "GenMsgCycleTime" BO_ 1955 0;
BA_ "GenMsgCycleTimeFast" BO_ 1955 0;
BA_ "GenMsgNrOfRepetition" BO_ 1955 0;
BA_ "DiagRequest" BO_ 1955 1;
BA_ "GenMsgILSupport" BO_ 1955 0;
BA_ "TpMessage" BO_ 1955 1;
BA_ "TpTxIndex" BO_ 1955 156;
BA_ "Description" SG_ 1955 GST_DPSU_Byte0 "TP Index : 156";
BA_ "UsrSigPurpose" SG_ 1955 GST_DPSU_Byte0 3;
BA_ "UserSigValidity" SG_ 1955 GST_DPSU_Byte0 0;
BA_REL_ "GenSigTimeoutTime" BU_SG_REL_ DPSU SG_ 1955 GST_DPSU_Byte0 0;
BA_ "NetworkRequest" SG_ 1955 GST_DPSU_Byte0 0;
BA_ "NetworkRequestHoldingTime" SG_ 1955 GST_DPSU_Byte0 5000;
BA_ "Version" SG_ 1955 GST_DPSU_Byte0 "21.11.07";
BA_ "Description" SG_ 1955 GST_DPSU_Byte2 "TP Index : 156";
BA_ "UsrSigPurpose" SG_ 1955 GST_DPSU_Byte2 3;
BA_ "UserSigValidity" SG_ 1955 GST_DPSU_Byte2 0;
BA_REL_ "GenSigTimeoutTime" BU_SG_REL_ DPSU SG_ 1955 GST_DPSU_Byte2 0;
BA_ "NetworkRequest" SG_ 1955 GST_DPSU_Byte2 0;
BA_ "NetworkRequestHoldingTime" SG_ 1955 GST_DPSU_Byte2 5000;
BA_ "Version" SG_ 1955 GST_DPSU_Byte2 "21.11.07";
BA_ "Description" SG_ 1955 GST_DPSU_Byte3 "TP Index : 156";
BA_ "UsrSigPurpose" SG_ 1955 GST_DPSU_Byte3 3;
BA_ "UserSigValidity" SG_ 1955 GST_DPSU_Byte3 0;
BA_REL_ "GenSigTimeoutTime" BU_SG_REL_ DPSU SG_ 1955 GST_DPSU_Byte3 0;
BA_ "NetworkRequest" SG_ 1955 GST_DPSU_Byte3 0;
BA_ "NetworkRequestHoldingTime" SG_ 1955 GST_DPSU_Byte3 5000;
BA_ "Version" SG_ 1955 GST_DPSU_Byte3 "21.11.07";
BA_ "Description" SG_ 1955 GST_DPSU_Byte4 "TP Index : 156";
BA_ "UsrSigPurpose" SG_ 1955 GST_DPSU_Byte4 3;
BA_ "UserSigValidity" SG_ 1955 GST_DPSU_Byte4 0;
BA_REL_ "GenSigTimeoutTime" BU_SG_REL_ DPSU SG_ 1955 GST_DPSU_Byte4 0;
BA_ "NetworkRequest" SG_ 1955 GST_DPSU_Byte4 0;
BA_ "NetworkRequestHoldingTime" SG_ 1955 GST_DPSU_Byte4 5000;
BA_ "Version" SG_ 1955 GST_DPSU_Byte4 "21.11.07";
BA_ "Description" SG_ 1955 GST_DPSU_Byte5 "TP Index : 156";
BA_ "UsrSigPurpose" SG_ 1955 GST_DPSU_Byte5 3;
BA_ "UserSigValidity" SG_ 1955 GST_DPSU_Byte5 0;
BA_REL_ "GenSigTimeoutTime" BU_SG_REL_ DPSU SG_ 1955 GST_DPSU_Byte5 0;
BA_ "NetworkRequest" SG_ 1955 GST_DPSU_Byte5 0;
BA_ "NetworkRequestHoldingTime" SG_ 1955 GST_DPSU_Byte5 5000;
BA_ "Version" SG_ 1955 GST_DPSU_Byte5 "21.11.07";
BA_ "Description" SG_ 1955 GST_DPSU_Byte6 "TP Index : 156";
BA_ "UsrSigPurpose" SG_ 1955 GST_DPSU_Byte6 3;
BA_ "UserSigValidity" SG_ 1955 GST_DPSU_Byte6 0;
BA_REL_ "GenSigTimeoutTime" BU_SG_REL_ DPSU SG_ 1955 GST_DPSU_Byte6 0;
BA_ "NetworkRequest" SG_ 1955 GST_DPSU_Byte6 0;
BA_ "NetworkRequestHoldingTime" SG_ 1955 GST_DPSU_Byte6 5000;
BA_ "Version" SG_ 1955 GST_DPSU_Byte6 "21.11.07";
BA_ "Description" SG_ 1955 GST_DPSU_Byte7 "TP Index : 156";
BA_ "UsrSigPurpose" SG_ 1955 GST_DPSU_Byte7 3;
BA_ "UserSigValidity" SG_ 1955 GST_DPSU_Byte7 0;
BA_REL_ "GenSigTimeoutTime" BU_SG_REL_ DPSU SG_ 1955 GST_DPSU_Byte7 0;
BA_ "NetworkRequest" SG_ 1955 GST_DPSU_Byte7 0;
BA_ "NetworkRequestHoldingTime" SG_ 1955 GST_DPSU_Byte7 5000;
BA_ "Version" SG_ 1955 GST_DPSU_Byte7 "21.11.07";
BA_ "Description" SG_ 1955 GST_DPSU_Byte1 "TP Index : 156";
BA_ "UsrSigPurpose" SG_ 1955 GST_DPSU_Byte1 3;
BA_ "UserSigValidity" SG_ 1955 GST_DPSU_Byte1 0;
BA_REL_ "GenSigTimeoutTime" BU_SG_REL_ DPSU SG_ 1955 GST_DPSU_Byte1 0;
BA_ "NetworkRequest" SG_ 1955 GST_DPSU_Byte1 0;
BA_ "NetworkRequestHoldingTime" SG_ 1955 GST_DPSU_Byte1 5000;
BA_ "Version" SG_ 1955 GST_DPSU_Byte1 "21.11.07";
BA_ "GenMsgCycleTime" BO_ 1414 0;
BA_ "GenMsgCycleTimeFast" BO_ 1414 0;
BA_ "GenMsgNrOfRepetition" BO_ 1414 0;
BA_ "DiagRequest" BO_ 1414 1;
BA_ "GenMsgILSupport" BO_ 1414 0;
BA_ "TpMessage" BO_ 1414 1;
BA_ "TpTxIndex" BO_ 1414 95;
BA_ "Description" SG_ 1414 GST_EMCU_Byte0 "TP Index : 95";
BA_ "UsrSigPurpose" SG_ 1414 GST_EMCU_Byte0 3;
BA_ "UserSigValidity" SG_ 1414 GST_EMCU_Byte0 0;
BA_REL_ "GenSigTimeoutTime" BU_SG_REL_ EMCU SG_ 1414 GST_EMCU_Byte0 0;
BA_ "NetworkRequest" SG_ 1414 GST_EMCU_Byte0 0;
BA_ "NetworkRequestHoldingTime" SG_ 1414 GST_EMCU_Byte0 5000;
BA_ "Version" SG_ 1414 GST_EMCU_Byte0 "21.04.08";
BA_ "Description" SG_ 1414 GST_EMCU_Byte2 "TP Index : 95";
BA_ "UsrSigPurpose" SG_ 1414 GST_EMCU_Byte2 3;
BA_ "UserSigValidity" SG_ 1414 GST_EMCU_Byte2 0;
BA_REL_ "GenSigTimeoutTime" BU_SG_REL_ EMCU SG_ 1414 GST_EMCU_Byte2 0;
BA_ "NetworkRequest" SG_ 1414 GST_EMCU_Byte2 0;
BA_ "NetworkRequestHoldingTime" SG_ 1414 GST_EMCU_Byte2 5000;
BA_ "Version" SG_ 1414 GST_EMCU_Byte2 "21.04.08";
BA_ "Description" SG_ 1414 GST_EMCU_Byte3 "TP Index : 95";
BA_ "UsrSigPurpose" SG_ 1414 GST_EMCU_Byte3 3;
BA_ "UserSigValidity" SG_ 1414 GST_EMCU_Byte3 0;
BA_REL_ "GenSigTimeoutTime" BU_SG_REL_ EMCU SG_ 1414 GST_EMCU_Byte3 0;
BA_ "NetworkRequest" SG_ 1414 GST_EMCU_Byte3 0;
BA_ "NetworkRequestHoldingTime" SG_ 1414 GST_EMCU_Byte3 5000;
BA_ "Version" SG_ 1414 GST_EMCU_Byte3 "21.04.08";
BA_ "Description" SG_ 1414 GST_EMCU_Byte4 "TP Index : 95";
BA_ "UsrSigPurpose" SG_ 1414 GST_EMCU_Byte4 3;
BA_ "UserSigValidity" SG_ 1414 GST_EMCU_Byte4 0;
BA_REL_ "GenSigTimeoutTime" BU_SG_REL_ EMCU SG_ 1414 GST_EMCU_Byte4 0;
BA_ "NetworkRequest" SG_ 1414 GST_EMCU_Byte4 0;
BA_ "NetworkRequestHoldingTime" SG_ 1414 GST_EMCU_Byte4 5000;
BA_ "Version" SG_ 1414 GST_EMCU_Byte4 "21.04.08";
BA_ "Description" SG_ 1414 GST_EMCU_Byte5 "TP Index : 95";
BA_ "UsrSigPurpose" SG_ 1414 GST_EMCU_Byte5 3;
BA_ "UserSigValidity" SG_ 1414 GST_EMCU_Byte5 0;
BA_REL_ "GenSigTimeoutTime" BU_SG_REL_ EMCU SG_ 1414 GST_EMCU_Byte5 0;
BA_ "NetworkRequest" SG_ 1414 GST_EMCU_Byte5 0;
BA_ "NetworkRequestHoldingTime" SG_ 1414 GST_EMCU_Byte5 5000;
BA_ "Version" SG_ 1414 GST_EMCU_Byte5 "21.04.08";
BA_ "Description" SG_ 1414 GST_EMCU_Byte6 "TP Index : 95";
BA_ "UsrSigPurpose" SG_ 1414 GST_EMCU_Byte6 3;
BA_ "UserSigValidity" SG_ 1414 GST_EMCU_Byte6 0;
BA_REL_ "GenSigTimeoutTime" BU_SG_REL_ EMCU SG_ 1414 GST_EMCU_Byte6 0;
BA_ "NetworkRequest" SG_ 1414 GST_EMCU_Byte6 0;
BA_ "NetworkRequestHoldingTime" SG_ 1414 GST_EMCU_Byte6 5000;
BA_ "Version" SG_ 1414 GST_EMCU_Byte6 "21.04.08";
BA_ "Description" SG_ 1414 GST_EMCU_Byte7 "TP Index : 95";
BA_ "UsrSigPurpose" SG_ 1414 GST_EMCU_Byte7 3;
BA_ "UserSigValidity" SG_ 1414 GST_EMCU_Byte7 0;
BA_REL_ "GenSigTimeoutTime" BU_SG_REL_ EMCU SG_ 1414 GST_EMCU_Byte7 0;
BA_ "NetworkRequest" SG_ 1414 GST_EMCU_Byte7 0;
BA_ "NetworkRequestHoldingTime" SG_ 1414 GST_EMCU_Byte7 5000;
BA_ "Version" SG_ 1414 GST_EMCU_Byte7 "21.04.08";
BA_ "Description" SG_ 1414 GST_EMCU_Byte1 "TP Index : 95";
BA_ "UsrSigPurpose" SG_ 1414 GST_EMCU_Byte1 3;
BA_ "UserSigValidity" SG_ 1414 GST_EMCU_Byte1 0;
BA_REL_ "GenSigTimeoutTime" BU_SG_REL_ EMCU SG_ 1414 GST_EMCU_Byte1 0;
BA_ "NetworkRequest" SG_ 1414 GST_EMCU_Byte1 0;
BA_ "NetworkRequestHoldingTime" SG_ 1414 GST_EMCU_Byte1 5000;
BA_ "Version" SG_ 1414 GST_EMCU_Byte1 "21.04.08";
BA_ "GenMsgCycleTime" BO_ 1426 0;
BA_ "GenMsgCycleTimeFast" BO_ 1426 0;
BA_ "GenMsgNrOfRepetition" BO_ 1426 0;
BA_ "DiagRequest" BO_ 1426 1;
BA_ "GenMsgILSupport" BO_ 1426 0;
BA_ "TpMessage" BO_ 1426 1;
BA_ "TpTxIndex" BO_ 1426 55;
BA_ "Description" SG_ 1426 GST_RCM_Byte0 "TP Index : 55";
BA_ "UsrSigPurpose" SG_ 1426 GST_RCM_Byte0 3;
BA_ "UserSigValidity" SG_ 1426 GST_RCM_Byte0 0;
BA_REL_ "GenSigTimeoutTime" BU_SG_REL_ RCM SG_ 1426 GST_RCM_Byte0 0;
BA_ "NetworkRequest" SG_ 1426 GST_RCM_Byte0 0;
BA_ "NetworkRequestHoldingTime" SG_ 1426 GST_RCM_Byte0 5000;
BA_ "Version" SG_ 1426 GST_RCM_Byte0 "20.11.01";
BA_ "Description" SG_ 1426 GST_RCM_Byte2 "TP Index : 55";
BA_ "UsrSigPurpose" SG_ 1426 GST_RCM_Byte2 3;
BA_ "UserSigValidity" SG_ 1426 GST_RCM_Byte2 0;
BA_REL_ "GenSigTimeoutTime" BU_SG_REL_ RCM SG_ 1426 GST_RCM_Byte2 0;
BA_ "NetworkRequest" SG_ 1426 GST_RCM_Byte2 0;
BA_ "NetworkRequestHoldingTime" SG_ 1426 GST_RCM_Byte2 5000;
BA_ "Version" SG_ 1426 GST_RCM_Byte2 "20.11.01";
BA_ "Description" SG_ 1426 GST_RCM_Byte3 "TP Index : 55";
BA_ "UsrSigPurpose" SG_ 1426 GST_RCM_Byte3 3;
BA_ "UserSigValidity" SG_ 1426 GST_RCM_Byte3 0;
BA_REL_ "GenSigTimeoutTime" BU_SG_REL_ RCM SG_ 1426 GST_RCM_Byte3 0;
BA_ "NetworkRequest" SG_ 1426 GST_RCM_Byte3 0;
BA_ "NetworkRequestHoldingTime" SG_ 1426 GST_RCM_Byte3 5000;
BA_ "Version" SG_ 1426 GST_RCM_Byte3 "20.11.01";
BA_ "Description" SG_ 1426 GST_RCM_Byte4 "TP Index : 55";
BA_ "UsrSigPurpose" SG_ 1426 GST_RCM_Byte4 3;
BA_ "UserSigValidity" SG_ 1426 GST_RCM_Byte4 0;
BA_REL_ "GenSigTimeoutTime" BU_SG_REL_ RCM SG_ 1426 GST_RCM_Byte4 0;
BA_ "NetworkRequest" SG_ 1426 GST_RCM_Byte4 0;
BA_ "NetworkRequestHoldingTime" SG_ 1426 GST_RCM_Byte4 5000;
BA_ "Version" SG_ 1426 GST_RCM_Byte4 "20.11.01";
BA_ "Description" SG_ 1426 GST_RCM_Byte5 "TP Index : 55";
BA_ "UsrSigPurpose" SG_ 1426 GST_RCM_Byte5 3;
BA_ "UserSigValidity" SG_ 1426 GST_RCM_Byte5 0;
BA_REL_ "GenSigTimeoutTime" BU_SG_REL_ RCM SG_ 1426 GST_RCM_Byte5 0;
BA_ "NetworkRequest" SG_ 1426 GST_RCM_Byte5 0;
BA_ "NetworkRequestHoldingTime" SG_ 1426 GST_RCM_Byte5 5000;
BA_ "Version" SG_ 1426 GST_RCM_Byte5 "20.11.01";
BA_ "Description" SG_ 1426 GST_RCM_Byte6 "TP Index : 55";
BA_ "UsrSigPurpose" SG_ 1426 GST_RCM_Byte6 3;
BA_ "UserSigValidity" SG_ 1426 GST_RCM_Byte6 0;
BA_REL_ "GenSigTimeoutTime" BU_SG_REL_ RCM SG_ 1426 GST_RCM_Byte6 0;
BA_ "NetworkRequest" SG_ 1426 GST_RCM_Byte6 0;
BA_ "NetworkRequestHoldingTime" SG_ 1426 GST_RCM_Byte6 5000;
BA_ "Version" SG_ 1426 GST_RCM_Byte6 "20.11.01";
BA_ "Description" SG_ 1426 GST_RCM_Byte7 "TP Index : 55";
BA_ "UsrSigPurpose" SG_ 1426 GST_RCM_Byte7 3;
BA_ "UserSigValidity" SG_ 1426 GST_RCM_Byte7 0;
BA_REL_ "GenSigTimeoutTime" BU_SG_REL_ RCM SG_ 1426 GST_RCM_Byte7 0;
BA_ "NetworkRequest" SG_ 1426 GST_RCM_Byte7 0;
BA_ "NetworkRequestHoldingTime" SG_ 1426 GST_RCM_Byte7 5000;
BA_ "Version" SG_ 1426 GST_RCM_Byte7 "20.11.01";
BA_ "Description" SG_ 1426 GST_RCM_Byte1 "TP Index : 55";
BA_ "UsrSigPurpose" SG_ 1426 GST_RCM_Byte1 3;
BA_ "UserSigValidity" SG_ 1426 GST_RCM_Byte1 0;
BA_REL_ "GenSigTimeoutTime" BU_SG_REL_ RCM SG_ 1426 GST_RCM_Byte1 0;
BA_ "NetworkRequest" SG_ 1426 GST_RCM_Byte1 0;
BA_ "NetworkRequestHoldingTime" SG_ 1426 GST_RCM_Byte1 5000;
BA_ "Version" SG_ 1426 GST_RCM_Byte1 "20.11.01";
BA_ "GenMsgCycleTime" BO_ 1415 0;
BA_ "GenMsgCycleTimeFast" BO_ 1415 0;
BA_ "GenMsgNrOfRepetition" BO_ 1415 0;
BA_ "DiagRequest" BO_ 1415 1;
BA_ "GenMsgILSupport" BO_ 1415 0;
BA_ "TpMessage" BO_ 1415 1;
BA_ "TpTxIndex" BO_ 1415 226;
BA_ "Description" SG_ 1415 GST_RCS_Byte0 "TP Index : 226";
BA_ "UsrSigPurpose" SG_ 1415 GST_RCS_Byte0 3;
BA_ "UserSigValidity" SG_ 1415 GST_RCS_Byte0 0;
BA_REL_ "GenSigTimeoutTime" BU_SG_REL_ RCS SG_ 1415 GST_RCS_Byte0 0;
BA_ "NetworkRequest" SG_ 1415 GST_RCS_Byte0 0;
BA_ "NetworkRequestHoldingTime" SG_ 1415 GST_RCS_Byte0 5000;
BA_ "Version" SG_ 1415 GST_RCS_Byte0 "21.03.11";
BA_ "Description" SG_ 1415 GST_RCS_Byte2 "TP Index : 226";
BA_ "UsrSigPurpose" SG_ 1415 GST_RCS_Byte2 3;
BA_ "UserSigValidity" SG_ 1415 GST_RCS_Byte2 0;
BA_REL_ "GenSigTimeoutTime" BU_SG_REL_ RCS SG_ 1415 GST_RCS_Byte2 0;
BA_ "NetworkRequest" SG_ 1415 GST_RCS_Byte2 0;
BA_ "NetworkRequestHoldingTime" SG_ 1415 GST_RCS_Byte2 5000;
BA_ "Version" SG_ 1415 GST_RCS_Byte2 "21.03.11";
BA_ "Description" SG_ 1415 GST_RCS_Byte3 "TP Index : 226";
BA_ "UsrSigPurpose" SG_ 1415 GST_RCS_Byte3 3;
BA_ "UserSigValidity" SG_ 1415 GST_RCS_Byte3 0;
BA_REL_ "GenSigTimeoutTime" BU_SG_REL_ RCS SG_ 1415 GST_RCS_Byte3 0;
BA_ "NetworkRequest" SG_ 1415 GST_RCS_Byte3 0;
BA_ "NetworkRequestHoldingTime" SG_ 1415 GST_RCS_Byte3 5000;
BA_ "Version" SG_ 1415 GST_RCS_Byte3 "21.03.11";
BA_ "Description" SG_ 1415 GST_RCS_Byte4 "TP Index : 226";
BA_ "UsrSigPurpose" SG_ 1415 GST_RCS_Byte4 3;
BA_ "UserSigValidity" SG_ 1415 GST_RCS_Byte4 0;
BA_REL_ "GenSigTimeoutTime" BU_SG_REL_ RCS SG_ 1415 GST_RCS_Byte4 0;
BA_ "NetworkRequest" SG_ 1415 GST_RCS_Byte4 0;
BA_ "NetworkRequestHoldingTime" SG_ 1415 GST_RCS_Byte4 5000;
BA_ "Version" SG_ 1415 GST_RCS_Byte4 "21.03.11";
BA_ "Description" SG_ 1415 GST_RCS_Byte5 "TP Index : 226";
BA_ "UsrSigPurpose" SG_ 1415 GST_RCS_Byte5 3;
BA_ "UserSigValidity" SG_ 1415 GST_RCS_Byte5 0;
BA_REL_ "GenSigTimeoutTime" BU_SG_REL_ RCS SG_ 1415 GST_RCS_Byte5 0;
BA_ "NetworkRequest" SG_ 1415 GST_RCS_Byte5 0;
BA_ "NetworkRequestHoldingTime" SG_ 1415 GST_RCS_Byte5 5000;
BA_ "Version" SG_ 1415 GST_RCS_Byte5 "21.03.11";
BA_ "Description" SG_ 1415 GST_RCS_Byte6 "TP Index : 226";
BA_ "UsrSigPurpose" SG_ 1415 GST_RCS_Byte6 3;
BA_ "UserSigValidity" SG_ 1415 GST_RCS_Byte6 0;
BA_REL_ "GenSigTimeoutTime" BU_SG_REL_ RCS SG_ 1415 GST_RCS_Byte6 0;
BA_ "NetworkRequest" SG_ 1415 GST_RCS_Byte6 0;
BA_ "NetworkRequestHoldingTime" SG_ 1415 GST_RCS_Byte6 5000;
BA_ "Version" SG_ 1415 GST_RCS_Byte6 "21.03.11";
BA_ "Description" SG_ 1415 GST_RCS_Byte7 "TP Index : 226";
BA_ "UsrSigPurpose" SG_ 1415 GST_RCS_Byte7 3;
BA_ "UserSigValidity" SG_ 1415 GST_RCS_Byte7 0;
BA_REL_ "GenSigTimeoutTime" BU_SG_REL_ RCS SG_ 1415 GST_RCS_Byte7 0;
BA_ "NetworkRequest" SG_ 1415 GST_RCS_Byte7 0;
BA_ "NetworkRequestHoldingTime" SG_ 1415 GST_RCS_Byte7 5000;
BA_ "Version" SG_ 1415 GST_RCS_Byte7 "21.03.11";
BA_ "Description" SG_ 1415 GST_RCS_Byte1 "TP Index : 226";
BA_ "UsrSigPurpose" SG_ 1415 GST_RCS_Byte1 3;
BA_ "UserSigValidity" SG_ 1415 GST_RCS_Byte1 0;
BA_REL_ "GenSigTimeoutTime" BU_SG_REL_ RCS SG_ 1415 GST_RCS_Byte1 0;
BA_ "NetworkRequest" SG_ 1415 GST_RCS_Byte1 0;
BA_ "NetworkRequestHoldingTime" SG_ 1415 GST_RCS_Byte1 5000;
BA_ "Version" SG_ 1415 GST_RCS_Byte1 "21.03.11";
BA_ "GenMsgCycleTime" BO_ 1956 0;
BA_ "GenMsgCycleTimeFast" BO_ 1956 0;
BA_ "GenMsgNrOfRepetition" BO_ 1956 0;
BA_ "DiagRequest" BO_ 1956 1;
BA_ "GenMsgILSupport" BO_ 1956 0;
BA_ "TpMessage" BO_ 1956 1;
BA_ "TpTxIndex" BO_ 1956 172;
BA_ "Description" SG_ 1956 GST_SCM_Byte0 "TP Index : 172";
BA_ "UsrSigPurpose" SG_ 1956 GST_SCM_Byte0 3;
BA_ "UserSigValidity" SG_ 1956 GST_SCM_Byte0 0;
BA_REL_ "GenSigTimeoutTime" BU_SG_REL_ SCM SG_ 1956 GST_SCM_Byte0 0;
BA_ "NetworkRequest" SG_ 1956 GST_SCM_Byte0 0;
BA_ "NetworkRequestHoldingTime" SG_ 1956 GST_SCM_Byte0 5000;
BA_ "Version" SG_ 1956 GST_SCM_Byte0 "21.02.04";
BA_ "Description" SG_ 1956 GST_SCM_Byte2 "TP Index : 172";
BA_ "UsrSigPurpose" SG_ 1956 GST_SCM_Byte2 3;
BA_ "UserSigValidity" SG_ 1956 GST_SCM_Byte2 0;
BA_REL_ "GenSigTimeoutTime" BU_SG_REL_ SCM SG_ 1956 GST_SCM_Byte2 0;
BA_ "NetworkRequest" SG_ 1956 GST_SCM_Byte2 0;
BA_ "NetworkRequestHoldingTime" SG_ 1956 GST_SCM_Byte2 5000;
BA_ "Version" SG_ 1956 GST_SCM_Byte2 "21.02.04";
BA_ "Description" SG_ 1956 GST_SCM_Byte3 "TP Index : 172";
BA_ "UsrSigPurpose" SG_ 1956 GST_SCM_Byte3 3;
BA_ "UserSigValidity" SG_ 1956 GST_SCM_Byte3 0;
BA_REL_ "GenSigTimeoutTime" BU_SG_REL_ SCM SG_ 1956 GST_SCM_Byte3 0;
BA_ "NetworkRequest" SG_ 1956 GST_SCM_Byte3 0;
BA_ "NetworkRequestHoldingTime" SG_ 1956 GST_SCM_Byte3 5000;
BA_ "Version" SG_ 1956 GST_SCM_Byte3 "21.02.04";
BA_ "Description" SG_ 1956 GST_SCM_Byte4 "TP Index : 172";
BA_ "UsrSigPurpose" SG_ 1956 GST_SCM_Byte4 3;
BA_ "UserSigValidity" SG_ 1956 GST_SCM_Byte4 0;
BA_REL_ "GenSigTimeoutTime" BU_SG_REL_ SCM SG_ 1956 GST_SCM_Byte4 0;
BA_ "NetworkRequest" SG_ 1956 GST_SCM_Byte4 0;
BA_ "NetworkRequestHoldingTime" SG_ 1956 GST_SCM_Byte4 5000;
BA_ "Version" SG_ 1956 GST_SCM_Byte4 "21.02.04";
BA_ "Description" SG_ 1956 GST_SCM_Byte5 "TP Index : 172";
BA_ "UsrSigPurpose" SG_ 1956 GST_SCM_Byte5 3;
BA_ "UserSigValidity" SG_ 1956 GST_SCM_Byte5 0;
BA_REL_ "GenSigTimeoutTime" BU_SG_REL_ SCM SG_ 1956 GST_SCM_Byte5 0;
BA_ "NetworkRequest" SG_ 1956 GST_SCM_Byte5 0;
BA_ "NetworkRequestHoldingTime" SG_ 1956 GST_SCM_Byte5 5000;
BA_ "Version" SG_ 1956 GST_SCM_Byte5 "21.02.04";
BA_ "Description" SG_ 1956 GST_SCM_Byte6 "TP Index : 172";
BA_ "UsrSigPurpose" SG_ 1956 GST_SCM_Byte6 3;
BA_ "UserSigValidity" SG_ 1956 GST_SCM_Byte6 0;
BA_REL_ "GenSigTimeoutTime" BU_SG_REL_ SCM SG_ 1956 GST_SCM_Byte6 0;
BA_ "NetworkRequest" SG_ 1956 GST_SCM_Byte6 0;
BA_ "NetworkRequestHoldingTime" SG_ 1956 GST_SCM_Byte6 5000;
BA_ "Version" SG_ 1956 GST_SCM_Byte6 "21.02.04";
BA_ "Description" SG_ 1956 GST_SCM_Byte7 "TP Index : 172";
BA_ "UsrSigPurpose" SG_ 1956 GST_SCM_Byte7 3;
BA_ "UserSigValidity" SG_ 1956 GST_SCM_Byte7 0;
BA_REL_ "GenSigTimeoutTime" BU_SG_REL_ SCM SG_ 1956 GST_SCM_Byte7 0;
BA_ "NetworkRequest" SG_ 1956 GST_SCM_Byte7 0;
BA_ "NetworkRequestHoldingTime" SG_ 1956 GST_SCM_Byte7 5000;
BA_ "Version" SG_ 1956 GST_SCM_Byte7 "21.02.04";
BA_ "Description" SG_ 1956 GST_SCM_Byte1 "TP Index : 172";
BA_ "UsrSigPurpose" SG_ 1956 GST_SCM_Byte1 3;
BA_ "UserSigValidity" SG_ 1956 GST_SCM_Byte1 0;
BA_REL_ "GenSigTimeoutTime" BU_SG_REL_ SCM SG_ 1956 GST_SCM_Byte1 0;
BA_ "NetworkRequest" SG_ 1956 GST_SCM_Byte1 0;
BA_ "NetworkRequestHoldingTime" SG_ 1956 GST_SCM_Byte1 5000;
BA_ "Version" SG_ 1956 GST_SCM_Byte1 "21.02.04";
BA_ "GenMsgCycleTime" BO_ 1412 0;
BA_ "GenMsgCycleTimeFast" BO_ 1412 0;
BA_ "GenMsgNrOfRepetition" BO_ 1412 0;
BA_ "DiagRequest" BO_ 1412 1;
BA_ "GenMsgILSupport" BO_ 1412 0;
BA_ "TpMessage" BO_ 1412 1;
BA_ "TpTxIndex" BO_ 1412 233;
BA_ "Description" SG_ 1412 GST_SGU_Byte0 "TP Index : 233";
BA_ "UsrSigPurpose" SG_ 1412 GST_SGU_Byte0 3;
BA_ "UserSigValidity" SG_ 1412 GST_SGU_Byte0 0;
BA_REL_ "GenSigTimeoutTime" BU_SG_REL_ SGU SG_ 1412 GST_SGU_Byte0 0;
BA_ "NetworkRequest" SG_ 1412 GST_SGU_Byte0 0;
BA_ "NetworkRequestHoldingTime" SG_ 1412 GST_SGU_Byte0 5000;
BA_ "Version" SG_ 1412 GST_SGU_Byte0 "21.07.07";
BA_ "Description" SG_ 1412 GST_SGU_Byte2 "TP Index : 233";
BA_ "UsrSigPurpose" SG_ 1412 GST_SGU_Byte2 3;
BA_ "UserSigValidity" SG_ 1412 GST_SGU_Byte2 0;
BA_REL_ "GenSigTimeoutTime" BU_SG_REL_ SGU SG_ 1412 GST_SGU_Byte2 0;
BA_ "NetworkRequest" SG_ 1412 GST_SGU_Byte2 0;
BA_ "NetworkRequestHoldingTime" SG_ 1412 GST_SGU_Byte2 5000;
BA_ "Version" SG_ 1412 GST_SGU_Byte2 "21.07.07";
BA_ "Description" SG_ 1412 GST_SGU_Byte3 "TP Index : 233";
BA_ "UsrSigPurpose" SG_ 1412 GST_SGU_Byte3 3;
BA_ "UserSigValidity" SG_ 1412 GST_SGU_Byte3 0;
BA_REL_ "GenSigTimeoutTime" BU_SG_REL_ SGU SG_ 1412 GST_SGU_Byte3 0;
BA_ "NetworkRequest" SG_ 1412 GST_SGU_Byte3 0;
BA_ "NetworkRequestHoldingTime" SG_ 1412 GST_SGU_Byte3 5000;
BA_ "Version" SG_ 1412 GST_SGU_Byte3 "21.07.07";
BA_ "Description" SG_ 1412 GST_SGU_Byte4 "TP Index : 233";
BA_ "UsrSigPurpose" SG_ 1412 GST_SGU_Byte4 3;
BA_ "UserSigValidity" SG_ 1412 GST_SGU_Byte4 0;
BA_REL_ "GenSigTimeoutTime" BU_SG_REL_ SGU SG_ 1412 GST_SGU_Byte4 0;
BA_ "NetworkRequest" SG_ 1412 GST_SGU_Byte4 0;
BA_ "NetworkRequestHoldingTime" SG_ 1412 GST_SGU_Byte4 5000;
BA_ "Version" SG_ 1412 GST_SGU_Byte4 "21.07.07";
BA_ "Description" SG_ 1412 GST_SGU_Byte5 "TP Index : 233";
BA_ "UsrSigPurpose" SG_ 1412 GST_SGU_Byte5 3;
BA_ "UserSigValidity" SG_ 1412 GST_SGU_Byte5 0;
BA_REL_ "GenSigTimeoutTime" BU_SG_REL_ SGU SG_ 1412 GST_SGU_Byte5 0;
BA_ "NetworkRequest" SG_ 1412 GST_SGU_Byte5 0;
BA_ "NetworkRequestHoldingTime" SG_ 1412 GST_SGU_Byte5 5000;
BA_ "Version" SG_ 1412 GST_SGU_Byte5 "21.07.07";
BA_ "Description" SG_ 1412 GST_SGU_Byte6 "TP Index : 233";
BA_ "UsrSigPurpose" SG_ 1412 GST_SGU_Byte6 3;
BA_ "UserSigValidity" SG_ 1412 GST_SGU_Byte6 0;
BA_REL_ "GenSigTimeoutTime" BU_SG_REL_ SGU SG_ 1412 GST_SGU_Byte6 0;
BA_ "NetworkRequest" SG_ 1412 GST_SGU_Byte6 0;
BA_ "NetworkRequestHoldingTime" SG_ 1412 GST_SGU_Byte6 5000;
BA_ "Version" SG_ 1412 GST_SGU_Byte6 "21.07.07";
BA_ "Description" SG_ 1412 GST_SGU_Byte7 "TP Index : 233";
BA_ "UsrSigPurpose" SG_ 1412 GST_SGU_Byte7 3;
BA_ "UserSigValidity" SG_ 1412 GST_SGU_Byte7 0;
BA_REL_ "GenSigTimeoutTime" BU_SG_REL_ SGU SG_ 1412 GST_SGU_Byte7 0;
BA_ "NetworkRequest" SG_ 1412 GST_SGU_Byte7 0;
BA_ "NetworkRequestHoldingTime" SG_ 1412 GST_SGU_Byte7 5000;
BA_ "Version" SG_ 1412 GST_SGU_Byte7 "21.07.07";
BA_ "Description" SG_ 1412 GST_SGU_Byte1 "TP Index : 233";
BA_ "UsrSigPurpose" SG_ 1412 GST_SGU_Byte1 3;
BA_ "UserSigValidity" SG_ 1412 GST_SGU_Byte1 0;
BA_REL_ "GenSigTimeoutTime" BU_SG_REL_ SGU SG_ 1412 GST_SGU_Byte1 0;
BA_ "NetworkRequest" SG_ 1412 GST_SGU_Byte1 0;
BA_ "NetworkRequestHoldingTime" SG_ 1412 GST_SGU_Byte1 5000;
BA_ "Version" SG_ 1412 GST_SGU_Byte1 "21.07.07";
BA_ "GenMsgCycleTime" BO_ 1959 0;
BA_ "GenMsgCycleTimeFast" BO_ 1959 0;
BA_ "GenMsgNrOfRepetition" BO_ 1959 0;
BA_ "DiagRequest" BO_ 1959 1;
BA_ "GenMsgILSupport" BO_ 1959 0;
BA_ "TpMessage" BO_ 1959 1;
BA_ "TpTxIndex" BO_ 1959 175;
BA_ "Description" SG_ 1959 GST_SWRC_Byte0 "TP Index : 175";
BA_ "UsrSigPurpose" SG_ 1959 GST_SWRC_Byte0 3;
BA_ "UserSigValidity" SG_ 1959 GST_SWRC_Byte0 0;
BA_REL_ "GenSigTimeoutTime" BU_SG_REL_ SWRC SG_ 1959 GST_SWRC_Byte0 0;
BA_ "NetworkRequest" SG_ 1959 GST_SWRC_Byte0 0;
BA_ "NetworkRequestHoldingTime" SG_ 1959 GST_SWRC_Byte0 5000;
BA_ "Version" SG_ 1959 GST_SWRC_Byte0 "21.02.04";
BA_ "Description" SG_ 1959 GST_SWRC_Byte2 "TP Index : 175";
BA_ "UsrSigPurpose" SG_ 1959 GST_SWRC_Byte2 3;
BA_ "UserSigValidity" SG_ 1959 GST_SWRC_Byte2 0;
BA_REL_ "GenSigTimeoutTime" BU_SG_REL_ SWRC SG_ 1959 GST_SWRC_Byte2 0;
BA_ "NetworkRequest" SG_ 1959 GST_SWRC_Byte2 0;
BA_ "NetworkRequestHoldingTime" SG_ 1959 GST_SWRC_Byte2 5000;
BA_ "Version" SG_ 1959 GST_SWRC_Byte2 "21.02.04";
BA_ "Description" SG_ 1959 GST_SWRC_Byte3 "TP Index : 175";
BA_ "UsrSigPurpose" SG_ 1959 GST_SWRC_Byte3 3;
BA_ "UserSigValidity" SG_ 1959 GST_SWRC_Byte3 0;
BA_REL_ "GenSigTimeoutTime" BU_SG_REL_ SWRC SG_ 1959 GST_SWRC_Byte3 0;
BA_ "NetworkRequest" SG_ 1959 GST_SWRC_Byte3 0;
BA_ "NetworkRequestHoldingTime" SG_ 1959 GST_SWRC_Byte3 5000;
BA_ "Version" SG_ 1959 GST_SWRC_Byte3 "21.02.04";
BA_ "Description" SG_ 1959 GST_SWRC_Byte4 "TP Index : 175";
BA_ "UsrSigPurpose" SG_ 1959 GST_SWRC_Byte4 3;
BA_ "UserSigValidity" SG_ 1959 GST_SWRC_Byte4 0;
BA_REL_ "GenSigTimeoutTime" BU_SG_REL_ SWRC SG_ 1959 GST_SWRC_Byte4 0;
BA_ "NetworkRequest" SG_ 1959 GST_SWRC_Byte4 0;
BA_ "NetworkRequestHoldingTime" SG_ 1959 GST_SWRC_Byte4 5000;
BA_ "Version" SG_ 1959 GST_SWRC_Byte4 "21.02.04";
BA_ "Description" SG_ 1959 GST_SWRC_Byte5 "TP Index : 175";
BA_ "UsrSigPurpose" SG_ 1959 GST_SWRC_Byte5 3;
BA_ "UserSigValidity" SG_ 1959 GST_SWRC_Byte5 0;
BA_REL_ "GenSigTimeoutTime" BU_SG_REL_ SWRC SG_ 1959 GST_SWRC_Byte5 0;
BA_ "NetworkRequest" SG_ 1959 GST_SWRC_Byte5 0;
BA_ "NetworkRequestHoldingTime" SG_ 1959 GST_SWRC_Byte5 5000;
BA_ "Version" SG_ 1959 GST_SWRC_Byte5 "21.02.04";
BA_ "Description" SG_ 1959 GST_SWRC_Byte6 "TP Index : 175";
BA_ "UsrSigPurpose" SG_ 1959 GST_SWRC_Byte6 3;
BA_ "UserSigValidity" SG_ 1959 GST_SWRC_Byte6 0;
BA_REL_ "GenSigTimeoutTime" BU_SG_REL_ SWRC SG_ 1959 GST_SWRC_Byte6 0;
BA_ "NetworkRequest" SG_ 1959 GST_SWRC_Byte6 0;
BA_ "NetworkRequestHoldingTime" SG_ 1959 GST_SWRC_Byte6 5000;
BA_ "Version" SG_ 1959 GST_SWRC_Byte6 "21.02.04";
BA_ "Description" SG_ 1959 GST_SWRC_Byte7 "TP Index : 175";
BA_ "UsrSigPurpose" SG_ 1959 GST_SWRC_Byte7 3;
BA_ "UserSigValidity" SG_ 1959 GST_SWRC_Byte7 0;
BA_REL_ "GenSigTimeoutTime" BU_SG_REL_ SWRC SG_ 1959 GST_SWRC_Byte7 0;
BA_ "NetworkRequest" SG_ 1959 GST_SWRC_Byte7 0;
BA_ "NetworkRequestHoldingTime" SG_ 1959 GST_SWRC_Byte7 5000;
BA_ "Version" SG_ 1959 GST_SWRC_Byte7 "21.02.04";
BA_ "Description" SG_ 1959 GST_SWRC_Byte1 "TP Index : 175";
BA_ "UsrSigPurpose" SG_ 1959 GST_SWRC_Byte1 3;
BA_ "UserSigValidity" SG_ 1959 GST_SWRC_Byte1 0;
BA_REL_ "GenSigTimeoutTime" BU_SG_REL_ SWRC SG_ 1959 GST_SWRC_Byte1 0;
BA_ "NetworkRequest" SG_ 1959 GST_SWRC_Byte1 0;
BA_ "NetworkRequestHoldingTime" SG_ 1959 GST_SWRC_Byte1 5000;
BA_ "Version" SG_ 1959 GST_SWRC_Byte1 "21.02.04";
BA_ "GenMsgSendType" BO_ 1015 0;
BA_ "GenMsgCycleTime" BO_ 1015 1000;
BA_ "GenMsgCycleTimeFast" BO_ 1015 0;
BA_ "GenMsgNrOfRepetition" BO_ 1015 0;
BA_ "Description" SG_ 1015 HU_MM_Altitude "MSL

range = -40000 <= Value <= 1000000

unit = cm";
BA_ "UserSigValidity" SG_ 1015 HU_MM_Altitude 1;
BA_REL_ "GenSigTimeoutTime" BU_SG_REL_ BLTN_CAM SG_ 1015 HU_MM_Altitude 5000;
BA_ "Version" SG_ 1015 HU_MM_Altitude "21.08.01";
BA_ "Description" SG_ 1015 HU_MM_Heading "range = 0<=Valud <360";
BA_ "UserSigValidity" SG_ 1015 HU_MM_Heading 1;
BA_REL_ "GenSigTimeoutTime" BU_SG_REL_ BLTN_CAM SG_ 1015 HU_MM_Heading 5000;
BA_ "Version" SG_ 1015 HU_MM_Heading "21.08.01";
BA_ "GenMsgSendType" BO_ 1016 0;
BA_ "GenMsgCycleTime" BO_ 1016 1000;
BA_ "GenMsgCycleTimeFast" BO_ 1016 0;
BA_ "GenMsgNrOfRepetition" BO_ 1016 0;
BA_ "GenSigStartValue" SG_ 1016 GNSS_MM_type 15;
BA_ "UserSigValidity" SG_ 1016 GNSS_MM_type 1;
BA_REL_ "GenSigTimeoutTime" BU_SG_REL_ BLTN_CAM SG_ 1016 GNSS_MM_type 5000;
BA_ "Version" SG_ 1016 GNSS_MM_type "21.08.01";
BA_ "GenMsgCycleTime" BO_ 1019 0;
BA_ "Description" SG_ 1019 HU_MoodTherapyDrSeat "Moodtherapy Driver Seat On/Off";
BA_ "GenSigSendType" SG_ 1019 HU_MoodTherapyDrSeat 4;
BA_ "UserSigValidity" SG_ 1019 HU_MoodTherapyDrSeat 3;
BA_REL_ "GenSigTimeoutTime" BU_SG_REL_ DSAU SG_ 1019 HU_MoodTherapyDrSeat 0;
BA_ "RoutingFactor" SG_ 1019 HU_MoodTherapyDrSeat 0;
BA_ "Version" SG_ 1019 HU_MoodTherapyDrSeat "20.07.13";
BA_ "Description" SG_ 1019 HU_VitalityFragrance "Vitality Fragrance On/Off";
BA_ "GenSigSendType" SG_ 1019 HU_VitalityFragrance 4;
BA_ "UserSigValidity" SG_ 1019 HU_VitalityFragrance 3;
BA_ "RoutingFactor" SG_ 1019 HU_VitalityFragrance 0;
BA_ "Version" SG_ 1019 HU_VitalityFragrance "20.07.13";
BA_ "Description" SG_ 1019 HU_VitalityCurtain "Vitality Curtain On/Off";
BA_ "GenSigSendType" SG_ 1019 HU_VitalityCurtain 4;
BA_ "UserSigValidity" SG_ 1019 HU_VitalityCurtain 3;
BA_ "RoutingFactor" SG_ 1019 HU_VitalityCurtain 0;
BA_ "Version" SG_ 1019 HU_VitalityCurtain "20.07.13";
BA_ "Description" SG_ 1019 HU_DelightMoodLamp "Delight MoodLamp On/Off";
BA_ "GenSigSendType" SG_ 1019 HU_DelightMoodLamp 4;
BA_ "UserSigValidity" SG_ 1019 HU_DelightMoodLamp 3;
BA_ "RoutingFactor" SG_ 1019 HU_DelightMoodLamp 0;
BA_ "Version" SG_ 1019 HU_DelightMoodLamp "20.07.13";
BA_ "Description" SG_ 1019 HU_DelightFragrance "Delight Fragrance On/Off";
BA_ "GenSigSendType" SG_ 1019 HU_DelightFragrance 4;
BA_ "UserSigValidity" SG_ 1019 HU_DelightFragrance 3;
BA_ "RoutingFactor" SG_ 1019 HU_DelightFragrance 0;
BA_ "Version" SG_ 1019 HU_DelightFragrance "20.07.13";
BA_ "Description" SG_ 1019 HU_DelightCurtain "Delight Curtain On/Off";
BA_ "GenSigSendType" SG_ 1019 HU_DelightCurtain 4;
BA_ "UserSigValidity" SG_ 1019 HU_DelightCurtain 3;
BA_ "RoutingFactor" SG_ 1019 HU_DelightCurtain 0;
BA_ "Version" SG_ 1019 HU_DelightCurtain "20.07.13";
BA_ "Description" SG_ 1019 HU_MoodTherapyPsSeat "Moodtherapy Passenger Seat On/Off";
BA_ "GenSigSendType" SG_ 1019 HU_MoodTherapyPsSeat 4;
BA_ "UserSigValidity" SG_ 1019 HU_MoodTherapyPsSeat 3;
BA_REL_ "GenSigTimeoutTime" BU_SG_REL_ ASAU SG_ 1019 HU_MoodTherapyPsSeat 0;
BA_ "RoutingFactor" SG_ 1019 HU_MoodTherapyPsSeat 0;
BA_ "Version" SG_ 1019 HU_MoodTherapyPsSeat "20.07.13";
BA_ "Description" SG_ 1019 HU_CareMoodLamp "Care MoodLamp On/Off";
BA_ "GenSigSendType" SG_ 1019 HU_CareMoodLamp 4;
BA_ "UserSigValidity" SG_ 1019 HU_CareMoodLamp 3;
BA_ "RoutingFactor" SG_ 1019 HU_CareMoodLamp 0;
BA_ "Version" SG_ 1019 HU_CareMoodLamp "20.07.13";
BA_ "Description" SG_ 1019 HU_CareFragrance "Care Fragrance On/Off";
BA_ "GenSigSendType" SG_ 1019 HU_CareFragrance 4;
BA_ "UserSigValidity" SG_ 1019 HU_CareFragrance 3;
BA_ "RoutingFactor" SG_ 1019 HU_CareFragrance 0;
BA_ "Version" SG_ 1019 HU_CareFragrance "20.07.13";
BA_ "Description" SG_ 1019 HU_CareMassage "Care Massage On/Off";
BA_ "GenSigSendType" SG_ 1019 HU_CareMassage 4;
BA_ "UserSigValidity" SG_ 1019 HU_CareMassage 3;
BA_REL_ "GenSigTimeoutTime" BU_SG_REL_ DSAU SG_ 1019 HU_CareMassage 0;
BA_REL_ "GenSigTimeoutTime" BU_SG_REL_ ASAU SG_ 1019 HU_CareMassage 0;
BA_ "RoutingFactor" SG_ 1019 HU_CareMassage 0;
BA_ "Version" SG_ 1019 HU_CareMassage "20.07.13";
BA_ "Description" SG_ 1019 HU_CareCurtain "Care Curtain On/Off";
BA_ "GenSigSendType" SG_ 1019 HU_CareCurtain 4;
BA_ "UserSigValidity" SG_ 1019 HU_CareCurtain 3;
BA_ "RoutingFactor" SG_ 1019 HU_CareCurtain 0;
BA_ "Version" SG_ 1019 HU_CareCurtain "20.07.13";
BA_ "Description" SG_ 1019 HU_ComfortMoodLamp "Comfort MoodLamp On/Off";
BA_ "GenSigSendType" SG_ 1019 HU_ComfortMoodLamp 4;
BA_ "UserSigValidity" SG_ 1019 HU_ComfortMoodLamp 3;
BA_ "RoutingFactor" SG_ 1019 HU_ComfortMoodLamp 0;
BA_ "Version" SG_ 1019 HU_ComfortMoodLamp "20.07.13";
BA_ "Description" SG_ 1019 HU_ComfortFragrance "Comfort Fragrance On/Off";
BA_ "GenSigSendType" SG_ 1019 HU_ComfortFragrance 4;
BA_ "UserSigValidity" SG_ 1019 HU_ComfortFragrance 3;
BA_ "RoutingFactor" SG_ 1019 HU_ComfortFragrance 0;
BA_ "Version" SG_ 1019 HU_ComfortFragrance "20.07.13";
BA_ "Description" SG_ 1019 HU_ComfortMassage "Comfort Massage On/Off";
BA_ "GenSigSendType" SG_ 1019 HU_ComfortMassage 4;
BA_ "UserSigValidity" SG_ 1019 HU_ComfortMassage 3;
BA_REL_ "GenSigTimeoutTime" BU_SG_REL_ DSAU SG_ 1019 HU_ComfortMassage 0;
BA_REL_ "GenSigTimeoutTime" BU_SG_REL_ ASAU SG_ 1019 HU_ComfortMassage 0;
BA_ "RoutingFactor" SG_ 1019 HU_ComfortMassage 0;
BA_ "Version" SG_ 1019 HU_ComfortMassage "20.07.13";
BA_ "Description" SG_ 1019 HU_ComfortCurtain "Comfort Curtain On/Off";
BA_ "GenSigSendType" SG_ 1019 HU_ComfortCurtain 4;
BA_ "UserSigValidity" SG_ 1019 HU_ComfortCurtain 3;
BA_ "RoutingFactor" SG_ 1019 HU_ComfortCurtain 0;
BA_ "Version" SG_ 1019 HU_ComfortCurtain "20.07.13";
BA_ "Description" SG_ 1019 HU_MoodTherapyMode "Moodtherapy Mode Change Signal";
BA_ "GenSigSendType" SG_ 1019 HU_MoodTherapyMode 4;
BA_ "UserSigValidity" SG_ 1019 HU_MoodTherapyMode 3;
BA_REL_ "GenSigTimeoutTime" BU_SG_REL_ DSAU SG_ 1019 HU_MoodTherapyMode 0;
BA_REL_ "GenSigTimeoutTime" BU_SG_REL_ ASAU SG_ 1019 HU_MoodTherapyMode 0;
BA_ "RoutingFactor" SG_ 1019 HU_MoodTherapyMode 0;
BA_ "Version" SG_ 1019 HU_MoodTherapyMode "20.07.13";
BA_ "Description" SG_ 1019 HU_MoodTherapyRlSeat "Moodtherapy RearLeft Seat On/Off";
BA_ "GenSigSendType" SG_ 1019 HU_MoodTherapyRlSeat 4;
BA_ "UserSigValidity" SG_ 1019 HU_MoodTherapyRlSeat 3;
BA_ "RoutingFactor" SG_ 1019 HU_MoodTherapyRlSeat 0;
BA_ "Version" SG_ 1019 HU_MoodTherapyRlSeat "20.07.13";
BA_ "Description" SG_ 1019 HU_MoodTherapyRrSeat "Moodtherapy Rear Right Seat On/Off";
BA_ "GenSigSendType" SG_ 1019 HU_MoodTherapyRrSeat 4;
BA_ "UserSigValidity" SG_ 1019 HU_MoodTherapyRrSeat 3;
BA_ "RoutingFactor" SG_ 1019 HU_MoodTherapyRrSeat 0;
BA_ "Version" SG_ 1019 HU_MoodTherapyRrSeat "20.07.13";
BA_ "Description" SG_ 1019 HU_VitalityMoodLamp "Vitality MoodLamp On/Off";
BA_ "GenSigSendType" SG_ 1019 HU_VitalityMoodLamp 4;
BA_ "UserSigValidity" SG_ 1019 HU_VitalityMoodLamp 3;
BA_ "RoutingFactor" SG_ 1019 HU_VitalityMoodLamp 0;
BA_ "Version" SG_ 1019 HU_VitalityMoodLamp "20.07.13";
BA_ "GenMsgSendType" BO_ 2382595329 0;
BA_ "GenMsgCycleTimeFast" BO_ 2382595329 0;
BA_ "GenMsgNrOfRepetition" BO_ 2382595329 0;
BA_ "VFrameFormat" BO_ 2382595329 1;
BA_ "Description" SG_ 2382595329 ICSC_Crc3Val "The data area for CRC calculation is based on the data length (DLC) of the message DB.

The CRC shall be calculated over the entire data block (excluding the CRC bytes) including the user data, alive counter and Data ID

 

- CRC Polynomial (0x1021) , Initial Value : 0xFFFF, XOR value : 0x0000, Data ID : Message ID + 0xF800 

- The initial value is for CRC calculation and the message should be sent with the calculated result value. 

- The mathematical expression to 16 bit CRC polynomial is given here. G(x) = x16 + x12 + x5 + 1";
BA_ "GenSigStartValue" SG_ 2382595329 ICSC_Crc3Val 65535;
BA_ "UserSigValidity" SG_ 2382595329 ICSC_Crc3Val 3;
BA_ "RoutingFactor" SG_ 2382595329 ICSC_Crc3Val 2;
BA_ "Version" SG_ 2382595329 ICSC_Crc3Val "18.11.08";
BA_ "Description" SG_ 2382595329 ICSC_AlvCnt3Val "For the first transmission request for a data element the counter shall be initialized with 0 and shall be incremented by 1 for every subsequent send request. 

When the counter reaches the maximum value(0xFF), then it shall restart with 0 for the next send request";
BA_ "UserSigValidity" SG_ 2382595329 ICSC_AlvCnt3Val 3;
BA_ "RoutingFactor" SG_ 2382595329 ICSC_AlvCnt3Val 2;
BA_ "Version" SG_ 2382595329 ICSC_AlvCnt3Val "18.11.08";
BA_ "Description" SG_ 2382595329 DMIC_OffRdMod "This signal indicates that which offroad mode vehicle drives.";
BA_ "UserSigValidity" SG_ 2382595329 DMIC_OffRdMod 3;
BA_ "RoutingFactor" SG_ 2382595329 DMIC_OffRdMod 2;
BA_ "Version" SG_ 2382595329 DMIC_OffRdMod "18.03.04";
BA_ "Description" SG_ 2382595329 DMIC_OffRdModActvSta "Information about offroad";
BA_ "UserSigValidity" SG_ 2382595329 DMIC_OffRdModActvSta 3;
BA_REL_ "GenSigTimeoutTime" BU_SG_REL_ RCS SG_ 2382595329 DMIC_OffRdModActvSta 1500;
BA_ "RoutingFactor" SG_ 2382595329 DMIC_OffRdModActvSta 2;
BA_ "Version" SG_ 2382595329 DMIC_OffRdModActvSta "18.03.04";
BA_ "Description" SG_ 2382595329 DMIC_OffRdModSta "Information about offroad mode change";
BA_ "UserSigValidity" SG_ 2382595329 DMIC_OffRdModSta 3;
BA_ "RoutingFactor" SG_ 2382595329 DMIC_OffRdModSta 2;
BA_ "Version" SG_ 2382595329 DMIC_OffRdModSta "18.03.04";
BA_ "Description" SG_ 2382595329 ESC_LongGrdntPerc "This signal indicates longitudinal gradient in % unit.";
BA_ "UserSigValidity" SG_ 2382595329 ESC_LongGrdntPerc 3;
BA_REL_ "GenSigTimeoutTime" BU_SG_REL_ EMCU SG_ 2382595329 ESC_LongGrdntPerc 1500;
BA_ "RoutingFactor" SG_ 2382595329 ESC_LongGrdntPerc 2;
BA_ "Version" SG_ 2382595329 ESC_LongGrdntPerc "18.11.02";
BA_ "Description" SG_ 2382595329 ESC_LatGrdntPerc "This signal indicates lateral gradient in % unit.";
BA_ "UserSigValidity" SG_ 2382595329 ESC_LatGrdntPerc 3;
BA_REL_ "GenSigTimeoutTime" BU_SG_REL_ EMCU SG_ 2382595329 ESC_LatGrdntPerc 1500;
BA_ "RoutingFactor" SG_ 2382595329 ESC_LatGrdntPerc 2;
BA_ "Version" SG_ 2382595329 ESC_LatGrdntPerc "18.11.02";
BA_ "Description" SG_ 2382595329 OFFROAD_AppliedSta "This signal indicates whether the each offroad mode is applied or not.

For each bit value, 0x0 means 'Not Applied'. And 0x1 means 'Applied'.

 - Bit 0 : Snow

 - Bit 1 : Mud

 - Bit 2 : Sand

 - Bit 3 : Auto

 - Bit 4 : Deep Snow

 - Bit 5 : Reserved

 - Bit 6 : Reserved

 - Bit 7 : Reserved";
BA_ "UserSigValidity" SG_ 2382595329 OFFROAD_AppliedSta 3;
BA_ "RoutingFactor" SG_ 2382595329 OFFROAD_AppliedSta 2;
BA_ "Version" SG_ 2382595329 OFFROAD_AppliedSta "20.09.00";
BA_ "Description" SG_ 2382595329 OFFROAD_TypeSta "This signal indicates the type of offroad mode function.

For each bit value, 0x0 means 'Not Applied'. And 0x1 means 'Applied'.

 - Bit 0 : Terrain Mode

 - Bit 1 : Traction Control";
BA_ "UserSigValidity" SG_ 2382595329 OFFROAD_TypeSta 3;
BA_ "RoutingFactor" SG_ 2382595329 OFFROAD_TypeSta 2;
BA_ "Version" SG_ 2382595329 OFFROAD_TypeSta "20.09.00";
BA_ "GenMsgCycleTime" BO_ 1434 0;
BA_ "GenMsgCycleTimeFast" BO_ 1434 0;
BA_ "GenMsgNrOfRepetition" BO_ 1434 0;
BA_ "DiagResponse" BO_ 1434 1;
BA_ "GenMsgILSupport" BO_ 1434 0;
BA_ "TpMessage" BO_ 1434 1;
BA_ "TpTxIndex" BO_ 1434 55;
BA_ "Description" SG_ 1434 RCM_GST_Byte0 "TP Index : 55";
BA_ "UsrSigPurpose" SG_ 1434 RCM_GST_Byte0 4;
BA_ "UserSigValidity" SG_ 1434 RCM_GST_Byte0 0;
BA_REL_ "GenSigTimeoutTime" BU_SG_REL_ CGW_CCU SG_ 1434 RCM_GST_Byte0 0;
BA_ "NetworkRequestHoldingTime" SG_ 1434 RCM_GST_Byte0 5000;
BA_ "Version" SG_ 1434 RCM_GST_Byte0 "20.11.01";
BA_ "Description" SG_ 1434 RCM_GST_Byte2 "TP Index : 55";
BA_ "UsrSigPurpose" SG_ 1434 RCM_GST_Byte2 4;
BA_ "UserSigValidity" SG_ 1434 RCM_GST_Byte2 0;
BA_REL_ "GenSigTimeoutTime" BU_SG_REL_ CGW_CCU SG_ 1434 RCM_GST_Byte2 0;
BA_ "NetworkRequestHoldingTime" SG_ 1434 RCM_GST_Byte2 5000;
BA_ "Version" SG_ 1434 RCM_GST_Byte2 "20.11.01";
BA_ "Description" SG_ 1434 RCM_GST_Byte3 "TP Index : 55";
BA_ "UsrSigPurpose" SG_ 1434 RCM_GST_Byte3 4;
BA_ "UserSigValidity" SG_ 1434 RCM_GST_Byte3 0;
BA_REL_ "GenSigTimeoutTime" BU_SG_REL_ CGW_CCU SG_ 1434 RCM_GST_Byte3 0;
BA_ "NetworkRequestHoldingTime" SG_ 1434 RCM_GST_Byte3 5000;
BA_ "Version" SG_ 1434 RCM_GST_Byte3 "20.11.01";
BA_ "Description" SG_ 1434 RCM_GST_Byte4 "TP Index : 55";
BA_ "UsrSigPurpose" SG_ 1434 RCM_GST_Byte4 4;
BA_ "UserSigValidity" SG_ 1434 RCM_GST_Byte4 0;
BA_REL_ "GenSigTimeoutTime" BU_SG_REL_ CGW_CCU SG_ 1434 RCM_GST_Byte4 0;
BA_ "NetworkRequestHoldingTime" SG_ 1434 RCM_GST_Byte4 5000;
BA_ "Version" SG_ 1434 RCM_GST_Byte4 "20.11.01";
BA_ "Description" SG_ 1434 RCM_GST_Byte5 "TP Index : 55";
BA_ "UsrSigPurpose" SG_ 1434 RCM_GST_Byte5 4;
BA_ "UserSigValidity" SG_ 1434 RCM_GST_Byte5 0;
BA_REL_ "GenSigTimeoutTime" BU_SG_REL_ CGW_CCU SG_ 1434 RCM_GST_Byte5 0;
BA_ "NetworkRequestHoldingTime" SG_ 1434 RCM_GST_Byte5 5000;
BA_ "Version" SG_ 1434 RCM_GST_Byte5 "20.11.01";
BA_ "Description" SG_ 1434 RCM_GST_Byte6 "TP Index : 55";
BA_ "UsrSigPurpose" SG_ 1434 RCM_GST_Byte6 4;
BA_ "UserSigValidity" SG_ 1434 RCM_GST_Byte6 0;
BA_REL_ "GenSigTimeoutTime" BU_SG_REL_ CGW_CCU SG_ 1434 RCM_GST_Byte6 0;
BA_ "NetworkRequestHoldingTime" SG_ 1434 RCM_GST_Byte6 5000;
BA_ "Version" SG_ 1434 RCM_GST_Byte6 "20.11.01";
BA_ "Description" SG_ 1434 RCM_GST_Byte7 "TP Index : 55";
BA_ "UsrSigPurpose" SG_ 1434 RCM_GST_Byte7 4;
BA_ "UserSigValidity" SG_ 1434 RCM_GST_Byte7 0;
BA_REL_ "GenSigTimeoutTime" BU_SG_REL_ CGW_CCU SG_ 1434 RCM_GST_Byte7 0;
BA_ "NetworkRequestHoldingTime" SG_ 1434 RCM_GST_Byte7 5000;
BA_ "Version" SG_ 1434 RCM_GST_Byte7 "20.11.01";
BA_ "Description" SG_ 1434 RCM_GST_Byte1 "TP Index : 55";
BA_ "UsrSigPurpose" SG_ 1434 RCM_GST_Byte1 4;
BA_ "UserSigValidity" SG_ 1434 RCM_GST_Byte1 0;
BA_REL_ "GenSigTimeoutTime" BU_SG_REL_ CGW_CCU SG_ 1434 RCM_GST_Byte1 0;
BA_ "NetworkRequestHoldingTime" SG_ 1434 RCM_GST_Byte1 5000;
BA_ "Version" SG_ 1434 RCM_GST_Byte1 "20.11.01";
BA_ "GenMsgSendType" BO_ 1004 0;
BA_ "Description" SG_ 1004 CF_RCS_SwTyp "Road Control Switch Type";
BA_ "GenSigSendType" SG_ 1004 CF_RCS_SwTyp 4;
BA_ "UserSigValidity" SG_ 1004 CF_RCS_SwTyp 0;
BA_REL_ "GenSigTimeoutTime" BU_SG_REL_ CGW_CCU SG_ 1004 CF_RCS_SwTyp 1500;
BA_ "RoutingFactor" SG_ 1004 CF_RCS_SwTyp 0;
BA_ "Version" SG_ 1004 CF_RCS_SwTyp "18.10.02";
BA_ "Description" SG_ 1004 CF_RCS_OffRoad "RCS OffRoad mode status";
BA_ "GenSigSendType" SG_ 1004 CF_RCS_OffRoad 4;
BA_ "UserSigValidity" SG_ 1004 CF_RCS_OffRoad 3;
BA_REL_ "GenSigTimeoutTime" BU_SG_REL_ CGW_CCU SG_ 1004 CF_RCS_OffRoad 1500;
BA_ "RoutingFactor" SG_ 1004 CF_RCS_OffRoad 0;
BA_ "Version" SG_ 1004 CF_RCS_OffRoad "20.01.01";
BA_ "Description" SG_ 1004 CF_RCS_BtnSta "RCS Button Status";
BA_ "GenSigSendType" SG_ 1004 CF_RCS_BtnSta 4;
BA_ "UserSigValidity" SG_ 1004 CF_RCS_BtnSta 3;
BA_REL_ "GenSigTimeoutTime" BU_SG_REL_ CGW_CCU SG_ 1004 CF_RCS_BtnSta 1500;
BA_ "RoutingFactor" SG_ 1004 CF_RCS_BtnSta 0;
BA_ "Version" SG_ 1004 CF_RCS_BtnSta "18.10.02";
BA_ "Description" SG_ 1004 CF_RCS_RotateEnd "signal to inform end of rotate";
BA_ "GenSigSendType" SG_ 1004 CF_RCS_RotateEnd 4;
BA_ "UserSigValidity" SG_ 1004 CF_RCS_RotateEnd 3;
BA_REL_ "GenSigTimeoutTime" BU_SG_REL_ CGW_CCU SG_ 1004 CF_RCS_RotateEnd 1500;
BA_ "RoutingFactor" SG_ 1004 CF_RCS_RotateEnd 0;
BA_ "Version" SG_ 1004 CF_RCS_RotateEnd "18.10.02";
BA_ "Description" SG_ 1004 CF_RCS_4wdLocking "4wd locking on/off signal";
BA_ "GenSigSendType" SG_ 1004 CF_RCS_4wdLocking 4;
BA_ "UserSigValidity" SG_ 1004 CF_RCS_4wdLocking 3;
BA_REL_ "GenSigTimeoutTime" BU_SG_REL_ CGW_CCU SG_ 1004 CF_RCS_4wdLocking 1500;
BA_ "RoutingFactor" SG_ 1004 CF_RCS_4wdLocking 0;
BA_ "Version" SG_ 1004 CF_RCS_4wdLocking "18.10.02";
BA_ "Description" SG_ 1004 CF_RCS_DrvMod "RCS drive mode select status";
BA_ "GenSigSendType" SG_ 1004 CF_RCS_DrvMod 4;
BA_ "UserSigValidity" SG_ 1004 CF_RCS_DrvMod 3;
BA_REL_ "GenSigTimeoutTime" BU_SG_REL_ CGW_CCU SG_ 1004 CF_RCS_DrvMod 1500;
BA_ "RoutingFactor" SG_ 1004 CF_RCS_DrvMod 0;
BA_ "Version" SG_ 1004 CF_RCS_DrvMod "18.10.02";
BA_ "GenMsgCycleTime" BO_ 1423 0;
BA_ "GenMsgCycleTimeFast" BO_ 1423 0;
BA_ "GenMsgNrOfRepetition" BO_ 1423 0;
BA_ "DiagResponse" BO_ 1423 1;
BA_ "GenMsgILSupport" BO_ 1423 0;
BA_ "TpMessage" BO_ 1423 1;
BA_ "TpTxIndex" BO_ 1423 226;
BA_ "Description" SG_ 1423 RCS_GST_Byte0 "TP Index : 226";
BA_ "UsrSigPurpose" SG_ 1423 RCS_GST_Byte0 4;
BA_ "UserSigValidity" SG_ 1423 RCS_GST_Byte0 0;
BA_REL_ "GenSigTimeoutTime" BU_SG_REL_ CGW_CCU SG_ 1423 RCS_GST_Byte0 0;
BA_ "NetworkRequest" SG_ 1423 RCS_GST_Byte0 0;
BA_ "NetworkRequestHoldingTime" SG_ 1423 RCS_GST_Byte0 5000;
BA_ "Version" SG_ 1423 RCS_GST_Byte0 "21.03.11";
BA_ "Description" SG_ 1423 RCS_GST_Byte2 "TP Index : 226";
BA_ "UsrSigPurpose" SG_ 1423 RCS_GST_Byte2 4;
BA_ "UserSigValidity" SG_ 1423 RCS_GST_Byte2 0;
BA_REL_ "GenSigTimeoutTime" BU_SG_REL_ CGW_CCU SG_ 1423 RCS_GST_Byte2 0;
BA_ "NetworkRequest" SG_ 1423 RCS_GST_Byte2 0;
BA_ "NetworkRequestHoldingTime" SG_ 1423 RCS_GST_Byte2 5000;
BA_ "Version" SG_ 1423 RCS_GST_Byte2 "21.03.11";
BA_ "Description" SG_ 1423 RCS_GST_Byte3 "TP Index : 226";
BA_ "UsrSigPurpose" SG_ 1423 RCS_GST_Byte3 4;
BA_ "UserSigValidity" SG_ 1423 RCS_GST_Byte3 0;
BA_REL_ "GenSigTimeoutTime" BU_SG_REL_ CGW_CCU SG_ 1423 RCS_GST_Byte3 0;
BA_ "NetworkRequest" SG_ 1423 RCS_GST_Byte3 0;
BA_ "NetworkRequestHoldingTime" SG_ 1423 RCS_GST_Byte3 5000;
BA_ "Version" SG_ 1423 RCS_GST_Byte3 "21.03.11";
BA_ "Description" SG_ 1423 RCS_GST_Byte4 "TP Index : 226";
BA_ "UsrSigPurpose" SG_ 1423 RCS_GST_Byte4 4;
BA_ "UserSigValidity" SG_ 1423 RCS_GST_Byte4 0;
BA_REL_ "GenSigTimeoutTime" BU_SG_REL_ CGW_CCU SG_ 1423 RCS_GST_Byte4 0;
BA_ "NetworkRequest" SG_ 1423 RCS_GST_Byte4 0;
BA_ "NetworkRequestHoldingTime" SG_ 1423 RCS_GST_Byte4 5000;
BA_ "Version" SG_ 1423 RCS_GST_Byte4 "21.03.11";
BA_ "Description" SG_ 1423 RCS_GST_Byte5 "TP Index : 226";
BA_ "UsrSigPurpose" SG_ 1423 RCS_GST_Byte5 4;
BA_ "UserSigValidity" SG_ 1423 RCS_GST_Byte5 0;
BA_REL_ "GenSigTimeoutTime" BU_SG_REL_ CGW_CCU SG_ 1423 RCS_GST_Byte5 0;
BA_ "NetworkRequest" SG_ 1423 RCS_GST_Byte5 0;
BA_ "NetworkRequestHoldingTime" SG_ 1423 RCS_GST_Byte5 5000;
BA_ "Version" SG_ 1423 RCS_GST_Byte5 "21.03.11";
BA_ "Description" SG_ 1423 RCS_GST_Byte6 "TP Index : 226";
BA_ "UsrSigPurpose" SG_ 1423 RCS_GST_Byte6 4;
BA_ "UserSigValidity" SG_ 1423 RCS_GST_Byte6 0;
BA_REL_ "GenSigTimeoutTime" BU_SG_REL_ CGW_CCU SG_ 1423 RCS_GST_Byte6 0;
BA_ "NetworkRequest" SG_ 1423 RCS_GST_Byte6 0;
BA_ "NetworkRequestHoldingTime" SG_ 1423 RCS_GST_Byte6 5000;
BA_ "Version" SG_ 1423 RCS_GST_Byte6 "21.03.11";
BA_ "Description" SG_ 1423 RCS_GST_Byte7 "TP Index : 226";
BA_ "UsrSigPurpose" SG_ 1423 RCS_GST_Byte7 4;
BA_ "UserSigValidity" SG_ 1423 RCS_GST_Byte7 0;
BA_REL_ "GenSigTimeoutTime" BU_SG_REL_ CGW_CCU SG_ 1423 RCS_GST_Byte7 0;
BA_ "NetworkRequest" SG_ 1423 RCS_GST_Byte7 0;
BA_ "NetworkRequestHoldingTime" SG_ 1423 RCS_GST_Byte7 5000;
BA_ "Version" SG_ 1423 RCS_GST_Byte7 "21.03.11";
BA_ "Description" SG_ 1423 RCS_GST_Byte1 "TP Index : 226";
BA_ "UsrSigPurpose" SG_ 1423 RCS_GST_Byte1 4;
BA_ "UserSigValidity" SG_ 1423 RCS_GST_Byte1 0;
BA_REL_ "GenSigTimeoutTime" BU_SG_REL_ CGW_CCU SG_ 1423 RCS_GST_Byte1 0;
BA_ "NetworkRequest" SG_ 1423 RCS_GST_Byte1 0;
BA_ "NetworkRequestHoldingTime" SG_ 1423 RCS_GST_Byte1 5000;
BA_ "Version" SG_ 1423 RCS_GST_Byte1 "21.03.11";
BA_ "GenMsgSendType" BO_ 1003 0;
BA_ "Description" SG_ 1003 PSM_BzrOnRLReq "PSM buzzer on command";
BA_ "GenSigSendType" SG_ 1003 PSM_BzrOnRLReq 4;
BA_ "UserSigValidity" SG_ 1003 PSM_BzrOnRLReq 0;
BA_REL_ "GenSigTimeoutTime" BU_SG_REL_ ATS SG_ 1003 PSM_BzrOnRLReq 1500;
BA_REL_ "GenSigTimeoutTime" BU_SG_REL_ DPSU SG_ 1003 PSM_BzrOnRLReq 1500;
BA_REL_ "GenSigTimeoutTime" BU_SG_REL_ DPSU SG_ 1003 PSM_BzrOnRLReq 1500;
BA_ "NetworkRequest" SG_ 1003 PSM_BzrOnRLReq 0;
BA_ "NetworkRequestHoldingTime" SG_ 1003 PSM_BzrOnRLReq 5000;
BA_ "Version" SG_ 1003 PSM_BzrOnRLReq "17.11.00";
BA_ "Description" SG_ 1003 RLPSM_RearModeState "Rear Seat State for One Touch Mode";
BA_ "GenSigSendType" SG_ 1003 RLPSM_RearModeState 4;
BA_ "UserSigValidity" SG_ 1003 RLPSM_RearModeState 0;
BA_REL_ "GenSigTimeoutTime" BU_SG_REL_ ATS SG_ 1003 RLPSM_RearModeState 1500;
BA_REL_ "GenSigTimeoutTime" BU_SG_REL_ OHCL SG_ 1003 RLPSM_RearModeState 1500;
BA_REL_ "GenSigTimeoutTime" BU_SG_REL_ CGW_CCU SG_ 1003 RLPSM_RearModeState 1500;
BA_REL_ "GenSigTimeoutTime" BU_SG_REL_ CGW_CCU SG_ 1003 RLPSM_RearModeState 1500;
BA_ "NetworkRequest" SG_ 1003 RLPSM_RearModeState 0;
BA_ "NetworkRequestHoldingTime" SG_ 1003 RLPSM_RearModeState 5000;
BA_ "Version" SG_ 1003 RLPSM_RearModeState "21.07.05";
BA_ "Description" SG_ 1003 RLPSM_RrLfSldStrtSta "This signal indicates the start/finish of rear right slide motor.";
BA_ "GenSigSendType" SG_ 1003 RLPSM_RrLfSldStrtSta 4;
BA_ "UserSigValidity" SG_ 1003 RLPSM_RrLfSldStrtSta 0;
BA_ "NetworkRequest" SG_ 1003 RLPSM_RrLfSldStrtSta 0;
BA_ "NetworkRequestHoldingTime" SG_ 1003 RLPSM_RrLfSldStrtSta 5000;
BA_ "Version" SG_ 1003 RLPSM_RrLfSldStrtSta "19.08.08";
BA_ "Description" SG_ 1003 RLPSM_OptTyp "The signal indicates the option type of Rear Left's Power Seat Module.";
BA_ "GenSigSendType" SG_ 1003 RLPSM_OptTyp 4;
BA_ "UserSigValidity" SG_ 1003 RLPSM_OptTyp 0;
BA_ "Version" SG_ 1003 RLPSM_OptTyp "19.10.02";
BA_ "GenSigSendType" SG_ 1003 RLPSM_RLStEsyAcsUSMSta 4;
BA_ "UserSigValidity" SG_ 1003 RLPSM_RLStEsyAcsUSMSta 0;
BA_REL_ "GenSigTimeoutTime" BU_SG_REL_ ATS SG_ 1003 RLPSM_RLStEsyAcsUSMSta 1500;
BA_REL_ "GenSigTimeoutTime" BU_SG_REL_ CGW_CCU SG_ 1003 RLPSM_RLStEsyAcsUSMSta 1500;
BA_REL_ "GenSigTimeoutTime" BU_SG_REL_ CGW_CCU SG_ 1003 RLPSM_RLStEsyAcsUSMSta 1500;
BA_ "Version" SG_ 1003 RLPSM_RLStEsyAcsUSMSta "19.10.07";
BA_ "Description" SG_ 1003 RLPSM_FnshSta "RLPSM finish state";
BA_ "GenSigSendType" SG_ 1003 RLPSM_FnshSta 4;
BA_ "UserSigValidity" SG_ 1003 RLPSM_FnshSta 0;
BA_ "NetworkRequest" SG_ 1003 RLPSM_FnshSta 0;
BA_ "NetworkRequestHoldingTime" SG_ 1003 RLPSM_FnshSta 5000;
BA_ "Version" SG_ 1003 RLPSM_FnshSta "17.11.00";
BA_ "Description" SG_ 1003 RLPSM_AllSeatPosPlyBck_Sta "The signal indicates the state of All seat position playing back.";
BA_ "GenSigSendType" SG_ 1003 RLPSM_AllSeatPosPlyBck_Sta 4;
BA_ "UserSigValidity" SG_ 1003 RLPSM_AllSeatPosPlyBck_Sta 0;
BA_REL_ "GenSigTimeoutTime" BU_SG_REL_ CGW_CCU SG_ 1003 RLPSM_AllSeatPosPlyBck_Sta 1500;
BA_ "Version" SG_ 1003 RLPSM_AllSeatPosPlyBck_Sta "20.03.01";
BA_ "Description" SG_ 1003 RLPSM_RLSlidePosition "Rear Left Seat Slide Position";
BA_ "GenSigSendType" SG_ 1003 RLPSM_RLSlidePosition 4;
BA_ "UserSigValidity" SG_ 1003 RLPSM_RLSlidePosition 0;
BA_REL_ "GenSigTimeoutTime" BU_SG_REL_ RRPSU SG_ 1003 RLPSM_RLSlidePosition 1500;
BA_ "NetworkRequest" SG_ 1003 RLPSM_RLSlidePosition 0;
BA_ "NetworkRequestHoldingTime" SG_ 1003 RLPSM_RLSlidePosition 5000;
BA_ "Version" SG_ 1003 RLPSM_RLSlidePosition "20.03.01";
BA_ "Description" SG_ 1003 RLPSM_SeatPos_Sta "The signal indicates the state of   Seat Meomry State";
BA_ "GenSigSendType" SG_ 1003 RLPSM_SeatPos_Sta 4;
BA_ "UserSigValidity" SG_ 1003 RLPSM_SeatPos_Sta 0;
BA_REL_ "GenSigTimeoutTime" BU_SG_REL_ RLPSU SG_ 1003 RLPSM_SeatPos_Sta 1500;
BA_REL_ "GenSigTimeoutTime" BU_SG_REL_ RRPSU SG_ 1003 RLPSM_SeatPos_Sta 1500;
BA_ "Version" SG_ 1003 RLPSM_SeatPos_Sta "20.03.01";
BA_ "Description" SG_ 1003 RLPSM_SeatPosSldLmt_Sta "RLPSM(Rear Left) Slide end Position and limit Initialize State information";
BA_ "GenSigSendType" SG_ 1003 RLPSM_SeatPosSldLmt_Sta 4;
BA_ "UserSigValidity" SG_ 1003 RLPSM_SeatPosSldLmt_Sta 0;
BA_ "NetworkRequest" SG_ 1003 RLPSM_SeatPosSldLmt_Sta 0;
BA_ "NetworkRequestHoldingTime" SG_ 1003 RLPSM_SeatPosSldLmt_Sta 5000;
BA_ "Version" SG_ 1003 RLPSM_SeatPosSldLmt_Sta "20.03.01";
BA_ "Description" SG_ 1003 RLPSM_Enable_Sta "The signal indicates Seat Operating condition";
BA_ "GenSigSendType" SG_ 1003 RLPSM_Enable_Sta 4;
BA_ "UserSigValidity" SG_ 1003 RLPSM_Enable_Sta 0;
BA_ "Version" SG_ 1003 RLPSM_Enable_Sta "20.03.01";
BA_ "Description" SG_ 1003 RLPSM_MvSta "RLPSM move state";
BA_ "GenSigSendType" SG_ 1003 RLPSM_MvSta 4;
BA_ "UserSigValidity" SG_ 1003 RLPSM_MvSta 0;
BA_ "NetworkRequest" SG_ 1003 RLPSM_MvSta 0;
BA_ "NetworkRequestHoldingTime" SG_ 1003 RLPSM_MvSta 5000;
BA_ "Version" SG_ 1003 RLPSM_MvSta "17.11.00";
BA_ "Description" SG_ 1003 RLPSM_Mem1_Sta "RLPSM Memory State";
BA_ "GenSigSendType" SG_ 1003 RLPSM_Mem1_Sta 4;
BA_ "UserSigValidity" SG_ 1003 RLPSM_Mem1_Sta 0;
BA_ "NetworkRequest" SG_ 1003 RLPSM_Mem1_Sta 0;
BA_ "NetworkRequestHoldingTime" SG_ 1003 RLPSM_Mem1_Sta 5000;
BA_ "Version" SG_ 1003 RLPSM_Mem1_Sta "20.03.01";
BA_ "Description" SG_ 1003 RLPSM_Mem2_Sta "RLPSM Memory2 State information";
BA_ "GenSigSendType" SG_ 1003 RLPSM_Mem2_Sta 4;
BA_ "UserSigValidity" SG_ 1003 RLPSM_Mem2_Sta 0;
BA_ "NetworkRequest" SG_ 1003 RLPSM_Mem2_Sta 0;
BA_ "NetworkRequestHoldingTime" SG_ 1003 RLPSM_Mem2_Sta 5000;
BA_ "Version" SG_ 1003 RLPSM_Mem2_Sta "20.03.01";
BA_ "Description" SG_ 1003 RLPSM_Mem3_Sta "RLPSM Memory3 State information";
BA_ "GenSigSendType" SG_ 1003 RLPSM_Mem3_Sta 4;
BA_ "UserSigValidity" SG_ 1003 RLPSM_Mem3_Sta 0;
BA_ "NetworkRequest" SG_ 1003 RLPSM_Mem3_Sta 0;
BA_ "NetworkRequestHoldingTime" SG_ 1003 RLPSM_Mem3_Sta 5000;
BA_ "Version" SG_ 1003 RLPSM_Mem3_Sta "20.03.01";
BA_ "GenSigSendType" SG_ 1003 RLPSM_LimSetSta 4;
BA_ "UserSigValidity" SG_ 1003 RLPSM_LimSetSta 0;
BA_ "NetworkRequest" SG_ 1003 RLPSM_LimSetSta 0;
BA_ "NetworkRequestHoldingTime" SG_ 1003 RLPSM_LimSetSta 5000;
BA_ "Version" SG_ 1003 RLPSM_LimSetSta "21.04.01";
BA_ "Description" SG_ 1003 PSM_RrLftSldPosVal "RL SEAT SLIDE POSITION (UNIT:mm)";
BA_ "GenSigSendType" SG_ 1003 PSM_RrLftSldPosVal 4;
BA_ "UserSigValidity" SG_ 1003 PSM_RrLftSldPosVal 0;
BA_ "NetworkRequest" SG_ 1003 PSM_RrLftSldPosVal 0;
BA_ "NetworkRequestHoldingTime" SG_ 1003 PSM_RrLftSldPosVal 5000;
BA_ "Version" SG_ 1003 PSM_RrLftSldPosVal "17.11.00";
BA_ "Description" SG_ 1003 PSM_SldStrtSta "This signal indicates the start/finish of rear left slide motor.";
BA_ "GenSigSendType" SG_ 1003 PSM_SldStrtSta 4;
BA_ "UserSigValidity" SG_ 1003 PSM_SldStrtSta 0;
BA_ "NetworkRequest" SG_ 1003 PSM_SldStrtSta 0;
BA_ "NetworkRequestHoldingTime" SG_ 1003 PSM_SldStrtSta 5000;
BA_ "Version" SG_ 1003 PSM_SldStrtSta "17.11.00";
BA_ "GenMsgSendType" BO_ 1005 0;
BA_ "Description" SG_ 1005 RLPSU_FldDis "2nd Left side seat moving state  : Folding";
BA_ "GenSigSendType" SG_ 1005 RLPSU_FldDis 4;
BA_ "UserSigValidity" SG_ 1005 RLPSU_FldDis 0;
BA_REL_ "GenSigTimeoutTime" BU_SG_REL_ CGW_CCU SG_ 1005 RLPSU_FldDis 1500;
BA_ "Version" SG_ 1005 RLPSU_FldDis "18.09.01";
BA_ "Description" SG_ 1005 RLPSU_TiltDownDis "2nd Left side seat moving state  : Tilt down";
BA_ "GenSigSendType" SG_ 1005 RLPSU_TiltDownDis 4;
BA_ "UserSigValidity" SG_ 1005 RLPSU_TiltDownDis 0;
BA_REL_ "GenSigTimeoutTime" BU_SG_REL_ CGW_CCU SG_ 1005 RLPSU_TiltDownDis 1500;
BA_ "Version" SG_ 1005 RLPSU_TiltDownDis "18.09.01";
BA_ "Description" SG_ 1005 RLPSU_RclFwdDis "2nd Left side seat moving state  : Recline Forward";
BA_ "GenSigSendType" SG_ 1005 RLPSU_RclFwdDis 4;
BA_ "UserSigValidity" SG_ 1005 RLPSU_RclFwdDis 0;
BA_REL_ "GenSigTimeoutTime" BU_SG_REL_ CGW_CCU SG_ 1005 RLPSU_RclFwdDis 1500;
BA_ "Version" SG_ 1005 RLPSU_RclFwdDis "18.09.01";
BA_ "Description" SG_ 1005 RLPSU_RclBwdDis "2nd Left side seat moving state  : Recline Backward";
BA_ "GenSigSendType" SG_ 1005 RLPSU_RclBwdDis 4;
BA_ "UserSigValidity" SG_ 1005 RLPSU_RclBwdDis 0;
BA_REL_ "GenSigTimeoutTime" BU_SG_REL_ CGW_CCU SG_ 1005 RLPSU_RclBwdDis 1500;
BA_ "Version" SG_ 1005 RLPSU_RclBwdDis "18.09.01";
BA_ "Description" SG_ 1005 RLPSU_RlxModeDis "2nd Left side seat moving state  : Relax mode";
BA_ "GenSigSendType" SG_ 1005 RLPSU_RlxModeDis 4;
BA_ "UserSigValidity" SG_ 1005 RLPSU_RlxModeDis 0;
BA_ "Version" SG_ 1005 RLPSU_RlxModeDis "18.09.02";
BA_ "Description" SG_ 1005 RLPSU_Folding_SW "Interlocking signal between DPSM and RLPSU";
BA_ "GenSigSendType" SG_ 1005 RLPSU_Folding_SW 4;
BA_ "UserSigValidity" SG_ 1005 RLPSU_Folding_SW 0;
BA_ "Version" SG_ 1005 RLPSU_Folding_SW "18.09.01";
BA_ "Description" SG_ 1005 RLPSU_UnFldDis "2nd Left side seat moving state  : UnFolding";
BA_ "GenSigSendType" SG_ 1005 RLPSU_UnFldDis 4;
BA_ "UserSigValidity" SG_ 1005 RLPSU_UnFldDis 0;
BA_ "Version" SG_ 1005 RLPSU_UnFldDis "18.09.01";
BA_ "Description" SG_ 1005 RLPSU_Unfolding_SW "Interlocking signal between DPSM and RLPSU";
BA_ "GenSigSendType" SG_ 1005 RLPSU_Unfolding_SW 4;
BA_ "UserSigValidity" SG_ 1005 RLPSU_Unfolding_SW 0;
BA_ "Version" SG_ 1005 RLPSU_Unfolding_SW "18.09.01";
BA_ "Description" SG_ 1005 RLPSU_WalkIn_SW "Interlocking signal between DPSM and RLPSU";
BA_ "GenSigSendType" SG_ 1005 RLPSU_WalkIn_SW 4;
BA_ "UserSigValidity" SG_ 1005 RLPSU_WalkIn_SW 0;
BA_ "Version" SG_ 1005 RLPSU_WalkIn_SW "18.09.01";
BA_ "Description" SG_ 1005 RLPSU_UnwalkIn_SW "Interlocking signal between DPSM and RLPSU";
BA_ "GenSigSendType" SG_ 1005 RLPSU_UnwalkIn_SW 4;
BA_ "UserSigValidity" SG_ 1005 RLPSU_UnwalkIn_SW 0;
BA_ "Version" SG_ 1005 RLPSU_UnwalkIn_SW "18.09.01";
BA_ "Description" SG_ 1005 RLPSU_Folding_Postion "RLPSU Position Information";
BA_ "GenSigSendType" SG_ 1005 RLPSU_Folding_Postion 4;
BA_ "UserSigValidity" SG_ 1005 RLPSU_Folding_Postion 0;
BA_REL_ "GenSigTimeoutTime" BU_SG_REL_ CGW_CCU SG_ 1005 RLPSU_Folding_Postion 1500;
BA_ "Version" SG_ 1005 RLPSU_Folding_Postion "21.07.06";
BA_ "Description" SG_ 1005 RLPSU_Folding_State_PopUp "Rear LH seat Folding State information";
BA_ "GenSigSendType" SG_ 1005 RLPSU_Folding_State_PopUp 4;
BA_ "UserSigValidity" SG_ 1005 RLPSU_Folding_State_PopUp 0;
BA_REL_ "GenSigTimeoutTime" BU_SG_REL_ CGW_CCU SG_ 1005 RLPSU_Folding_State_PopUp 1500;
BA_ "Version" SG_ 1005 RLPSU_Folding_State_PopUp "21.07.06";
BA_ "Description" SG_ 1005 RLPSU_Relax_State_Popup "Rear LH seat Relax State information";
BA_ "GenSigSendType" SG_ 1005 RLPSU_Relax_State_Popup 4;
BA_ "UserSigValidity" SG_ 1005 RLPSU_Relax_State_Popup 0;
BA_REL_ "GenSigTimeoutTime" BU_SG_REL_ CGW_CCU SG_ 1005 RLPSU_Relax_State_Popup 1500;
BA_ "Version" SG_ 1005 RLPSU_Relax_State_Popup "21.07.06";
BA_ "Description" SG_ 1005 RLPSU_SlideFwdDis "2nd Left side seat moving state  : Slide Forward";
BA_ "GenSigSendType" SG_ 1005 RLPSU_SlideFwdDis 4;
BA_ "UserSigValidity" SG_ 1005 RLPSU_SlideFwdDis 0;
BA_REL_ "GenSigTimeoutTime" BU_SG_REL_ CGW_CCU SG_ 1005 RLPSU_SlideFwdDis 1500;
BA_ "Version" SG_ 1005 RLPSU_SlideFwdDis "19.03.05";
BA_ "Description" SG_ 1005 RLPSU_SlideBwdDis "2nd Left side seat moving state  : Slide Backward";
BA_ "GenSigSendType" SG_ 1005 RLPSU_SlideBwdDis 4;
BA_ "UserSigValidity" SG_ 1005 RLPSU_SlideBwdDis 0;
BA_REL_ "GenSigTimeoutTime" BU_SG_REL_ CGW_CCU SG_ 1005 RLPSU_SlideBwdDis 1500;
BA_ "Version" SG_ 1005 RLPSU_SlideBwdDis "19.03.05";
BA_ "Description" SG_ 1005 RLPSU_WalkInDis "2nd Left side seat moving state : Walk In";
BA_ "GenSigSendType" SG_ 1005 RLPSU_WalkInDis 4;
BA_ "UserSigValidity" SG_ 1005 RLPSU_WalkInDis 0;
BA_ "Version" SG_ 1005 RLPSU_WalkInDis "18.09.01";
BA_ "Description" SG_ 1005 RLPSU_WalkInState "2nd Left side seat Walk-in Ready state";
BA_ "GenSigSendType" SG_ 1005 RLPSU_WalkInState 4;
BA_ "UserSigValidity" SG_ 1005 RLPSU_WalkInState 0;
BA_ "Version" SG_ 1005 RLPSU_WalkInState "19.03.05";
BA_ "Description" SG_ 1005 RLPSU_UnWalkInDis "2nd Left side seat moving state : Un Walk In";
BA_ "GenSigSendType" SG_ 1005 RLPSU_UnWalkInDis 4;
BA_ "UserSigValidity" SG_ 1005 RLPSU_UnWalkInDis 0;
BA_ "Version" SG_ 1005 RLPSU_UnWalkInDis "18.09.01";
BA_ "Description" SG_ 1005 RLPSU_TiltUpDis "2nd Left side seat moving state  : Tilt up";
BA_ "GenSigSendType" SG_ 1005 RLPSU_TiltUpDis 4;
BA_ "UserSigValidity" SG_ 1005 RLPSU_TiltUpDis 0;
BA_REL_ "GenSigTimeoutTime" BU_SG_REL_ CGW_CCU SG_ 1005 RLPSU_TiltUpDis 1500;
BA_ "Version" SG_ 1005 RLPSU_TiltUpDis "18.09.01";
BA_ "GenMsgSendType" BO_ 1006 0;
BA_ "Description" SG_ 1006 RRPSU_FldDis "2nd Right side seat moving state  : Folding";
BA_ "GenSigSendType" SG_ 1006 RRPSU_FldDis 4;
BA_ "UserSigValidity" SG_ 1006 RRPSU_FldDis 0;
BA_REL_ "GenSigTimeoutTime" BU_SG_REL_ CGW_CCU SG_ 1006 RRPSU_FldDis 1500;
BA_ "Version" SG_ 1006 RRPSU_FldDis "18.09.01";
BA_ "Description" SG_ 1006 RRPSU_TiltDnDis "2nd Right side seat moving state  : Tilt down";
BA_ "GenSigSendType" SG_ 1006 RRPSU_TiltDnDis 4;
BA_ "UserSigValidity" SG_ 1006 RRPSU_TiltDnDis 0;
BA_REL_ "GenSigTimeoutTime" BU_SG_REL_ CGW_CCU SG_ 1006 RRPSU_TiltDnDis 1500;
BA_ "Version" SG_ 1006 RRPSU_TiltDnDis "18.09.01";
BA_ "Description" SG_ 1006 RRPSU_RecFwdDis "2nd Right side seat moving state  : Recline Forward";
BA_ "GenSigSendType" SG_ 1006 RRPSU_RecFwdDis 4;
BA_ "UserSigValidity" SG_ 1006 RRPSU_RecFwdDis 0;
BA_REL_ "GenSigTimeoutTime" BU_SG_REL_ CGW_CCU SG_ 1006 RRPSU_RecFwdDis 1500;
BA_ "Version" SG_ 1006 RRPSU_RecFwdDis "18.09.01";
BA_ "Description" SG_ 1006 RRPSU_RecBwdDis "2nd Right side seat moving state  : Recline Backward";
BA_ "GenSigSendType" SG_ 1006 RRPSU_RecBwdDis 4;
BA_ "UserSigValidity" SG_ 1006 RRPSU_RecBwdDis 0;
BA_REL_ "GenSigTimeoutTime" BU_SG_REL_ CGW_CCU SG_ 1006 RRPSU_RecBwdDis 1500;
BA_ "Version" SG_ 1006 RRPSU_RecBwdDis "18.09.01";
BA_ "Description" SG_ 1006 RRPSU_RlxModeDis "2nd Right side seat moving state  : Relax mode";
BA_ "GenSigSendType" SG_ 1006 RRPSU_RlxModeDis 4;
BA_ "UserSigValidity" SG_ 1006 RRPSU_RlxModeDis 0;
BA_ "Version" SG_ 1006 RRPSU_RlxModeDis "18.09.02";
BA_ "Description" SG_ 1006 RRPSU_Folding_SW "Interlocking signal between DPSM and RRPSU";
BA_ "GenSigSendType" SG_ 1006 RRPSU_Folding_SW 4;
BA_ "UserSigValidity" SG_ 1006 RRPSU_Folding_SW 0;
BA_ "Version" SG_ 1006 RRPSU_Folding_SW "19.03.05";
BA_ "Description" SG_ 1006 RRPSU_UnFldDis "2nd Right side seat moving state  : UnFolding";
BA_ "GenSigSendType" SG_ 1006 RRPSU_UnFldDis 4;
BA_ "UserSigValidity" SG_ 1006 RRPSU_UnFldDis 0;
BA_ "Version" SG_ 1006 RRPSU_UnFldDis "18.09.01";
BA_ "Description" SG_ 1006 RRPSU_Unfolding_SW "Interlocking signal between DPSM and RRPSU";
BA_ "GenSigSendType" SG_ 1006 RRPSU_Unfolding_SW 4;
BA_ "UserSigValidity" SG_ 1006 RRPSU_Unfolding_SW 0;
BA_ "Version" SG_ 1006 RRPSU_Unfolding_SW "19.03.05";
BA_ "Description" SG_ 1006 RRPSU_WalkIn_SW "Interlocking signal between DPSM and RRPSU";
BA_ "GenSigSendType" SG_ 1006 RRPSU_WalkIn_SW 4;
BA_ "UserSigValidity" SG_ 1006 RRPSU_WalkIn_SW 0;
BA_ "Version" SG_ 1006 RRPSU_WalkIn_SW "19.03.05";
BA_ "Description" SG_ 1006 RRPSU_UnwalkIn_SW "Interlocking signal between DPSM and RRPSU";
BA_ "GenSigSendType" SG_ 1006 RRPSU_UnwalkIn_SW 4;
BA_ "UserSigValidity" SG_ 1006 RRPSU_UnwalkIn_SW 0;
BA_ "Version" SG_ 1006 RRPSU_UnwalkIn_SW "19.03.05";
BA_ "Description" SG_ 1006 RRPSU_Folding_Postion "RRPSU Position Information";
BA_ "GenSigSendType" SG_ 1006 RRPSU_Folding_Postion 4;
BA_ "UserSigValidity" SG_ 1006 RRPSU_Folding_Postion 0;
BA_REL_ "GenSigTimeoutTime" BU_SG_REL_ CGW_CCU SG_ 1006 RRPSU_Folding_Postion 1500;
BA_ "Version" SG_ 1006 RRPSU_Folding_Postion "19.03.05";
BA_ "Description" SG_ 1006 RRPSU_Folding_State_Popup "Rear RH seat Folding State information";
BA_ "GenSigSendType" SG_ 1006 RRPSU_Folding_State_Popup 4;
BA_ "UserSigValidity" SG_ 1006 RRPSU_Folding_State_Popup 0;
BA_REL_ "GenSigTimeoutTime" BU_SG_REL_ CGW_CCU SG_ 1006 RRPSU_Folding_State_Popup 1500;
BA_ "Version" SG_ 1006 RRPSU_Folding_State_Popup "18.10.02";
BA_ "Description" SG_ 1006 RRPSU_Relax_State_Popup "Rear RH seat Relax State information";
BA_ "GenSigSendType" SG_ 1006 RRPSU_Relax_State_Popup 4;
BA_ "UserSigValidity" SG_ 1006 RRPSU_Relax_State_Popup 0;
BA_REL_ "GenSigTimeoutTime" BU_SG_REL_ CGW_CCU SG_ 1006 RRPSU_Relax_State_Popup 1500;
BA_ "Version" SG_ 1006 RRPSU_Relax_State_Popup "18.10.02";
BA_ "Description" SG_ 1006 RRPSU_SlideFwdDis "2nd Right side seat moving state  : Slide Forward";
BA_ "GenSigSendType" SG_ 1006 RRPSU_SlideFwdDis 4;
BA_ "UserSigValidity" SG_ 1006 RRPSU_SlideFwdDis 0;
BA_REL_ "GenSigTimeoutTime" BU_SG_REL_ CGW_CCU SG_ 1006 RRPSU_SlideFwdDis 1500;
BA_ "Version" SG_ 1006 RRPSU_SlideFwdDis "19.03.05";
BA_ "Description" SG_ 1006 RRPSU_SlideBwdDis "2nd Right side seat moving state  : Slide Backward";
BA_ "GenSigSendType" SG_ 1006 RRPSU_SlideBwdDis 4;
BA_ "UserSigValidity" SG_ 1006 RRPSU_SlideBwdDis 0;
BA_REL_ "GenSigTimeoutTime" BU_SG_REL_ CGW_CCU SG_ 1006 RRPSU_SlideBwdDis 1500;
BA_ "Version" SG_ 1006 RRPSU_SlideBwdDis "19.03.05";
BA_ "Description" SG_ 1006 RRPSU_WalkinDis "2nd Right side seat moving state : Walk In";
BA_ "GenSigSendType" SG_ 1006 RRPSU_WalkinDis 4;
BA_ "UserSigValidity" SG_ 1006 RRPSU_WalkinDis 0;
BA_ "Version" SG_ 1006 RRPSU_WalkinDis "18.09.01";
BA_ "Description" SG_ 1006 RRPSU_WalkInState "2nd Right side seat Walk-in Ready state";
BA_ "GenSigSendType" SG_ 1006 RRPSU_WalkInState 4;
BA_ "UserSigValidity" SG_ 1006 RRPSU_WalkInState 0;
BA_ "Version" SG_ 1006 RRPSU_WalkInState "19.03.05";
BA_ "Description" SG_ 1006 RRPSU_UnwalkinDis "2nd Right side seat moving state : Un Walk In";
BA_ "GenSigSendType" SG_ 1006 RRPSU_UnwalkinDis 4;
BA_ "UserSigValidity" SG_ 1006 RRPSU_UnwalkinDis 0;
BA_ "Version" SG_ 1006 RRPSU_UnwalkinDis "18.09.01";
BA_ "Description" SG_ 1006 RRPSU_TiltUpDis "2nd Right side seat moving state  : Tilt up";
BA_ "GenSigSendType" SG_ 1006 RRPSU_TiltUpDis 4;
BA_ "UserSigValidity" SG_ 1006 RRPSU_TiltUpDis 0;
BA_REL_ "GenSigTimeoutTime" BU_SG_REL_ CGW_CCU SG_ 1006 RRPSU_TiltUpDis 1500;
BA_ "Version" SG_ 1006 RRPSU_TiltUpDis "18.09.01";
BA_ "GenMsgSendType" BO_ 2223056129 0;
BA_ "GenMsgCycleTime" BO_ 2223056129 50;
BA_ "GenMsgCycleTimeFast" BO_ 2223056129 0;
BA_ "GenMsgNrOfRepetition" BO_ 2223056129 0;
BA_ "VFrameFormat" BO_ 2223056129 1;
BA_ "Description" SG_ 2223056129 SAS_Crc1Val "The data area for CRC calculation is based on the data length (DLC) of the message DB.

The CRC shall be calculated over the entire data block (excluding the CRC bytes) including the user data, alive counter and Data ID

 

- CRC Polynomial (0x1021) , Initial Value : 0xFFFF, XOR value : 0x0000, Data ID : Message ID + 0xF800 

- The initial value is for CRC calculation and the message should be sent with the calculated result value. 

- The mathematical expression to 16 bit CRC polynomial is given here. G(x) = x16 + x12 + x5 + 1";
BA_ "GenSigStartValue" SG_ 2223056129 SAS_Crc1Val 65535;
BA_ "UserSigValidity" SG_ 2223056129 SAS_Crc1Val 3;
BA_ "RoutingFactor" SG_ 2223056129 SAS_Crc1Val 5;
BA_ "Version" SG_ 2223056129 SAS_Crc1Val "18.11.08";
BA_ "Description" SG_ 2223056129 SAS_AlvCnt1Val "For the first transmission request for a data element the counter shall be initialized with 0 and shall be incremented by 1 for every subsequent send request. 

When the counter reaches the maximum value(0xFF), then it shall restart with 0 for the next send request";
BA_ "UserSigValidity" SG_ 2223056129 SAS_AlvCnt1Val 3;
BA_ "RoutingFactor" SG_ 2223056129 SAS_AlvCnt1Val 5;
BA_ "Version" SG_ 2223056129 SAS_AlvCnt1Val "18.11.08";
BA_ "Description" SG_ 2223056129 SAS_AnglVal "Information regarding the steering wheel angle.  (PH) = (HEX) * 0.1 (0 <  HEX < 7FFFH) or (PH) = (HEX - 65536) * 0.1 (HEX > 7FFFH)



this signal has direction information.

'+' Value means Counter clock wise rotation.

'-' value means Clock wise rotation.";
BA_ "GenSigStartValue" SG_ 2223056129 SAS_AnglVal 32767;
BA_ "UserSigValidity" SG_ 2223056129 SAS_AnglVal 3;
BA_ "RoutingFactor" SG_ 2223056129 SAS_AnglVal 5;
BA_ "Version" SG_ 2223056129 SAS_AnglVal "21.07.05";
BA_ "Description" SG_ 2223056129 SAS_SpdVal "Information regarding the steering wheel rotation speed 

(PH) = (HEX) * 4 (0 ¡Â HEX < 254)";
BA_ "GenSigStartValue" SG_ 2223056129 SAS_SpdVal 255;
BA_ "UserSigValidity" SG_ 2223056129 SAS_SpdVal 3;
BA_ "RoutingFactor" SG_ 2223056129 SAS_SpdVal 5;
BA_ "Version" SG_ 2223056129 SAS_SpdVal "21.07.05";
BA_ "Description" SG_ 2223056129 SAS_IntSta "Information regarding the steering angle sensor¡¯s internal state. If SAS_AnglVal value is O.K., SAS_OK flag is set and otherwise SAS_OK flag is cleared. If steering angle sensor has been calibrated, SAS_CAL flag is set and otherwise cleared.

SF1 - SF5 : for internal use only



SAS_OK(=1), SAS_CAL(=1) : SAS_AnglVal(=value), SAS_SpdVal(=value)

SAS_OK(=1), SAS_CAL(=0) : SAS_AnglVal(=7FFFh), SAS_SpdVal(=value)

SAS_OK(=0), SAS_CAL(=1) : SAS_AnglVal(=7FFFh), SAS_SpdVal(=FFh)

SAS_OK(=0), SAS_CAL(=0) : SAS_AnglVal(=7FFFh), SAS_SpdVal(=FFh)



¡Ø If SAS is trimmed, SAS_Trim flag = 1.

If SAS is not trimmed (in this case SAS_OK=0 and SAS_CAL=0), SAS_Trim flag=0.";
BA_ "GenSigStartValue" SG_ 2223056129 SAS_IntSta 14;
BA_ "UserSigValidity" SG_ 2223056129 SAS_IntSta 3;
BA_ "RoutingFactor" SG_ 2223056129 SAS_IntSta 5;
BA_ "Version" SG_ 2223056129 SAS_IntSta "21.07.05";
BA_ "GenMsgSendType" BO_ 2223056130 0;
BA_ "GenMsgCycleTime" BO_ 2223056130 50;
BA_ "GenMsgCycleTimeFast" BO_ 2223056130 0;
BA_ "GenMsgNrOfRepetition" BO_ 2223056130 0;
BA_ "VFrameFormat" BO_ 2223056130 1;
BA_ "GenMsgCycleTime" BO_ 1964 0;
BA_ "GenMsgCycleTimeFast" BO_ 1964 0;
BA_ "GenMsgNrOfRepetition" BO_ 1964 0;
BA_ "DiagResponse" BO_ 1964 1;
BA_ "GenMsgILSupport" BO_ 1964 0;
BA_ "TpMessage" BO_ 1964 1;
BA_ "TpTxIndex" BO_ 1964 172;
BA_ "Description" SG_ 1964 SCM_GST_Byte0 "TP Index : 172";
BA_ "UsrSigPurpose" SG_ 1964 SCM_GST_Byte0 4;
BA_ "UserSigValidity" SG_ 1964 SCM_GST_Byte0 0;
BA_REL_ "GenSigTimeoutTime" BU_SG_REL_ CGW_CCU SG_ 1964 SCM_GST_Byte0 0;
BA_ "NetworkRequest" SG_ 1964 SCM_GST_Byte0 0;
BA_ "NetworkRequestHoldingTime" SG_ 1964 SCM_GST_Byte0 5000;
BA_ "Version" SG_ 1964 SCM_GST_Byte0 "21.02.04";
BA_ "Description" SG_ 1964 SCM_GST_Byte2 "TP Index : 172";
BA_ "UsrSigPurpose" SG_ 1964 SCM_GST_Byte2 4;
BA_ "UserSigValidity" SG_ 1964 SCM_GST_Byte2 0;
BA_REL_ "GenSigTimeoutTime" BU_SG_REL_ CGW_CCU SG_ 1964 SCM_GST_Byte2 0;
BA_ "NetworkRequest" SG_ 1964 SCM_GST_Byte2 0;
BA_ "NetworkRequestHoldingTime" SG_ 1964 SCM_GST_Byte2 5000;
BA_ "Version" SG_ 1964 SCM_GST_Byte2 "21.02.04";
BA_ "Description" SG_ 1964 SCM_GST_Byte3 "TP Index : 172";
BA_ "UsrSigPurpose" SG_ 1964 SCM_GST_Byte3 4;
BA_ "UserSigValidity" SG_ 1964 SCM_GST_Byte3 0;
BA_REL_ "GenSigTimeoutTime" BU_SG_REL_ CGW_CCU SG_ 1964 SCM_GST_Byte3 0;
BA_ "NetworkRequest" SG_ 1964 SCM_GST_Byte3 0;
BA_ "NetworkRequestHoldingTime" SG_ 1964 SCM_GST_Byte3 5000;
BA_ "Version" SG_ 1964 SCM_GST_Byte3 "21.02.04";
BA_ "Description" SG_ 1964 SCM_GST_Byte4 "TP Index : 172";
BA_ "UsrSigPurpose" SG_ 1964 SCM_GST_Byte4 4;
BA_ "UserSigValidity" SG_ 1964 SCM_GST_Byte4 0;
BA_REL_ "GenSigTimeoutTime" BU_SG_REL_ CGW_CCU SG_ 1964 SCM_GST_Byte4 0;
BA_ "NetworkRequest" SG_ 1964 SCM_GST_Byte4 0;
BA_ "NetworkRequestHoldingTime" SG_ 1964 SCM_GST_Byte4 5000;
BA_ "Version" SG_ 1964 SCM_GST_Byte4 "21.02.04";
BA_ "Description" SG_ 1964 SCM_GST_Byte5 "TP Index : 172";
BA_ "UsrSigPurpose" SG_ 1964 SCM_GST_Byte5 4;
BA_ "UserSigValidity" SG_ 1964 SCM_GST_Byte5 0;
BA_REL_ "GenSigTimeoutTime" BU_SG_REL_ CGW_CCU SG_ 1964 SCM_GST_Byte5 0;
BA_ "NetworkRequest" SG_ 1964 SCM_GST_Byte5 0;
BA_ "NetworkRequestHoldingTime" SG_ 1964 SCM_GST_Byte5 5000;
BA_ "Version" SG_ 1964 SCM_GST_Byte5 "21.02.04";
BA_ "Description" SG_ 1964 SCM_GST_Byte6 "TP Index : 172";
BA_ "UsrSigPurpose" SG_ 1964 SCM_GST_Byte6 4;
BA_ "UserSigValidity" SG_ 1964 SCM_GST_Byte6 0;
BA_REL_ "GenSigTimeoutTime" BU_SG_REL_ CGW_CCU SG_ 1964 SCM_GST_Byte6 0;
BA_ "NetworkRequest" SG_ 1964 SCM_GST_Byte6 0;
BA_ "NetworkRequestHoldingTime" SG_ 1964 SCM_GST_Byte6 5000;
BA_ "Version" SG_ 1964 SCM_GST_Byte6 "21.02.04";
BA_ "Description" SG_ 1964 SCM_GST_Byte7 "TP Index : 172";
BA_ "UsrSigPurpose" SG_ 1964 SCM_GST_Byte7 4;
BA_ "UserSigValidity" SG_ 1964 SCM_GST_Byte7 0;
BA_REL_ "GenSigTimeoutTime" BU_SG_REL_ CGW_CCU SG_ 1964 SCM_GST_Byte7 0;
BA_ "NetworkRequest" SG_ 1964 SCM_GST_Byte7 0;
BA_ "NetworkRequestHoldingTime" SG_ 1964 SCM_GST_Byte7 5000;
BA_ "Version" SG_ 1964 SCM_GST_Byte7 "21.02.04";
BA_ "Description" SG_ 1964 SCM_GST_Byte1 "TP Index : 172";
BA_ "UsrSigPurpose" SG_ 1964 SCM_GST_Byte1 4;
BA_ "UserSigValidity" SG_ 1964 SCM_GST_Byte1 0;
BA_REL_ "GenSigTimeoutTime" BU_SG_REL_ CGW_CCU SG_ 1964 SCM_GST_Byte1 0;
BA_ "NetworkRequest" SG_ 1964 SCM_GST_Byte1 0;
BA_ "NetworkRequestHoldingTime" SG_ 1964 SCM_GST_Byte1 5000;
BA_ "Version" SG_ 1964 SCM_GST_Byte1 "21.02.04";
BA_ "GenMsgCycleTime" BO_ 1420 0;
BA_ "GenMsgCycleTimeFast" BO_ 1420 0;
BA_ "GenMsgNrOfRepetition" BO_ 1420 0;
BA_ "DiagResponse" BO_ 1420 1;
BA_ "GenMsgILSupport" BO_ 1420 0;
BA_ "TpMessage" BO_ 1420 1;
BA_ "TpTxIndex" BO_ 1420 233;
BA_ "Description" SG_ 1420 SGU_GST_Byte0 "TP Index : 233";
BA_ "UsrSigPurpose" SG_ 1420 SGU_GST_Byte0 4;
BA_ "UserSigValidity" SG_ 1420 SGU_GST_Byte0 0;
BA_REL_ "GenSigTimeoutTime" BU_SG_REL_ CGW_CCU SG_ 1420 SGU_GST_Byte0 0;
BA_ "Version" SG_ 1420 SGU_GST_Byte0 "21.08.02";
BA_ "Description" SG_ 1420 SGU_GST_Byte2 "TP Index : 233";
BA_ "UsrSigPurpose" SG_ 1420 SGU_GST_Byte2 4;
BA_ "UserSigValidity" SG_ 1420 SGU_GST_Byte2 0;
BA_REL_ "GenSigTimeoutTime" BU_SG_REL_ CGW_CCU SG_ 1420 SGU_GST_Byte2 0;
BA_ "Version" SG_ 1420 SGU_GST_Byte2 "21.08.02";
BA_ "Description" SG_ 1420 SGU_GST_Byte3 "TP Index : 233";
BA_ "UsrSigPurpose" SG_ 1420 SGU_GST_Byte3 4;
BA_ "UserSigValidity" SG_ 1420 SGU_GST_Byte3 0;
BA_REL_ "GenSigTimeoutTime" BU_SG_REL_ CGW_CCU SG_ 1420 SGU_GST_Byte3 0;
BA_ "Version" SG_ 1420 SGU_GST_Byte3 "21.08.02";
BA_ "Description" SG_ 1420 SGU_GST_Byte4 "TP Index : 233";
BA_ "UsrSigPurpose" SG_ 1420 SGU_GST_Byte4 4;
BA_ "UserSigValidity" SG_ 1420 SGU_GST_Byte4 0;
BA_REL_ "GenSigTimeoutTime" BU_SG_REL_ CGW_CCU SG_ 1420 SGU_GST_Byte4 0;
BA_ "Version" SG_ 1420 SGU_GST_Byte4 "21.08.02";
BA_ "Description" SG_ 1420 SGU_GST_Byte5 "TP Index : 233";
BA_ "UsrSigPurpose" SG_ 1420 SGU_GST_Byte5 4;
BA_ "UserSigValidity" SG_ 1420 SGU_GST_Byte5 0;
BA_REL_ "GenSigTimeoutTime" BU_SG_REL_ CGW_CCU SG_ 1420 SGU_GST_Byte5 0;
BA_ "Version" SG_ 1420 SGU_GST_Byte5 "21.08.02";
BA_ "Description" SG_ 1420 SGU_GST_Byte6 "TP Index : 233";
BA_ "UsrSigPurpose" SG_ 1420 SGU_GST_Byte6 4;
BA_ "UserSigValidity" SG_ 1420 SGU_GST_Byte6 0;
BA_REL_ "GenSigTimeoutTime" BU_SG_REL_ CGW_CCU SG_ 1420 SGU_GST_Byte6 0;
BA_ "Version" SG_ 1420 SGU_GST_Byte6 "21.08.02";
BA_ "Description" SG_ 1420 SGU_GST_Byte7 "TP Index : 233";
BA_ "UsrSigPurpose" SG_ 1420 SGU_GST_Byte7 4;
BA_ "UserSigValidity" SG_ 1420 SGU_GST_Byte7 0;
BA_REL_ "GenSigTimeoutTime" BU_SG_REL_ CGW_CCU SG_ 1420 SGU_GST_Byte7 0;
BA_ "Version" SG_ 1420 SGU_GST_Byte7 "21.08.02";
BA_ "Description" SG_ 1420 SGU_GST_Byte1 "TP Index : 233";
BA_ "UsrSigPurpose" SG_ 1420 SGU_GST_Byte1 4;
BA_ "UserSigValidity" SG_ 1420 SGU_GST_Byte1 0;
BA_REL_ "GenSigTimeoutTime" BU_SG_REL_ CGW_CCU SG_ 1420 SGU_GST_Byte1 0;
BA_ "Version" SG_ 1420 SGU_GST_Byte1 "21.08.02";
BA_ "GenMsgSendType" BO_ 463 0;
BA_ "GenMsgCycleTime" BO_ 463 20;
BA_ "GenMsgCycleTimeFast" BO_ 463 0;
BA_ "GenMsgNrOfRepetition" BO_ 463 0;
BA_ "GenMsgDelayTime" BO_ 463 0;
BA_ "Description" SG_ 463 SWRC_Crc3Val "The data area for CRC calculation is based on the data length (DLC) of the message DB.

The CRC shall be calculated over the entire data block (excluding the CRC bytes) including the user data, alive counter and Data ID 

 

- CRC Polynomial (0x1D) , Initial Value : 0x00, XOR value : 0xFF, Data ID Mode : Both, Data ID : Message ID + 0xF800 

- The initial value is for CRC calculation and the message should be sent with the calculated result value. 

The mathematical expression to 8 bit CRC polynomial is given here. G(x) = x8 + x4 + x3 + x2 + 1";
BA_ "GenSigStartValue" SG_ 463 SWRC_Crc3Val 255;
BA_ "UserSigValidity" SG_ 463 SWRC_Crc3Val 0;
BA_ "Version" SG_ 463 SWRC_Crc3Val "19.11.02";
BA_ "Description" SG_ 463 SWRC_AlvCnt3Val "For the first transmission request for a data element the counter shall be initialized with 0 and shall be incremented by 1

for every subsequent send request. When the counter reaches the maximum value(0xE), then it shall restart with 0 for the next send request";
BA_ "UserSigValidity" SG_ 463 SWRC_AlvCnt3Val 0;
BA_ "Version" SG_ 463 SWRC_AlvCnt3Val "19.11.02";
BA_ "Description" SG_ 463 SWRC_CrsSwSta "Cruise switch status

C-CAN Gateway needed";
BA_ "UserSigValidity" SG_ 463 SWRC_CrsSwSta 0;
BA_ "Version" SG_ 463 SWRC_CrsSwSta "21.07.05";
BA_ "Description" SG_ 463 SWRC_CrsMainSwSta "Cruise on/off switch

C-CAN Gateway needed";
BA_ "UserSigValidity" SG_ 463 SWRC_CrsMainSwSta 0;
BA_ "Version" SG_ 463 SWRC_CrsMainSwSta "21.07.05";
BA_ "Description" SG_ 463 SWRC_SldMainSwSta "Speedlimiter on/off switch

C-CAN Gateway needed";
BA_ "UserSigValidity" SG_ 463 SWRC_SldMainSwSta 0;
BA_ "Version" SG_ 463 SWRC_SldMainSwSta "19.11.02";
BA_ "Description" SG_ 463 SWRC_LFASwSta "LFA on/off switch

C-CAN Gateway needed";
BA_ "UserSigValidity" SG_ 463 SWRC_LFASwSta 0;
BA_ "Version" SG_ 463 SWRC_LFASwSta "21.07.05";
BA_ "Description" SG_ 463 SWRC_PaddleUpSwSta "Paddle Up switch

C-CAN Gateway needed";
BA_ "UserSigValidity" SG_ 463 SWRC_PaddleUpSwSta 0;
BA_ "Version" SG_ 463 SWRC_PaddleUpSwSta "19.11.02";
BA_ "Description" SG_ 463 SWRC_PaddleDnSwSta "Paddle Down switch

C-CAN Gateway needed";
BA_ "UserSigValidity" SG_ 463 SWRC_PaddleDnSwSta 0;
BA_ "Version" SG_ 463 SWRC_PaddleDnSwSta "19.11.02";
BA_ "Description" SG_ 463 SWRC_Info "Steering Wheel Remocon switch information 

This signal is used to determine 'CAN type SWRX' is applied or not in this vehicle.



0x0 : CAN type SWRC is Not Applied

0x1 : CAN type SWRC Applied";
BA_ "UserSigValidity" SG_ 463 SWRC_Info 0;
BA_ "Version" SG_ 463 SWRC_Info "21.07.05";
BA_ "UserSigValidity" SG_ 463 SWRC_HdpSwSta 0;
BA_ "Version" SG_ 463 SWRC_HdpSwSta "19.12.00";
BA_ "GenMsgCycleTime" BO_ 1967 0;
BA_ "GenMsgCycleTimeFast" BO_ 1967 0;
BA_ "GenMsgNrOfRepetition" BO_ 1967 0;
BA_ "DiagResponse" BO_ 1967 1;
BA_ "GenMsgILSupport" BO_ 1967 0;
BA_ "TpMessage" BO_ 1967 1;
BA_ "TpTxIndex" BO_ 1967 175;
BA_ "Description" SG_ 1967 SWRC_GST_Byte0 "TP Index : 175";
BA_ "UsrSigPurpose" SG_ 1967 SWRC_GST_Byte0 4;
BA_ "UserSigValidity" SG_ 1967 SWRC_GST_Byte0 0;
BA_REL_ "GenSigTimeoutTime" BU_SG_REL_ CGW_CCU SG_ 1967 SWRC_GST_Byte0 0;
BA_ "NetworkRequest" SG_ 1967 SWRC_GST_Byte0 0;
BA_ "NetworkRequestHoldingTime" SG_ 1967 SWRC_GST_Byte0 5000;
BA_ "Version" SG_ 1967 SWRC_GST_Byte0 "21.02.04";
BA_ "Description" SG_ 1967 SWRC_GST_Byte2 "TP Index : 175";
BA_ "UsrSigPurpose" SG_ 1967 SWRC_GST_Byte2 4;
BA_ "UserSigValidity" SG_ 1967 SWRC_GST_Byte2 0;
BA_REL_ "GenSigTimeoutTime" BU_SG_REL_ CGW_CCU SG_ 1967 SWRC_GST_Byte2 0;
BA_ "NetworkRequest" SG_ 1967 SWRC_GST_Byte2 0;
BA_ "NetworkRequestHoldingTime" SG_ 1967 SWRC_GST_Byte2 5000;
BA_ "Version" SG_ 1967 SWRC_GST_Byte2 "21.02.04";
BA_ "Description" SG_ 1967 SWRC_GST_Byte3 "TP Index : 175";
BA_ "UsrSigPurpose" SG_ 1967 SWRC_GST_Byte3 4;
BA_ "UserSigValidity" SG_ 1967 SWRC_GST_Byte3 0;
BA_REL_ "GenSigTimeoutTime" BU_SG_REL_ CGW_CCU SG_ 1967 SWRC_GST_Byte3 0;
BA_ "NetworkRequest" SG_ 1967 SWRC_GST_Byte3 0;
BA_ "NetworkRequestHoldingTime" SG_ 1967 SWRC_GST_Byte3 5000;
BA_ "Version" SG_ 1967 SWRC_GST_Byte3 "21.02.04";
BA_ "Description" SG_ 1967 SWRC_GST_Byte4 "TP Index : 175";
BA_ "UsrSigPurpose" SG_ 1967 SWRC_GST_Byte4 4;
BA_ "UserSigValidity" SG_ 1967 SWRC_GST_Byte4 0;
BA_REL_ "GenSigTimeoutTime" BU_SG_REL_ CGW_CCU SG_ 1967 SWRC_GST_Byte4 0;
BA_ "NetworkRequest" SG_ 1967 SWRC_GST_Byte4 0;
BA_ "NetworkRequestHoldingTime" SG_ 1967 SWRC_GST_Byte4 5000;
BA_ "Version" SG_ 1967 SWRC_GST_Byte4 "21.02.04";
BA_ "Description" SG_ 1967 SWRC_GST_Byte5 "TP Index : 175";
BA_ "UsrSigPurpose" SG_ 1967 SWRC_GST_Byte5 4;
BA_ "UserSigValidity" SG_ 1967 SWRC_GST_Byte5 0;
BA_REL_ "GenSigTimeoutTime" BU_SG_REL_ CGW_CCU SG_ 1967 SWRC_GST_Byte5 0;
BA_ "NetworkRequest" SG_ 1967 SWRC_GST_Byte5 0;
BA_ "NetworkRequestHoldingTime" SG_ 1967 SWRC_GST_Byte5 5000;
BA_ "Version" SG_ 1967 SWRC_GST_Byte5 "21.02.04";
BA_ "Description" SG_ 1967 SWRC_GST_Byte6 "TP Index : 175";
BA_ "UsrSigPurpose" SG_ 1967 SWRC_GST_Byte6 4;
BA_ "UserSigValidity" SG_ 1967 SWRC_GST_Byte6 0;
BA_REL_ "GenSigTimeoutTime" BU_SG_REL_ CGW_CCU SG_ 1967 SWRC_GST_Byte6 0;
BA_ "NetworkRequest" SG_ 1967 SWRC_GST_Byte6 0;
BA_ "NetworkRequestHoldingTime" SG_ 1967 SWRC_GST_Byte6 5000;
BA_ "Version" SG_ 1967 SWRC_GST_Byte6 "21.02.04";
BA_ "Description" SG_ 1967 SWRC_GST_Byte7 "TP Index : 175";
BA_ "UsrSigPurpose" SG_ 1967 SWRC_GST_Byte7 4;
BA_ "UserSigValidity" SG_ 1967 SWRC_GST_Byte7 0;
BA_REL_ "GenSigTimeoutTime" BU_SG_REL_ CGW_CCU SG_ 1967 SWRC_GST_Byte7 0;
BA_ "NetworkRequest" SG_ 1967 SWRC_GST_Byte7 0;
BA_ "NetworkRequestHoldingTime" SG_ 1967 SWRC_GST_Byte7 5000;
BA_ "Version" SG_ 1967 SWRC_GST_Byte7 "21.02.04";
BA_ "Description" SG_ 1967 SWRC_GST_Byte1 "TP Index : 175";
BA_ "UsrSigPurpose" SG_ 1967 SWRC_GST_Byte1 4;
BA_ "UserSigValidity" SG_ 1967 SWRC_GST_Byte1 0;
BA_REL_ "GenSigTimeoutTime" BU_SG_REL_ CGW_CCU SG_ 1967 SWRC_GST_Byte1 0;
BA_ "NetworkRequest" SG_ 1967 SWRC_GST_Byte1 0;
BA_ "NetworkRequestHoldingTime" SG_ 1967 SWRC_GST_Byte1 5000;
BA_ "Version" SG_ 1967 SWRC_GST_Byte1 "21.02.04";
BA_ "GenMsgSendType" BO_ 2332213252 0;
BA_ "GenMsgCycleTimeFast" BO_ 2332213252 0;
BA_ "GenMsgNrOfRepetition" BO_ 2332213252 0;
BA_ "VFrameFormat" BO_ 2332213252 1;
VAL_ 479 ALBCU_LumbarUpDis 0 "default" 1 "off" 2 "on" 3 "invalid" ;
VAL_ 479 ALBCU_BolsterDefDis 0 "default" 1 "off" 2 "on" 3 "invalid" ;
VAL_ 479 ALBCU_CushInfDis 0 "default" 1 "off" 2 "on" 3 "invalid" ;
VAL_ 479 ALBCU_CushDefDis 0 "default" 1 "off" 2 "on" 3 "invalid" ;
VAL_ 479 ALBCU_ActiveDis 0 "Default" 1 "Off" 2 "Mode1" 3 "Mode2" 4 "Mode3" 5 "Reserved" 6 "Reserved" 7 "Invalid" ;
VAL_ 479 ALBCU_DrvModUSMSta 0 "Default" 1 "Off" 2 "On" 3 "Invalid" ;
VAL_ 479 ALBCU_LumbarMidDis 0 "default" 1 "off" 2 "on" 3 "invalid" ;
VAL_ 479 ALBCU_ActiveStrSta 0 "Default" 1 "Normal" 2 "Intensity" 3 "Invalid" ;
VAL_ 479 ALBCU_ActiveTimeSta 0 "Default" 1 "10min" 2 "15min" 3 "20min" 4 "Reserved" 5 "Reserved" 6 "Reserved" 7 "Invalid" ;
VAL_ 479 ALBCU_CellOpt 0 "Default" 1 "3Cell" 2 "5Cell" 3 "7Cell" 4 "Invalid" 5 "Invalid" 6 "Invalid" 7 "Invalid" ;
VAL_ 479 ALBCU_BodySpprtSta 0 "Default" 1 "Off" 2 "On" 3 "Invalid" ;
VAL_ 479 ALBCU_BodySpprtDis 0 "Default" 1 "Off" 2 "On" 3 "Invalid" ;
VAL_ 479 ALBCU_SmartCtrl_Set_Rvalue 0 "Init" 1 "Off" 2 "10min" 3 "20min" 4 "30min" 5 "40min" 6 "50min" 7 "60min" 8 "RESERVED" 9 "RESERVED" 10 "RESERVED" 11 "RESERVED" 12 "RESERVED" 13 "RESERVED" 14 "RESERVED" 15 "Invalid" ;
VAL_ 479 ALBCU_LumbarLowDis 0 "default" 1 "off" 2 "on" 3 "invalid" ;
VAL_ 479 ALBCU_LumbarDefDis 0 "default" 1 "off" 2 "on" 3 "invalid" ;
VAL_ 479 ALBCU_BolsterInfDis 0 "default" 1 "off" 2 "on" 3 "invalid" ;
VAL_ 2235651329 APSB_CrashActvSta 0 "APSB Inactive" 1 "APSB is active" 2 "Rserved" 3 "Rserved" ;
VAL_ 2235651329 APSB_RRDrvImpt 0 "Rough Road Impact is Inactive" 1 "Rough Road  Impact is PSB Front Active" 2 "Rough Road  Impact is PSB Rear Active" 3 "Rough Road  Impact is Failure" 4 "Reserved" 5 "Reserved" 6 "Reserved" 7 "Reserved" ;
VAL_ 2235651329 APSB_FCAFrImpt 0 "FCA Impact is Inactive" 1 "FCA Impact is PSB Front Active" 2 "FCA Impact is PSB Rear Active" 3 "FCA Impact is Failure" 4 "Reserved" 5 "Reserved" 6 "Reserved" 7 "Reserved" ;
VAL_ 2235651329 APSB_MinFrImpt 0 "Minor Front Impact is Inactive" 1 "Minor Front Impact is PSB Front Active" 2 "Minor Front Impact is PSB Rear Active" 3 "Minor Front Impact is Failure" 4 "Reserved" 5 "Reserved" 6 "Reserved" 7 "Reserved" ;
VAL_ 2235651329 APSB_MinSidImpt 0 "Minor Side Impact is Inactive" 1 "Minor Side Impact is PSB Front Active" 2 "Minor Side Impact is PSB Rear Active" 3 "Minor Side Impact is Failure" 4 "Reserved" 5 "Reserved" 6 "Reserved" 7 "Reserved" ;
VAL_ 2235651329 APSB_MinRollDetn 0 "Minor Roll Detection is Inactive" 1 "Minor Roll Detection  is PSB Front Active" 2 "Minor Roll Detection  is PSB Rear Active" 3 "Minor Roll Detection  is Failure" 4 "Reserved" 5 "Reserved" 6 "Reserved" 7 "Reserved" ;
VAL_ 2235651329 APSB_MinRearImpt 0 "Minor Rear Impact is Inactive" 1 "Minor Rear Impact is PSB Front Active" 2 "Minor Rear Impact is PSB Rear Active" 3 "Minor Rear Impact is Failure" 4 "Reserved" 5 "Reserved" 6 "Reserved" 7 "Reserved" ;
VAL_ 1007 ATS_LEDBgtnsUpDn 0 "Reserved" 1 "Brightness Up" 2 "Brightness Down" 3 "Invalid" ;
VAL_ 1007 ATS_FrMoodOn_Req 0 "Default" 1 "Off" 2 "On" 3 "Invalid" ;
VAL_ 1007 ATS_DoorOn_Req 0 "Default" 1 "Off" 2 "On" 3 "Invalid" ;
VAL_ 1007 ATS_RrMapLftOn_Req 0 "Default" 1 "Off" 2 "On" 3 "Invalid" ;
VAL_ 1007 ATS_RrMapRtOn_Req 0 "Default" 1 "Off" 2 "On" 3 "Invalid" ;
VAL_ 1007 ATS_RrRoomOn_Req 0 "Default" 1 "Off" 2 "On" 3 "Invalid" ;
VAL_ 1007 ATS_LEDClrUpDn 0 "Reserved" 1 "Color Up" 2 "Color Down" 3 "Invalid" ;
VAL_ 1007 ATS_RrMoodOn_Req 0 "Default" 1 "Off" 2 "On" 3 "Invalid" ;
VAL_ 1007 ATS_LEDClr_Set 0 "Color 1Step" 1 "Color 2Step" 2 "Color 3Step" 3 "Not Used" 4 "Not Used" 5 "Not Used" 6 "Invalid" 7 "System Fail" ;
VAL_ 1007 ATS_LEDBgtns_Set 0 "Brightness 1Step" 1 "Brightness 2Step" 2 "Brightness 3Step" 3 "Not Used" 4 "Not Used" 5 "Not Used" 6 "Invalid" 7 "System Fail" ;
VAL_ 1007 ATS_LEDClrUpDnBtn 0 "Button Off" 1 "Color Up" 2 "Color Down" 3 "Invalid" ;
VAL_ 1007 ATS_LEDBgtnsUpDnBtn 0 "Button Off" 1 "Brightness Up" 2 "Brightness Down" 3 "Invalid" ;
VAL_ 1007 ATS_FrMapLftOn_Req 0 "Default" 1 "Off" 2 "On" 3 "Invalid" ;
VAL_ 1007 ATS_FrMapRtOn_Req 0 "Default" 1 "Off" 2 "On" 3 "Invalid" ;
VAL_ 1007 ATS_FrRoomOn_Req 0 "Default" 1 "Off" 2 "On" 3 "Invalid" ;
VAL_ 992 BAlarm_BglrAlrmCurrentSta 0 "Off" 1 "DisArm" 2 "Arm" 3 "PreArm" 4 "ArmWait" 5 "ArmHold(Trunk)" 6 "ReArm" 7 "AutoLockTimer1" 8 "AutoLockTimer2" 9 "Alarm" 10 "Default" 11 "AutoLockTimer3(Tailgate)" 12 "Reserved" 13 "Reserved" 14 "Not Used" 15 "Error Indicator" ;
VAL_ 992 BAlarm_BglrAlrmSta 0 "DIS-,PRE-,AUTOLOCKTIMER1,2,3(TG)" 1 "ARM,-WAIT,RE-,ALARM,-HD(Trunk)" 2 "Not Used" 3 "Error Indicator" ;
VAL_ 992 BAlarm_PncAlrmSta 0 "Off" 1 "On (Panic Alarm ON)" 2 "Not Used" 3 "Error Indicator" ;
VAL_ 992 BAlarm_StrtInhbtRlySta 0 "Off" 1 "On" 2 "Not Used" 3 "Error Indicator" ;
VAL_ 992 BAlarm_BrglrHrnRlySta 0 "Off" 1 "On" 2 "Not Used" 3 "Error Indicator" ;
VAL_ 992 BCM_KeyInSta 0 "Off (Key removed)" 1 "On (Key inserted)" 2 "Not Used" 3 "Error Indicator" ;
VAL_ 992 BCM_AccInSta 0 "Acc Off" 1 "Acc On" 2 "Not Used" 3 "Error Indicator" ;
VAL_ 992 BCM_Ign1InSta 0 "IGN1 Off" 1 "IGN1 On" 2 "Not Used" 3 "Error Indicator" ;
VAL_ 992 BCM_Ign2InSta 0 "IGN2 Off" 1 "IGN2 On" 2 "Not Used" 3 "Error Indicator" ;
VAL_ 992 Warn_LftSEA_BDC 0 "SEA Left Warning Off" 1 "SEA Left Warning On" 2 "Not Used" 3 "Error Indicator" ;
VAL_ 992 Warn_RhtSEA_BDC 0 "SEA Right Warning Off" 1 "SEA Right Warning On" 2 "Not Used" 3 "Error Indicator" ;
VAL_ 994 Warn_BzrWrngSta 0 "Off" 1 "SeatBelt Warning" 2 "Key Operated Warning" 3 "Parking Brake Warning" 4 "Sun Roof Open Warning" 5 "Key Learning Sound(NoSMKOption" 6 "ICE Warning" 7 "Rear Fog Warning" 8 "Reserved" 9 "Reserved" 10 "Reserved" 11 "Reserved" 12 "Reserved" 13 "Reserved" 14 "Not Used" 15 "Error Indicator" ;
VAL_ 994 Warn_BCMWrngSta 0 "Off" 1 "Power off request warning" 2 "Shift P request Warning" 3 "Reserved" 4 "Reserved" 5 "Reseved" 6 "Reseved" 7 "Reserved" 8 "Reserved" 9 "Reserved" 10 "Reserved" 11 "Reserved" 12 "Reserved" 13 "Reserved" 14 "Not Used" 15 "Error Indicator" ;
VAL_ 994 ROA_RrBlwAutoOffReq 0 "default" 1 "Request of Rear Blow Off (auto Cut)" 2 "Not Used" 3 "Error Indciator" ;
VAL_ 994 ROA_RegionOpt 0 "Non Euro NCAP CPD" 1 "Euro NCAP CPD" 2 "Reserved" 3 "Error Indicator" ;
VAL_ 994 Warn_RrStRmndOpt 0 "Not apply RrSeatRemind" 1 "Apply RrSeatRemind" 2 "Apply Radar ROA sensor" 3 "Error Indicator" ;
VAL_ 994 Warn_RrStRmndAlrmOnReq 0 "Off" 1 "On(Alarm)" 2 "Not Used" 3 "Error Indicator" ;
VAL_ 994 Warn_RrStRmndSysSta 0 "Default" 1 "System ON" 2 "System OFF" 3 "Error Indicator" ;
VAL_ 994 Warn_RrStRmndAlrmInfo 0 "Off" 1 "Rear Seat Reminder" 2 "Rear Seat Reminder 1st Only" 3 "Reserved" 4 "Reserved" 5 "Reseved" 6 "Not Used" 7 "Error Indicator" ;
VAL_ 994 Warn_RoaErr 0 "Off" 1 "SensorError( Malfunction)" 2 "Reserved" 3 "Reserved" 4 "Reserved" 5 "Reseved" 6 "Not Used" 7 "Error Indicator" ;
VAL_ 994 IBU_RrStRmndAlrmSta 0 "No Alarm" 1 "Alarm in Progress" 2 "Alarm Cycle Complete" 3 "Alarm Stop" 4 "Reserved" 5 "Reserved" 6 "Reserved" 7 "Error Indicator" ;
VAL_ 994 WAL_FobSearching 0 "Not Fob Exist" 1 "Fob Exist" 2 "Reserved" 3 "Error Indicator" ;
VAL_ 997 PDW_OptTyp 0 "Non" 1 "PDW R" 2 "PDW FR" 3 "Reserved" 4 "PDW-R (w/ 1st Corner Warning)" 5 "PDW-FR (w/ 1st Corner Warning)" 6 "Not Used" 7 "Error Indicator" ;
VAL_ 997 PDW_SysChkSndSta 0 "Off" 1 "R_Confirm" 2 "Error" 3 "Reserved" 4 "Reserved" 5 "Reseved" 6 "Not Used" 7 "Error Indicator" ;
VAL_ 997 PDW_SwIndOnReq 0 "Indicator Off" 1 "Indicator On" 2 "Not Used" 3 "Error Indicator" ;
VAL_ 997 PDW_SysOnSta 0 "Off" 1 "On" 2 "Reserved" 3 "Reserved" 4 "Reserved" 5 "Reseved" 6 "Not Used" 7 "Error Indicator" ;
VAL_ 997 PDW_FrCtWrngLvlDis 0 "Off" 1 "1st warning" 2 "2nd warning" 3 "3rd warning" 4 "Error" 5 "Gray" 6 "Not Used" 7 "Error Indicator" ;
VAL_ 997 PDW_SysFlrSta 0 "No Display" 1 "Unable by Ultrasonic" 2 "PDW Failure" 3 "Error Indicator" ;
VAL_ 997 PDW_FrCtWrngSndSta 0 "Off" 1 "1st warning" 2 "2nd warning" 3 "3rd warning" 4 "Reserved" 5 "Reseved" 6 "Not Used" 7 "Error Indicator" ;
VAL_ 997 PDW_FrLtWrngLvlDis 0 "Off" 1 "1st warning" 2 "2nd warning" 3 "3rd warning" 4 "Error" 5 "Gray" 6 "Not Used" 7 "Error Indicator" ;
VAL_ 997 PDW_CRBdDis 0 "Normal (No display)" 1 "Car Body Display" 2 "Reserved" 3 "Error Indicator" ;
VAL_ 997 PDW_FrLtWrngSndSta 0 "Off" 1 "1st warning" 2 "2nd warning" 3 "3rd warning" 4 "Reserved" 5 "Reseved" 6 "Not Used" 7 "Error Indicator" ;
VAL_ 997 PDW_FrRtWrngLvlDis 0 "Off" 1 "1st warning" 2 "2nd warning" 3 "3rd warning" 4 "Error" 5 "Gray" 6 "Not Used" 7 "Error Indicator" ;
VAL_ 997 PDW_FrRtWrngSndSta 0 "Off" 1 "1st warning" 2 "2nd warning" 3 "3rd warning" 4 "Reserved" 5 "Reseved" 6 "Not Used" 7 "Error Indicator" ;
VAL_ 997 PDW_FrSnsrWrngLvlSta 0 "Off" 1 "1st Waring" 2 "2nd Waring" 3 "3rd Warning" 4 "Reserved" 5 "Reseved" 6 "Not Used" 7 "Error Indicator" ;
VAL_ 1002 BLTN_CAM_HU_UI_Mode 0 "HU UI mode." 1 "BLTN_CAM mode" 2 "Preparing BLTN_CAM Mode" 3 "Reserved" 4 "Reserved" 5 "Reserved" 6 "Reserved" 7 "Reserved" 8 "Reserved" 9 "Reserved" 10 "Reserved" 11 "Reserved" 12 "Reserved" 13 "Reserved" 14 "BLTN_CAM is in error mode." 15 "invalid" ;
VAL_ 1002 BLTN_CAM_SD_Format_Op_State 0 "Default" 1 "Formatting" 2 "Format Complete." 3 "invalid" ;
VAL_ 1002 BLTN_CAM_PEV_Recorded 0 "Default" 1 "Off" 2 "Park Event Recorded" 3 "invalid" ;
VAL_ 1002 BLTN_CAM_PEV_Count 0 "0x0x0~0xC8:the number of the Park Event Record(0~200)" 200 "0x0x0~0xC8:the number of the Park Event Record(0~200)" 201 "Reserved" 202 "Reserved" 203 "Reserved" 204 "Reserved" 205 "Reserved" 206 "Reserved" 207 "Reserved" 208 "Reserved" 209 "Reserved" 210 "Reserved" 211 "Reserved" 212 "Reserved" 213 "Reserved" 214 "Reserved" 215 "Reserved" 216 "Reserved" 217 "Reserved" 218 "Reserved" 219 "Reserved" 220 "Reserved" 221 "Reserved" 222 "Reserved" 223 "Reserved" 224 "Reserved" 225 "Reserved" 226 "Reserved" 227 "Reserved" 228 "Reserved" 229 "Reserved" 230 "Reserved" 231 "Reserved" 232 "Reserved" 233 "Reserved" 234 "Reserved" 235 "Reserved" 236 "Reserved" 237 "Reserved" 238 "Reserved" 239 "Reserved" 240 "Reserved" 241 "Reserved" 242 "Reserved" 243 "Reserved" 244 "Reserved" 245 "Reserved" 246 "Reserved" 247 "Reserved" 248 "Reserved" 249 "Reserved" 250 "Reserved" 251 "Reserved" 252 "Reserved" 253 "Over than 200 count" 254 "the park event record is not recorded" 255 "invalid" ;
VAL_ 1002 BLTN_CAM_Ind_Req 0 "Default" 1 "Built-in Cam System or Camera Error" 2 "Manual Recording or Event Recording" 3 "Time-lapse Recording" 4 "Built-in Cam SD Card Replace Warning or SD Card Error" 5 "On while Driving Recording" 6 "On while Parked Recording" 7 "Reserved" 8 "Reserved" 9 "Reserved" 10 "Reserved" 11 "Reserved" 12 "Reserved" 13 "Reserved" 14 "Reserved" 15 "Reserved" 16 "Reserved" 17 "Reserved" 18 "Reserved" 19 "Reserved" 20 "Reserved" 21 "Reserved" 22 "Reserved" 23 "Reserved" 24 "Reserved" 25 "Reserved" 26 "Reserved" 27 "Reserved" 28 "Reserved" 29 "Reserved" 30 "Reserved" 31 "Invalid" ;
VAL_ 1002 BLTN_CAM_LVDS_Mode_State 0 "Front and Rear Camera" 1 "Front Camera for AR Navi." 2 "Built-In Cam Engineer Mode" 3 "Reserved" ;
VAL_ 1002 BLTN_CAM_PrkOp_Termiate_Info 0 "Default" 1 "Park operation terminated earlier than user set because of Bat. SoC" 2 "Park operation terminated earlier than user set because of SD Card Problem" 3 "Park operation terminated earlier than user set because of Built-in Cam internal Error" 4 "Park operation terminated earlier than user set because of SD Card removed or not detected" 5 "Park operation started because of SD Card inserted" 6 "Park operation terminate on time which user set." 7 "Invalid" ;
VAL_ 1002 BLTN_CAM_Display 0 "HU mode" 1 "Built-in Cam mode" 2 "popup mode" 3 "Built-in Cam mode Terminate Request by Home-button" 4 "Built-in Cam mode Terminate Request by Back-button" 5 "Built-in Cam update mode" 6 "Ready to update" 7 "Update complete" 8 "USB removed" 9 "Update fail (USB error)" 10 "Reserved" 11 "Reserved" 12 "Reserved" 13 "Reserved" 14 "Built-in Cam is in error mode" 15 "Invalid" ;
VAL_ 1002 BLTN_CAM_WiFi_State 0 "Off" 1 "On, Ready to Connect Mobile Phone." 2 "On, Mobile Phone Connected." 3 "Off - Password is not Set." 4 "Reserved" 5 "Reserved" 6 "Reserved" 7 "Reserved" 8 "Reserved" 9 "Reserved" 10 "Reserved" 11 "Reserved" 12 "Reserved" 13 "Reserved" 14 "Reserved" 15 "invalid" ;
VAL_ 2353206529 CLU_SndType 0 "Cluster applied speaker" 1 "Cluster applied buzzer" 2 "Not used" 3 "Error Indicator" ;
VAL_ 2353206529 CLU_ClusterUSM 0 "Default" 1 "Cluster not applied USM" 2 "Cluster applied USM" 3 "Reserved" ;
VAL_ 1016 GNSS_MM_type 0 "WGS84" 1 "Bessel" 2 "Coordshift(for china)" 15 "invalid" ;
VAL_ 1019 HU_MoodTherapyDrSeat 0 "Default" 1 "Off" 2 "On" 3 "Invalid" ;
VAL_ 1019 HU_VitalityFragrance 0 "Default" 1 "Off" 2 "On" 3 "Invalid" ;
VAL_ 1019 HU_VitalityCurtain 0 "Default" 1 "Off" 2 "On" 3 "Invalid" ;
VAL_ 1019 HU_DelightMoodLamp 0 "Default" 1 "Off" 2 "On" 3 "Invalid" ;
VAL_ 1019 HU_DelightFragrance 0 "Default" 1 "Off" 2 "On" 3 "Invalid" ;
VAL_ 1019 HU_DelightCurtain 0 "Default" 1 "Off" 2 "On" 3 "Invalid" ;
VAL_ 1019 HU_MoodTherapyPsSeat 0 "Default" 1 "Off" 2 "On" 3 "Invalid" ;
VAL_ 1019 HU_CareMoodLamp 0 "Default" 1 "Off" 2 "On" 3 "Invalid" ;
VAL_ 1019 HU_CareFragrance 0 "Default" 1 "Off" 2 "On" 3 "Invalid" ;
VAL_ 1019 HU_CareMassage 0 "Default" 1 "Off" 2 "On" 3 "Invalid" ;
VAL_ 1019 HU_CareCurtain 0 "Default" 1 "Off" 2 "On" 3 "Invalid" ;
VAL_ 1019 HU_ComfortMoodLamp 0 "Default" 1 "Off" 2 "On" 3 "Invalid" ;
VAL_ 1019 HU_ComfortFragrance 0 "Default" 1 "Off" 2 "On" 3 "Invalid" ;
VAL_ 1019 HU_ComfortMassage 0 "Default" 1 "Off" 2 "On" 3 "Invalid" ;
VAL_ 1019 HU_ComfortCurtain 0 "Default" 1 "Off" 2 "On" 3 "Invalid" ;
VAL_ 1019 HU_MoodTherapyMode 0 "Default" 1 "Off" 2 "Vitality" 3 "Delight" 4 "Care" 5 "Comfort" 6 "Reserved" 7 "Invalid" ;
VAL_ 1019 HU_MoodTherapyRlSeat 0 "Default" 1 "Off" 2 "On" 3 "Invalid" ;
VAL_ 1019 HU_MoodTherapyRrSeat 0 "Default" 1 "Off" 2 "On" 3 "Invalid" ;
VAL_ 1019 HU_VitalityMoodLamp 0 "Default" 1 "Off" 2 "On" 3 "Invalid" ;
VAL_ 2382595329 DMIC_OffRdMod 0 "Default" 1 "Snow" 2 "Sand" 3 "Mud" 4 "Not used" 5 "Not used" 6 "Not used" 7 "Error Indicator" ;
VAL_ 2382595329 DMIC_OffRdModActvSta 0 "ONROAD" 1 "OFFROAD" 2 "Not used" 3 "Error Indicator" ;
VAL_ 2382595329 DMIC_OffRdModSta 0 "Selected Mode" 1 "Changed Mode" 2 "Not used" 3 "Error Indicator" ;
VAL_ 1004 CF_RCS_SwTyp 0 "Not Endless Dial" 1 "Endless Dial (CAN)" ;
VAL_ 1004 CF_RCS_OffRoad 0 "DEFAULT" 1 "SNOW" 2 "SAND" 3 "MUD" 4 "AUTO" ;
VAL_ 1004 CF_RCS_BtnSta 0 "OnRoad" 1 "OffRoad" ;
VAL_ 1004 CF_RCS_RotateEnd 0 "Default" 1 "Rotate End" ;
VAL_ 1004 CF_RCS_4wdLocking 0 "Off" 1 "On" ;
VAL_ 1004 CF_RCS_DrvMod 0 "NORMAL(COMFORT)" 1 "ECO" 2 "SPORT" 3 "SMART" ;
VAL_ 1003 PSM_BzrOnRLReq 0 "off" 1 "on" 2 "Not Used" 3 "Error Indicator" ;
VAL_ 1003 RLPSM_RearModeState 0 "Default" 1 "Off" 2 "Relax Mode" 3 "Return Mode" 4 "RESERVED" 5 "RESERVED" 6 "RESERVED" 7 "Invalid" ;
VAL_ 1003 RLPSM_RrLfSldStrtSta 0 "OFF" 1 "ON(SLIDE START)" 2 "STOP" 3 "FINISH" ;
VAL_ 1003 RLPSM_OptTyp 0 "Off" 1 "Applied" 2 "Not Used" 3 "Error Indicator" ;
VAL_ 1003 RLPSM_RLStEsyAcsUSMSta 0 "Default" 1 "Off" 2 "On" 3 "Invalid" ;
VAL_ 1003 RLPSM_FnshSta 0 "None" 1 "Relax finish" 2 "Return finish" 3 "Invalid" ;
VAL_ 1003 RLPSM_AllSeatPosPlyBck_Sta 0 "Default" 1 "Moving" 2 "Moving Finish" 3 "Moving Not Finish" 4 "Not Used" 5 "Not Used" 6 "Stop" 7 "Not Used" ;
VAL_ 1003 RLPSM_RLSlidePosition 0 "0x0x00~0xFE:POSITION" 254 "0x0x00~0xFE:POSITION" 255 "invalid" ;
VAL_ 1003 RLPSM_SeatPos_Sta 0 "Default" 1 "Memory1" 2 "Memory2" 3 "Memory3" 4 "Not Used" 5 "Not Used" 6 "Not Used" 7 "Any Postion" ;
VAL_ 1003 RLPSM_SeatPosSldLmt_Sta 0 "Default" 1 "Slide Fwd Limit" 2 "Slide Bwd Limit" 3 "Not Initialized" ;
VAL_ 1003 RLPSM_Enable_Sta 0 "Default" 1 "Enable" 2 "Disable_3km" 3 "Disable_Low Voltage" 4 "Not Used" 5 "Not Used" 6 "Not Used" 7 "Not Used" ;
VAL_ 1003 RLPSM_MvSta 0 "None" 1 "Relax" 2 "Return" 3 "Invalid" ;
VAL_ 1003 RLPSM_Mem1_Sta 0 "Default" 1 "Memory1" 2 "No Memory" 3 "Not used" ;
VAL_ 1003 RLPSM_Mem2_Sta 0 "Default" 1 "Memory2" 2 "No Memory" 3 "Not Used" ;
VAL_ 1003 RLPSM_Mem3_Sta 0 "Default" 1 "Memory3" 2 "No Memory" 3 "Not Used" ;
VAL_ 1003 RLPSM_LimSetSta 0 "Default" 1 "Initialized" 2 "Not Initialized" 3 "Reserved" ;
VAL_ 1003 PSM_RrLftSldPosVal 0 "0¡Âx¡Â50" 1 "50<x¡Â100" 2 "reserved" 3 "invalid" ;
VAL_ 1003 PSM_SldStrtSta 0 "OFF" 1 "ON (SLIDE START)" 2 "STOP" 3 "FINISH" ;
VAL_ 1005 RLPSU_FldDis 0 "default" 1 "Off" 2 "On" 3 "Invalid" ;
VAL_ 1005 RLPSU_TiltDownDis 0 "default" 1 "Off" 2 "On" 3 "Invalid" ;
VAL_ 1005 RLPSU_RclFwdDis 0 "default" 1 "Off" 2 "On" 3 "Invalid" ;
VAL_ 1005 RLPSU_RclBwdDis 0 "default" 1 "Off" 2 "On" 3 "Invalid" ;
VAL_ 1005 RLPSU_RlxModeDis 0 "default" 1 "Off" 2 "On" 3 "Invalid" ;
VAL_ 1005 RLPSU_Folding_SW 0 "default" 1 "Off" 2 "On" 3 "Invalid" ;
VAL_ 1005 RLPSU_UnFldDis 0 "default" 1 "Off" 2 "On" 3 "Invalid" ;
VAL_ 1005 RLPSU_Unfolding_SW 0 "default" 1 "Off" 2 "On" 3 "Invalid" ;
VAL_ 1005 RLPSU_WalkIn_SW 0 "default" 1 "Off" 2 "On" 3 "Invalid" ;
VAL_ 1005 RLPSU_UnwalkIn_SW 0 "default" 1 "Off" 2 "On" 3 "Invalid" ;
VAL_ 1005 RLPSU_Folding_Postion 0 "deafult" 1 "Walk In" 2 "Unwalk In" 3 "Walk In(Moving)" 4 "Unwalk In(Moving)" 5 "Folded" 6 "UnFolded" 7 "Folding (Moving)" 8 "UnFolding (Moving)" 9 "RESERVED" 10 "RESERVED" 11 "RESERVED" 12 "RESERVED" 13 "RESERVED" 14 "RESERVED" 15 "Invalid" ;
VAL_ 1005 RLPSU_Folding_State_PopUp 0 "Default" 1 "Folded(finished)" 2 "Unfolded(finished)" 3 "Mode-fail (anti-pinch)" 4 "Mode-fail (TGS&Break Condition)" 5 "Mode-fail (system error)" 6 "RESERVED" 7 "Invalid" ;
VAL_ 1005 RLPSU_Relax_State_Popup 0 "Default" 1 "Relaxed(finished)" 2 "Unrelaxed(finished)" 3 "Relax (Relaxing)" 4 "Return (Returning)" 5 "RESERVED" 6 "RESERVED" 7 "Invalid" ;
VAL_ 1005 RLPSU_SlideFwdDis 0 "default" 1 "Off" 2 "On" 3 "Invalid" ;
VAL_ 1005 RLPSU_SlideBwdDis 0 "default" 1 "Off" 2 "On" 3 "Invalid" ;
VAL_ 1005 RLPSU_WalkInDis 0 "default" 1 "Off" 2 "On" 3 "Inavlid" ;
VAL_ 1005 RLPSU_WalkInState 0 "default" 1 "Enable" 2 "Disable" 3 "Invalid" ;
VAL_ 1005 RLPSU_UnWalkInDis 0 "default" 1 "Off" 2 "On" 3 "Invalid" ;
VAL_ 1005 RLPSU_TiltUpDis 0 "default" 1 "Off" 2 "On" 3 "Invalid" ;
VAL_ 1006 RRPSU_FldDis 0 "default" 1 "Off" 2 "On" 3 "Invalid" ;
VAL_ 1006 RRPSU_TiltDnDis 0 "default" 1 "Off" 2 "On" 3 "Invalid" ;
VAL_ 1006 RRPSU_RecFwdDis 0 "default" 1 "Off" 2 "On" 3 "Invalid" ;
VAL_ 1006 RRPSU_RecBwdDis 0 "default" 1 "Off" 2 "On" 3 "Invalid" ;
VAL_ 1006 RRPSU_RlxModeDis 0 "default" 1 "Off" 2 "On" 3 "Invalid" ;
VAL_ 1006 RRPSU_Folding_SW 0 "default" 1 "Off" 2 "On" 3 "Invalid" ;
VAL_ 1006 RRPSU_UnFldDis 0 "default" 1 "Off" 2 "On" 3 "Invalid" ;
VAL_ 1006 RRPSU_Unfolding_SW 0 "default" 1 "Off" 2 "On" 3 "Invalid" ;
VAL_ 1006 RRPSU_WalkIn_SW 0 "default" 1 "Off" 2 "On" 3 "Invalid" ;
VAL_ 1006 RRPSU_UnwalkIn_SW 0 "default" 1 "Off" 2 "On" 3 "Invalid" ;
VAL_ 1006 RRPSU_Folding_Postion 0 "deafult" 1 "Walk In" 2 "Unwalk In" 3 "Walk In(Moving)" 4 "Unwalk In(Moving)" 5 "Folded" 6 "UnFolded" 7 "Folding (Moving)" 8 "UnFolding (Moving)" 9 "Unused" 10 "Unused" 11 "Unused" 12 "Unused" 13 "Unused" 14 "Unused" 15 "Invalid" ;
VAL_ 1006 RRPSU_Folding_State_Popup 0 "Default" 1 "Relaxed(finished)" 2 "Unfolded(finished)" 3 "Mode-fail(anti-pinch)" 4 "Mode-Fail(TGS&Break Condition)" 5 "Mode-fail(system error)" 6 "Unused" 7 "Invalid" ;
VAL_ 1006 RRPSU_Relax_State_Popup 0 "Default" 1 "Relaxed(finished)" 2 "UnRelaxed(finished)" 3 "Relax (Relaxing)" 4 "Return(Returning)" 5 "Unused" 6 "Unused" 7 "Invalid" ;
VAL_ 1006 RRPSU_SlideFwdDis 0 "default" 1 "Off" 2 "On" 3 "Invalid" ;
VAL_ 1006 RRPSU_SlideBwdDis 0 "default" 1 "Off" 2 "On" 3 "Invalid" ;
VAL_ 1006 RRPSU_WalkinDis 0 "default" 1 "Off" 2 "On" 3 "Invalid" ;
VAL_ 1006 RRPSU_WalkInState 0 "default" 1 "Enable" 2 "Disable" 3 "Invalid" ;
VAL_ 1006 RRPSU_UnwalkinDis 0 "default" 1 "Off" 2 "On" 3 "Invalid" ;
VAL_ 1006 RRPSU_TiltUpDis 0 "default" 1 "Off" 2 "On" 3 "Invalid" ;
VAL_ 2223056129 SAS_AnglVal 0 "0x0x0000~0x7FFE:real value" 32766 "0x0x0000~0x7FFE:real value" 32767 "Error Indicator" 32768 "0x8000~0xFFFF:real value" 65535 "0x8000~0xFFFF:real value" ;
VAL_ 2223056129 SAS_SpdVal 0 "0x0x00~0xFE:real value" 254 "0x0x00~0xFE:real value" 255 "Error Indicator" ;
VAL_ 2223056129 SAS_IntSta 0 "real vaule" 1 "real vaule" 2 "real vaule" 3 "real vaule" 4 "real vaule" 5 "real vaule" 6 "real vaule" 7 "real vaule" 8 "real vaule" 9 "real vaule" 10 "real vaule" 11 "real vaule" 12 "real vaule" 13 "real vaule" 14 "real vaule" 15 "real vaule" 16 "0x10~0xFF:RESERVED" 255 "0x10~0xFF:RESERVED" ;
VAL_ 463 SWRC_CrsSwSta 0 "Idle Position" 1 "Plus/Set" 2 "Minus/Set" 3 "Time gap (Distance, SCC only)" 4 "Pause/Resume" 5 "RESERVED" 6 "RESERVED" 7 "RESERVED" ;
VAL_ 463 SWRC_CrsMainSwSta 0 "Off" 1 "Key On" 2 "RESERVED" 3 "Invalid" ;
VAL_ 463 SWRC_SldMainSwSta 0 "Off" 1 "Key On" 2 "Reserved" 3 "Invalid" ;
VAL_ 463 SWRC_LFASwSta 0 "Off" 1 "Key On" 2 "RESERVED" 3 "Invalid" ;
VAL_ 463 SWRC_PaddleUpSwSta 0 "Off" 1 "Key On" 2 "Reserved" 3 "Invalid" ;
VAL_ 463 SWRC_PaddleDnSwSta 0 "Off" 1 "Key On" 2 "Reserved" 3 "Invalid" ;
VAL_ 463 SWRC_Info 0 "Off" 1 "ON(CAN Type)" 2 "RESERVED" 3 "Error Indicator" ;
VAL_ 463 SWRC_HdpSwSta 0 "Off" 1 "Key On" 2 "Reserved" 3 "Invalid" ;
